VERSION "HNPBNNNYNNNNNNNNNNNNNNNNNNNNNNNNYNYYYYYYYY>4>%%%/4>'%**4YYY///"

NS_ :

BS_:

BU_: ExternalUnit ARS_ISF ARS_ISF1 ARS_ISF2 ARS_ISF3 ARS_ISF4 ARS_ISF5 ARS_ISF6 ARS_ISF7

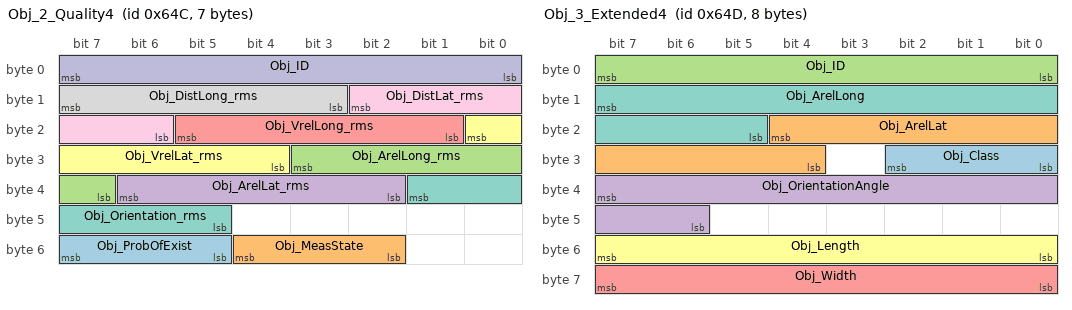
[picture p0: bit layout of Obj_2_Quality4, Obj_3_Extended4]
BO_ 1612 Obj_2_Quality4: 7 ARS_ISF4
 SG_ Obj_ProbOfExist : 55|3@0+ (1,0) [0|7] ""  ExternalUnit
 SG_ Obj_MeasState : 52|3@0+ (1,0) [0|7] ""  ExternalUnit
 SG_ Obj_ArelLong_rms : 27|5@0+ (1,0) [0|31] ""  ExternalUnit
 SG_ Obj_ArelLat_rms : 38|5@0+ (1,0) [0|31] ""  ExternalUnit
 SG_ Obj_VrelLong_rms : 21|5@0+ (1,0) [0|31] ""  ExternalUnit
 SG_ Obj_VrelLat_rms : 16|5@0+ (1,0) [0|31] ""  ExternalUnit
 SG_ Obj_Orientation_rms : 33|5@0+ (1,0) [0|31] ""  ExternalUnit
 SG_ Obj_DistLong_rms : 15|5@0+ (1,0) [0|31] ""  ExternalUnit
 SG_ Obj_DistLat_rms : 10|5@0+ (1,0) [0|31] ""  ExternalUnit
 SG_ Obj_ID : 7|8@0+ (1,0) [0|255] ""  ExternalUnit

BO_ 1613 Obj_3_Extended4: 8 ARS_ISF4
 SG_ Obj_Class : 26|3@0+ (1,0) [0|7] ""  ExternalUnit
 SG_ Obj_ArelLat : 20|9@0+ (0.01,-2.5) [-2.5|2.61] "m/s²"  ExternalUnit
 SG_ Obj_ID : 7|8@0+ (1,0) [0|255] ""  ExternalUnit
 SG_ Obj_OrientationAngle : 39|10@0+ (0.4,-180) [-180|229.2] "deg"  ExternalUnit
 SG_ Obj_Width : 63|8@0+ (0.2,0) [0|51] "m"  ExternalUnit
 SG_ Obj_Length : 55|8@0+ (0.2,0) [0|51] "m"  ExternalUnit
 SG_ Obj_ArelLong : 15|11@0+ (0.01,-10) [-10|10.47] "m/s²"  ExternalUnit

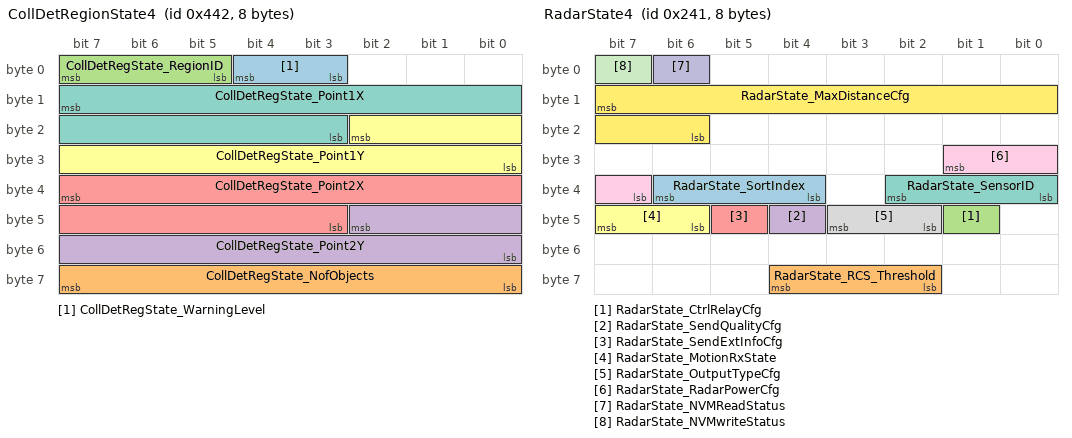
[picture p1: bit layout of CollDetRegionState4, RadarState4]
BO_ 1090 CollDetRegionState4: 8 ARS_ISF4
 SG_ CollDetRegState_WarningLevel : 4|2@0+ (1,0) [0|3] ""  ExternalUnit
 SG_ CollDetRegState_NofObjects : 63|8@0+ (1,0) [0|255] ""  ExternalUnit
 SG_ CollDetRegState_RegionID : 7|3@0+ (1,0) [0|7] ""  ExternalUnit
 SG_ CollDetRegState_Point2Y : 42|11@0+ (0.2,-204.6) [-204.6|204.8] "m"  ExternalUnit
 SG_ CollDetRegState_Point2X : 39|13@0+ (0.2,-500) [-500|1138.2] "m"  ExternalUnit
 SG_ CollDetRegState_Point1Y : 18|11@0+ (0.2,-204.6) [-204.6|204.8] "m"  ExternalUnit
 SG_ CollDetRegState_Point1X : 15|13@0+ (0.2,-500) [-500|1138.2] "m"  ExternalUnit

BO_ 1614 Obj_4_Warning4: 4 ARS_ISF4
 SG_ Obj_CollDetRegionBitfield : 15|8@0+ (1,0) [0|255] ""  ExternalUnit
 SG_ Obj_ID : 7|8@0+ (1,0) [0|255] ""  ExternalUnit

BO_ 580 FilterState_Cfg4: 5 ARS_ISF4
 SG_ FilterState_Max_Class m15 : 39|8@0+ (1,0) [0|255] ""  ExternalUnit
 SG_ FilterState_Min_Class m15 : 23|8@0+ (1,0) [0|255] ""  ExternalUnit
 SG_ FilterState_Min_Y m9 : 11|12@0+ (0.2,-409.5) [-409.5|409.5] "m"  ExternalUnit
 SG_ FilterState_Min_X m10 : 12|13@0+ (0.2,-500) [-500|1138.2] "m"  ExternalUnit
 SG_ FilterState_Min_VYRightLeft m13 : 11|12@0+ (0.0315,0) [0|128.9925] "m/s"  ExternalUnit
 SG_ FilterState_Min_VYLeftRight m11 : 11|12@0+ (0.0315,0) [0|128.9925] "m/s"  ExternalUnit
 SG_ FilterState_Min_VXOncome m12 : 11|12@0+ (0.0315,0) [0|128.9925] "m/s"  ExternalUnit
 SG_ FilterState_Min_VXDepart m14 : 11|12@0+ (0.0315,0) [0|128.9925] "m/s"  ExternalUnit
 SG_ FilterState_Max_Y m9 : 27|12@0+ (0.2,-409.5) [-409.5|409.5] "m"  ExternalUnit
 SG_ FilterState_Max_X m10 : 28|13@0+ (0.2,-500) [-500|1138.2] "m"  ExternalUnit
 SG_ FilterState_Max_VYRightLeft m13 : 27|12@0+ (0.0315,0) [0|128.9925] "m/s"  ExternalUnit
 SG_ FilterState_Max_VYLeftRight m11 : 27|12@0+ (0.0315,0) [0|128.9925] "m/s"  ExternalUnit
 SG_ FilterState_Max_VXOncome m12 : 27|12@0+ (0.0315,0) [0|128.9925] "m/s"  ExternalUnit
 SG_ FilterState_Max_VXDepart m14 : 27|12@0+ (0.0315,0) [0|128.9925] "m/s"  ExternalUnit
 SG_ FilterState_Type : 7|1@0+ (1,0) [0|1] ""  ExternalUnit
 SG_ FilterState_Min_VrelOncome m3 : 11|12@0+ (0.0315,0) [0|128.9925] "m/s"  ExternalUnit
 SG_ FilterState_Min_VrelDepart m4 : 11|12@0+ (0.0315,0) [0|128.9925] "m/s"  ExternalUnit
 SG_ FilterState_Min_Size m7 : 11|12@0+ (0.025,0) [0|102.375] "m2"  ExternalUnit
 SG_ FilterState_Min_RCS m5 : 11|12@0+ (0.025,-50) [-50|52.375] "dB"  ExternalUnit
 SG_ FilterState_Min_ProbExists m8 : 11|12@0+ (1,0) [0|7] ""  ExternalUnit
 SG_ FilterState_Min_NofObj m0 : 11|12@0+ (1,0) [0|4095] ""  ExternalUnit
 SG_ FilterState_Min_Lifetime m6 : 11|12@0+ (0.1,0) [0|409.5] "s"  ExternalUnit
 SG_ FilterState_Min_Distance m1 : 11|12@0+ (0.1,0) [0|409.5] "m"  ExternalUnit
 SG_ FilterState_Min_Azimuth m2 : 11|12@0+ (0.025,-50) [-50|52.375] "deg"  ExternalUnit
 SG_ FilterState_Max_VrelOncome m3 : 27|12@0+ (0.0315,0) [0|128.9925] "m/s"  ExternalUnit
 SG_ FilterState_Max_VrelDepart m4 : 27|12@0+ (0.0315,0) [0|128.9925] "m/s"  ExternalUnit
 SG_ FilterState_Max_Size m7 : 27|12@0+ (0.025,0) [0|102.375] "m2"  ExternalUnit
 SG_ FilterState_Max_RCS m5 : 27|12@0+ (0.025,-50) [-50|52.375] "dB"  ExternalUnit
 SG_ FilterState_Max_ProbExists m8 : 27|12@0+ (1,0) [0|4095] ""  ExternalUnit
 SG_ FilterState_Max_NofObj m0 : 27|12@0+ (1,0) [0|4095] ""  ExternalUnit
 SG_ FilterState_Max_Lifetime m6 : 27|12@0+ (0.1,0) [0|409.5] "s"  ExternalUnit
 SG_ FilterState_Max_Distance m1 : 27|12@0+ (0.1,0) [0|409.5] "m"  ExternalUnit
 SG_ FilterState_Max_Azimuth m2 : 27|12@0+ (0.025,-50) [-50|52.375] "deg"  ExternalUnit
 SG_ FilterState_Index M : 6|4@0+ (1,0) [0|15] ""  ExternalUnit
 SG_ FilterState_Active : 2|1@0+ (1,0) [0|1] ""  ExternalUnit

BO_ 579 FilterState_Header4: 2 ARS_ISF4
 SG_ FilterState_NofObjectFilterCfg : 15|5@0+ (1,0) [0|31] ""  ExternalUnit
 SG_ FilterState_NofClusterFilterCfg : 7|5@0+ (1,0) [0|31] ""  ExternalUnit

BO_ 578 FilterCfg4: 5 ExternalUnit
 SG_ FilterCfg_Min_Class m15 : 23|8@0+ (1,0) [0|255] ""  ARS_ISF4
 SG_ FilterCfg_Max_Class m15 : 39|8@0+ (1,0) [0|255] ""  ARS_ISF4
 SG_ FilterCfg_Min_Y m9 : 11|12@0+ (0.2,-409.5) [-409.5|409.5] "m"  ARS_ISF4
 SG_ FilterCfg_Min_X m10 : 12|13@0+ (0.2,-500) [-500|1138.2] "m"  ARS_ISF4
 SG_ FilterCfg_Min_VYRightLeft m13 : 11|12@0+ (0.0315,0) [0|128.9925] "m/s"  ARS_ISF4
 SG_ FilterCfg_Min_VYLeftRight m11 : 11|12@0+ (0.0315,0) [0|128.9925] "m/s"  ARS_ISF4
 SG_ FilterCfg_Min_VXOncome m12 : 11|12@0+ (0.0315,0) [0|128.9925] "m/s"  ARS_ISF4
 SG_ FilterCfg_Min_VXDepart m14 : 11|12@0+ (0.0315,0) [0|128.9925] "m/s"  ARS_ISF4
 SG_ FilterCfg_Max_Y m9 : 27|12@0+ (0.2,-409.5) [-409.5|409.5] "m"  ARS_ISF4
 SG_ FilterCfg_Max_X m10 : 28|13@0+ (0.2,-500) [-500|1138.2] "m"  ARS_ISF4
 SG_ FilterCfg_Max_VYRightLeft m13 : 27|12@0+ (0.0315,0) [0|128.9925] "m/s"  ARS_ISF4
 SG_ FilterCfg_Max_VXOncome m12 : 27|12@0+ (0.0315,0) [0|128.9925] "m/s"  ARS_ISF4
 SG_ FilterCfg_Max_VYLeftRight m11 : 27|12@0+ (0.0315,0) [0|128.9925] "m/s"  ARS_ISF4
 SG_ FilterCfg_Max_VXDepart m14 : 27|12@0+ (0.0315,0) [0|128.9925] "m/s"  ARS_ISF4
 SG_ FilterCfg_Valid : 1|1@0+ (1,0) [0|1] ""  ARS_ISF4
 SG_ FilterCfg_Active : 2|1@0+ (1,0) [0|1] ""  ARS_ISF4
 SG_ FilterCfg_Max_VrelOncome m3 : 27|12@0+ (0.0315,0) [0|128.9925] "m/s"  ARS_ISF4
 SG_ FilterCfg_Max_VrelDepart m4 : 27|12@0+ (0.0315,0) [0|128.9925] "m/s"  ARS_ISF4
 SG_ FilterCfg_Max_Size m7 : 27|12@0+ (0.025,0) [0|102.375] "m2"  ARS_ISF4
 SG_ FilterCfg_Max_RCS m5 : 27|12@0+ (0.025,-50) [-50|52.375] "dB"  ARS_ISF4
 SG_ FilterCfg_Max_ProbExists m8 : 27|12@0+ (1,0) [0|7] ""  ARS_ISF4
 SG_ FilterCfg_Max_NofObj m0 : 27|12@0+ (1,0) [0|4095] ""  ARS_ISF4
 SG_ FilterCfg_Max_Lifetime m6 : 27|12@0+ (0.1,0) [0|409.5] "s"  ARS_ISF4
 SG_ FilterCfg_Max_Distance m1 : 27|12@0+ (0.1,0) [0|409.5] "m"  ARS_ISF4
 SG_ FilterCfg_Max_Azimuth m2 : 27|12@0+ (0.025,-50) [-50|52.375] "deg"  ARS_ISF4
 SG_ FilterCfg_Min_VrelOncome m3 : 11|12@0+ (0.0315,0) [0|128.9925] "m/s"  ARS_ISF4
 SG_ FilterCfg_Min_VrelDepart m4 : 11|12@0+ (0.0315,0) [0|128.9925] "m/s"  ARS_ISF4
 SG_ FilterCfg_Min_Size m7 : 11|12@0+ (0.025,0) [0|102.375] "m2"  ARS_ISF4
 SG_ FilterCfg_Min_RCS m5 : 11|12@0+ (0.025,-50) [-50|52.375] "dB"  ARS_ISF4
 SG_ FilterCfg_Min_ProbExists m8 : 11|12@0+ (1,0) [0|4095] ""  ARS_ISF4
 SG_ FilterCfg_Min_Lifetime m6 : 11|12@0+ (0.1,0) [0|409.5] "s"  ARS_ISF4
 SG_ FilterCfg_Min_Azimuth m2 : 11|12@0+ (0.025,-50) [-50|52.375] "deg"  ARS_ISF4
 SG_ FilterCfg_Min_NofObj m0 : 11|12@0+ (1,0) [0|4095] ""  ARS_ISF4
 SG_ FilterCfg_Min_Distance m1 : 11|12@0+ (0.1,0) [0|409.5] "m"  ARS_ISF4
 SG_ FilterCfg_Index M : 6|4@0+ (1,0) [0|15] ""  ARS_ISF4
 SG_ FilterCfg_Type : 7|1@0+ (1,0) [0|1] ""  ARS_ISF4

BO_ 576 RadarConfiguration4: 8 ExternalUnit
 SG_ RadarCfg_RCS_Threshold_Valid : 48|1@0+ (1,0) [0|1] "" Vector__XXX
 SG_ RadarCfg_RCS_Threshold : 51|3@0+ (1,0) [0|7] "" Vector__XXX
 SG_ RadarCfg_StoreInNVM_valid : 7|1@0+ (1,0) [0|1] "" Vector__XXX
 SG_ RadarCfg_SortIndex_valid : 6|1@0+ (1,0) [0|1] "" Vector__XXX
 SG_ RadarCfg_SortIndex : 46|3@0+ (1,0) [0|7] "" Vector__XXX
 SG_ RadarCfg_StoreInNVM : 47|1@0+ (1,0) [0|1] ""  ARS_ISF4
 SG_ RadarCfg_SendExtInfo_valid : 5|1@0+ (1,0) [0|1] ""  ARS_ISF4
 SG_ RadarCfg_SendExtInfo : 43|1@0+ (1,0) [0|1] ""  ARS_ISF4
 SG_ RadarCfg_CtrlRelay_valid : 40|1@0+ (1,0) [0|1] ""  ARS_ISF4
 SG_ RadarCfg_CtrlRelay : 41|1@0+ (1,0) [0|1] ""  ARS_ISF4
 SG_ RadarCfg_SendQuality_valid : 4|1@0+ (1,0) [0|1] ""  ARS_ISF4
 SG_ RadarCfg_SendQuality : 42|1@0+ (1,0) [0|1] ""  ARS_ISF4
 SG_ RadarCfg_MaxDistance_valid : 0|1@0+ (1,0) [0|1] ""  ARS_ISF4
 SG_ RadarCfg_RadarPower_valid : 2|1@0+ (1,0) [0|1] ""  ARS_ISF4
 SG_ RadarCfg_OutputType_valid : 3|1@0+ (1,0) [0|1] ""  ARS_ISF4
 SG_ RadarCfg_SensorID_valid : 1|1@0+ (1,0) [0|1] ""  ARS_ISF4
 SG_ RadarCfg_MaxDistance : 15|10@0+ (2,0) [0|2046] "m"  ARS_ISF4
 SG_ RadarCfg_RadarPower : 39|3@0+ (1,0) [0|7] ""  ARS_ISF4
 SG_ RadarCfg_OutputType : 36|2@0+ (1,0) [0|2] ""  ARS_ISF4
 SG_ RadarCfg_SensorID : 34|3@0+ (1,0) [0|7] ""  ARS_ISF4

BO_ 577 RadarState4: 8 ARS_ISF4
 SG_ RadarState_SortIndex : 38|3@0+ (1,0) [0|0] "" Vector__XXX
 SG_ RadarState_RCS_Threshold : 60|3@0+ (1,0) [0|7] "" Vector__XXX
 SG_ RadarState_CtrlRelayCfg : 41|1@0+ (1,0) [0|1] ""  ExternalUnit
 SG_ RadarState_SendQualityCfg : 44|1@0+ (1,0) [0|1] ""  ExternalUnit
 SG_ RadarState_SendExtInfoCfg : 45|1@0+ (1,0) [0|1] ""  ExternalUnit
 SG_ RadarState_MotionRxState : 47|2@0+ (1,0) [0|3] ""  ExternalUnit
 SG_ RadarState_SensorID : 34|3@0+ (1,0) [0|7] ""  ExternalUnit
 SG_ RadarState_OutputTypeCfg : 43|2@0+ (1,0) [0|3] ""  ExternalUnit
 SG_ RadarState_RadarPowerCfg : 25|3@0+ (1,0) [0|7] ""  ExternalUnit
 SG_ RadarState_NVMReadStatus : 6|1@0+ (1,0) [0|1] ""  ExternalUnit
 SG_ RadarState_NVMwriteStatus : 7|1@0+ (1,0) [0|1] ""  ExternalUnit
 SG_ RadarState_MaxDistanceCfg : 15|10@0+ (2,0) [0|2046] ""  ExternalUnit

BO_ 832 SpeedInformation4: 2 ExternalUnit
 SG_ RadarDevice_Speed : 4|13@0+ (0.02,0) [0|163.8] "m/s"  ARS_ISF4
 SG_ RadarDevice_SpeedDirection : 7|2@0+ (1,0) [0|2] ""  ARS_ISF4

BO_ 833 YawRateInformation4: 2 ExternalUnit
 SG_ RadarDevice_YawRate : 7|16@0+ (0.01,-327.68) [-327.68|327.66] "°/s"  ARS_ISF4

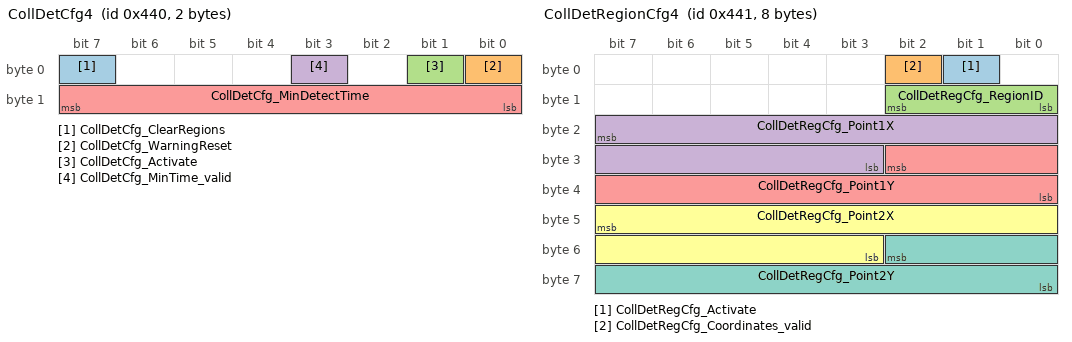
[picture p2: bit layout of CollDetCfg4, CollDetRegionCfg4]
BO_ 1088 CollDetCfg4: 2 ExternalUnit
 SG_ CollDetCfg_ClearRegions : 7|1@0+ (1,0) [0|1] ""  ARS_ISF4
 SG_ CollDetCfg_WarningReset : 0|1@0+ (1,0) [0|1] ""  ARS_ISF4
 SG_ CollDetCfg_Activate : 1|1@0+ (1,0) [0|1] ""  ARS_ISF4
 SG_ CollDetCfg_MinTime_valid : 3|1@0+ (1,0) [0|1] ""  ARS_ISF4
 SG_ CollDetCfg_MinDetectTime : 15|8@0+ (0.1,0) [0|25.5] "s"  ARS_ISF4

BO_ 1089 CollDetRegionCfg4: 8 ExternalUnit
 SG_ CollDetRegCfg_Activate : 1|1@0+ (1,0) [0|1] ""  ARS_ISF4
 SG_ CollDetRegCfg_Coordinates_valid : 2|1@0+ (1,0) [0|1] ""  ARS_ISF4
 SG_ CollDetRegCfg_RegionID : 10|3@0+ (1,0) [0|7] ""  ARS_ISF4
 SG_ CollDetRegCfg_Point1X : 23|13@0+ (0.2,-500) [-500|1138.2] "m"  ARS_ISF4
 SG_ CollDetRegCfg_Point1Y : 26|11@0+ (0.2,-204.6) [-204.6|204.8] "m"  ARS_ISF4
 SG_ CollDetRegCfg_Point2X : 47|13@0+ (0.2,-500) [-500|1138.2] "m"  ARS_ISF4
 SG_ CollDetRegCfg_Point2Y : 50|11@0+ (0.2,-204.6) [-204.6|204.8] "m"  ARS_ISF4

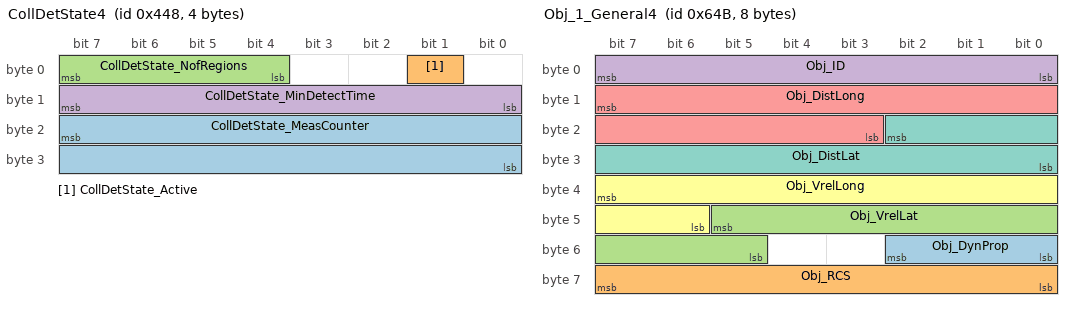
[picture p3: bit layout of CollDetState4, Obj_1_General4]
BO_ 1096 CollDetState4: 4 ARS_ISF4
 SG_ CollDetState_MeasCounter : 23|16@0+ (1,0) [0|65535] "" Vector__XXX
 SG_ CollDetState_Active : 1|1@0+ (1,0) [0|1] "" Vector__XXX
 SG_ CollDetState_NofRegions : 7|4@0+ (1,0) [0|15] ""  ExternalUnit
 SG_ CollDetState_MinDetectTime : 15|8@0+ (0.1,0) [0|25.5] "s"  ExternalUnit

BO_ 1600 Cluster_0_Status4: 5 ARS_ISF4
 SG_ Cluster_MeasCounter : 23|16@0+ (1,0) [0|65535] ""  ExternalUnit
 SG_ Cluster_NofClustersNear : 7|8@0+ (1,0) [0|255] ""  ExternalUnit
 SG_ Cluster_NofClustersFar : 15|8@0+ (1,0) [0|255] ""  ExternalUnit
 SG_ Cluster_InterfaceVersion : 39|4@0+ (1,0) [0|15] ""  ExternalUnit

BO_ 1610 Obj_0_Status4: 4 ARS_ISF4
 SG_ Obj_NofObjects : 7|8@0+ (1,0) [0|255] "1"  ExternalUnit
 SG_ Obj_MeasCounter : 15|16@0+ (1,0) [0|65535] ""  ExternalUnit
 SG_ Obj_InterfaceVersion : 31|4@0+ (1,0) [0|16] ""  ExternalUnit

BO_ 1611 Obj_1_General4: 8 ARS_ISF4
 SG_ Obj_DynProp : 50|3@0+ (1,0) [0|7] ""  ExternalUnit
 SG_ Obj_RCS : 63|8@0+ (0.5,-64) [-64|63.5] "dBm²"  ExternalUnit
 SG_ Obj_VrelLat : 45|9@0+ (0.25,-64) [-64|63.75] "m/s"  ExternalUnit
 SG_ Obj_ID : 7|8@0+ (1,0) [0|255] ""  ExternalUnit
 SG_ Obj_DistLong : 15|13@0+ (0.2,-500) [-500|1138.2] "m"  ExternalUnit
 SG_ Obj_VrelLong : 39|10@0+ (0.25,-128) [-128|127.75] "m/s"  ExternalUnit
 SG_ Obj_DistLat : 18|11@0+ (0.2,-204.6) [-204.6|204.8] "m"  ExternalUnit

BO_ 1856 VersionID4: 3 ARS_ISF4
 SG_ Version_MajorRelease : 7|8@0+ (1,0) [0|256] ""  ExternalUnit
 SG_ Version_MinorRelease : 15|8@0+ (1,0) [0|256] ""  ExternalUnit
 SG_ Version_PatchLevel : 23|8@0+ (1,0) [0|256] ""  ExternalUnit

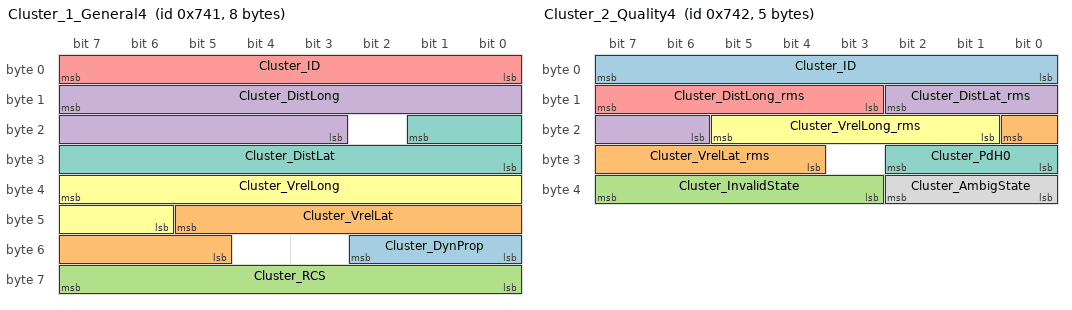
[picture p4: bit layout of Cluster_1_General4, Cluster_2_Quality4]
BO_ 1857 Cluster_1_General4: 8 ARS_ISF4
 SG_ Cluster_DynProp : 50|3@0+ (1,0) [0|7] "1"  ExternalUnit
 SG_ Cluster_VrelLat : 45|9@0+ (0.25,-64) [-64|63.75] "m/s"  ExternalUnit
 SG_ Cluster_RCS : 63|8@0+ (0.5,-64) [-64|63.5] "dBm²"  ExternalUnit
 SG_ Cluster_DistLong : 15|13@0+ (0.2,-500) [-500|1138.2] "m"  ExternalUnit
 SG_ Cluster_ID : 7|8@0+ (1,0) [0|255] "1"  ExternalUnit
 SG_ Cluster_VrelLong : 39|10@0+ (0.25,-128) [-128|127.75] "m/s"  ExternalUnit
 SG_ Cluster_DistLat : 17|10@0+ (0.2,-102.3) [-102.3|102.3] "m"  ExternalUnit

BO_ 1858 Cluster_2_Quality4: 5 ARS_ISF4
 SG_ Cluster_ID : 7|8@0+ (1,0) [0|255] "1"  ExternalUnit
 SG_ Cluster_VrelLat_rms : 16|5@0+ (1,0) [0|31] "m/s"  ExternalUnit
 SG_ Cluster_InvalidState : 39|5@0+ (1,0) [0|31] ""  ExternalUnit
 SG_ Cluster_DistLat_rms : 10|5@0+ (1,0) [0|31] "m"  ExternalUnit
 SG_ Cluster_DistLong_rms : 15|5@0+ (1,0) [0|31] "m"  ExternalUnit
 SG_ Cluster_VrelLong_rms : 21|5@0+ (1,0) [0|31] "m/s"  ExternalUnit
 SG_ Cluster_PdH0 : 26|3@0+ (1,0) [0|7] ""  ExternalUnit
 SG_ Cluster_AmbigState : 34|3@0+ (1,0) [0|7] "1"  ExternalUnit

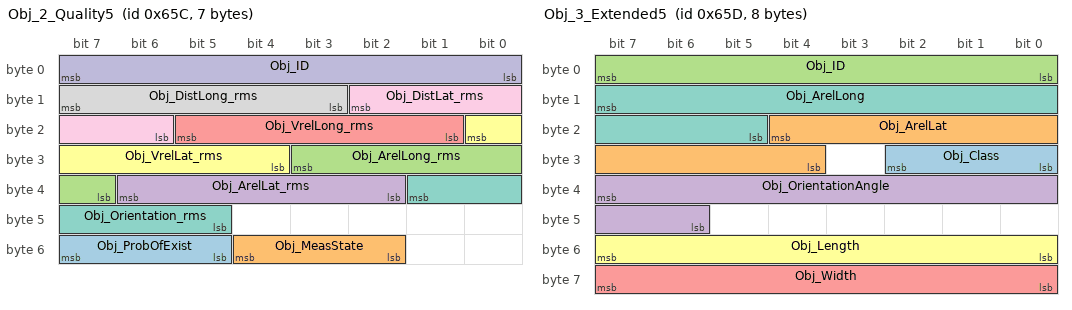
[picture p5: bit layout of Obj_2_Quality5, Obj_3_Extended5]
BO_ 1628 Obj_2_Quality5: 7 ARS_ISF5
 SG_ Obj_ProbOfExist : 55|3@0+ (1,0) [0|7] ""  ExternalUnit
 SG_ Obj_MeasState : 52|3@0+ (1,0) [0|7] ""  ExternalUnit
 SG_ Obj_ArelLong_rms : 27|5@0+ (1,0) [0|31] ""  ExternalUnit
 SG_ Obj_ArelLat_rms : 38|5@0+ (1,0) [0|31] ""  ExternalUnit
 SG_ Obj_VrelLong_rms : 21|5@0+ (1,0) [0|31] ""  ExternalUnit
 SG_ Obj_VrelLat_rms : 16|5@0+ (1,0) [0|31] ""  ExternalUnit
 SG_ Obj_Orientation_rms : 33|5@0+ (1,0) [0|31] ""  ExternalUnit
 SG_ Obj_DistLong_rms : 15|5@0+ (1,0) [0|31] ""  ExternalUnit
 SG_ Obj_DistLat_rms : 10|5@0+ (1,0) [0|31] ""  ExternalUnit
 SG_ Obj_ID : 7|8@0+ (1,0) [0|255] ""  ExternalUnit

BO_ 1629 Obj_3_Extended5: 8 ARS_ISF5
 SG_ Obj_Class : 26|3@0+ (1,0) [0|7] ""  ExternalUnit
 SG_ Obj_ArelLat : 20|9@0+ (0.01,-2.5) [-2.5|2.61] "m/s²"  ExternalUnit
 SG_ Obj_ID : 7|8@0+ (1,0) [0|255] ""  ExternalUnit
 SG_ Obj_OrientationAngle : 39|10@0+ (0.4,-180) [-180|229.2] "deg"  ExternalUnit
 SG_ Obj_Width : 63|8@0+ (0.2,0) [0|51] "m"  ExternalUnit
 SG_ Obj_Length : 55|8@0+ (0.2,0) [0|51] "m"  ExternalUnit
 SG_ Obj_ArelLong : 15|11@0+ (0.01,-10) [-10|10.47] "m/s²"  ExternalUnit

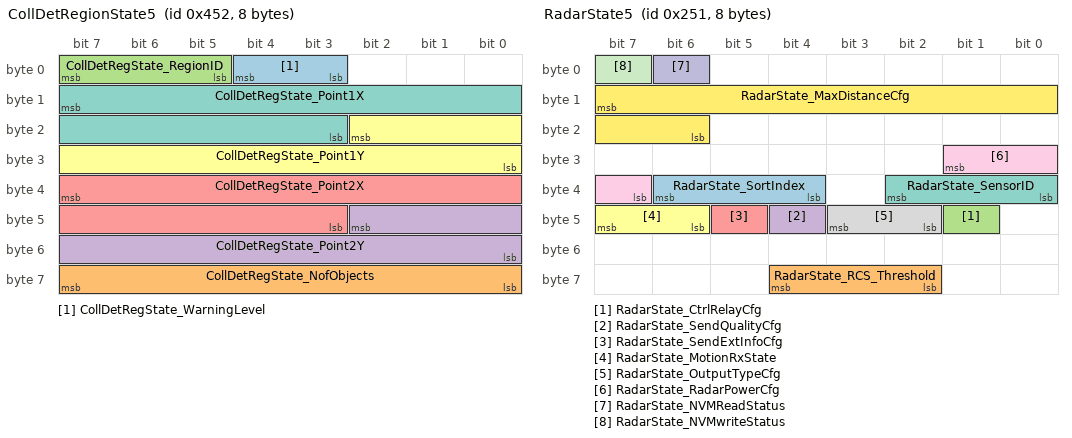
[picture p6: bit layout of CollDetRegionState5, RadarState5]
BO_ 1106 CollDetRegionState5: 8 ARS_ISF5
 SG_ CollDetRegState_WarningLevel : 4|2@0+ (1,0) [0|3] ""  ExternalUnit
 SG_ CollDetRegState_NofObjects : 63|8@0+ (1,0) [0|255] ""  ExternalUnit
 SG_ CollDetRegState_RegionID : 7|3@0+ (1,0) [0|7] ""  ExternalUnit
 SG_ CollDetRegState_Point2Y : 42|11@0+ (0.2,-204.6) [-204.6|204.8] "m"  ExternalUnit
 SG_ CollDetRegState_Point2X : 39|13@0+ (0.2,-500) [-500|1138.2] "m"  ExternalUnit
 SG_ CollDetRegState_Point1Y : 18|11@0+ (0.2,-204.6) [-204.6|204.8] "m"  ExternalUnit
 SG_ CollDetRegState_Point1X : 15|13@0+ (0.2,-500) [-500|1138.2] "m"  ExternalUnit

BO_ 1630 Obj_4_Warning5: 4 ARS_ISF5
 SG_ Obj_CollDetRegionBitfield : 15|8@0+ (1,0) [0|255] ""  ExternalUnit
 SG_ Obj_ID : 7|8@0+ (1,0) [0|255] ""  ExternalUnit

BO_ 596 FilterState_Cfg5: 5 ARS_ISF5
 SG_ FilterState_Max_Class m15 : 39|8@0+ (1,0) [0|255] ""  ExternalUnit
 SG_ FilterState_Min_Class m15 : 23|8@0+ (1,0) [0|255] ""  ExternalUnit
 SG_ FilterState_Min_Y m9 : 11|12@0+ (0.2,-409.5) [-409.5|409.5] "m"  ExternalUnit
 SG_ FilterState_Min_X m10 : 12|13@0+ (0.2,-500) [-500|1138.2] "m"  ExternalUnit
 SG_ FilterState_Min_VYRightLeft m13 : 11|12@0+ (0.0315,0) [0|128.9925] "m/s"  ExternalUnit
 SG_ FilterState_Min_VYLeftRight m11 : 11|12@0+ (0.0315,0) [0|128.9925] "m/s"  ExternalUnit
 SG_ FilterState_Min_VXOncome m12 : 11|12@0+ (0.0315,0) [0|128.9925] "m/s"  ExternalUnit
 SG_ FilterState_Min_VXDepart m14 : 11|12@0+ (0.0315,0) [0|128.9925] "m/s"  ExternalUnit
 SG_ FilterState_Max_Y m9 : 27|12@0+ (0.2,-409.5) [-409.5|409.5] "m"  ExternalUnit
 SG_ FilterState_Max_X m10 : 28|13@0+ (0.2,-500) [-500|1138.2] "m"  ExternalUnit
 SG_ FilterState_Max_VYRightLeft m13 : 27|12@0+ (0.0315,0) [0|128.9925] "m/s"  ExternalUnit
 SG_ FilterState_Max_VYLeftRight m11 : 27|12@0+ (0.0315,0) [0|128.9925] "m/s"  ExternalUnit
 SG_ FilterState_Max_VXOncome m12 : 27|12@0+ (0.0315,0) [0|128.9925] "m/s"  ExternalUnit
 SG_ FilterState_Max_VXDepart m14 : 27|12@0+ (0.0315,0) [0|128.9925] "m/s"  ExternalUnit
 SG_ FilterState_Type : 7|1@0+ (1,0) [0|1] ""  ExternalUnit
 SG_ FilterState_Min_VrelOncome m3 : 11|12@0+ (0.0315,0) [0|128.9925] "m/s"  ExternalUnit
 SG_ FilterState_Min_VrelDepart m4 : 11|12@0+ (0.0315,0) [0|128.9925] "m/s"  ExternalUnit
 SG_ FilterState_Min_Size m7 : 11|12@0+ (0.025,0) [0|102.375] "m2"  ExternalUnit
 SG_ FilterState_Min_RCS m5 : 11|12@0+ (0.025,-50) [-50|52.375] "dB"  ExternalUnit
 SG_ FilterState_Min_ProbExists m8 : 11|12@0+ (1,0) [0|7] ""  ExternalUnit
 SG_ FilterState_Min_NofObj m0 : 11|12@0+ (1,0) [0|4095] ""  ExternalUnit
 SG_ FilterState_Min_Lifetime m6 : 11|12@0+ (0.1,0) [0|409.5] "s"  ExternalUnit
 SG_ FilterState_Min_Distance m1 : 11|12@0+ (0.1,0) [0|409.5] "m"  ExternalUnit
 SG_ FilterState_Min_Azimuth m2 : 11|12@0+ (0.025,-50) [-50|52.375] "deg"  ExternalUnit
 SG_ FilterState_Max_VrelOncome m3 : 27|12@0+ (0.0315,0) [0|128.9925] "m/s"  ExternalUnit
 SG_ FilterState_Max_VrelDepart m4 : 27|12@0+ (0.0315,0) [0|128.9925] "m/s"  ExternalUnit
 SG_ FilterState_Max_Size m7 : 27|12@0+ (0.025,0) [0|102.375] "m2"  ExternalUnit
 SG_ FilterState_Max_RCS m5 : 27|12@0+ (0.025,-50) [-50|52.375] "dB"  ExternalUnit
 SG_ FilterState_Max_ProbExists m8 : 27|12@0+ (1,0) [0|4095] ""  ExternalUnit
 SG_ FilterState_Max_NofObj m0 : 27|12@0+ (1,0) [0|4095] ""  ExternalUnit
 SG_ FilterState_Max_Lifetime m6 : 27|12@0+ (0.1,0) [0|409.5] "s"  ExternalUnit
 SG_ FilterState_Max_Distance m1 : 27|12@0+ (0.1,0) [0|409.5] "m"  ExternalUnit
 SG_ FilterState_Max_Azimuth m2 : 27|12@0+ (0.025,-50) [-50|52.375] "deg"  ExternalUnit
 SG_ FilterState_Index M : 6|4@0+ (1,0) [0|15] ""  ExternalUnit
 SG_ FilterState_Active : 2|1@0+ (1,0) [0|1] ""  ExternalUnit

BO_ 595 FilterState_Header5: 2 ARS_ISF5
 SG_ FilterState_NofObjectFilterCfg : 15|5@0+ (1,0) [0|31] ""  ExternalUnit
 SG_ FilterState_NofClusterFilterCfg : 7|5@0+ (1,0) [0|31] ""  ExternalUnit

BO_ 594 FilterCfg5: 5 ExternalUnit
 SG_ FilterCfg_Min_Class m15 : 23|8@0+ (1,0) [0|255] ""  ARS_ISF5
 SG_ FilterCfg_Max_Class m15 : 39|8@0+ (1,0) [0|255] ""  ARS_ISF5
 SG_ FilterCfg_Min_Y m9 : 11|12@0+ (0.2,-409.5) [-409.5|409.5] "m"  ARS_ISF5
 SG_ FilterCfg_Min_X m10 : 12|13@0+ (0.2,-500) [-500|1138.2] "m"  ARS_ISF5
 SG_ FilterCfg_Min_VYRightLeft m13 : 11|12@0+ (0.0315,0) [0|128.9925] "m/s"  ARS_ISF5
 SG_ FilterCfg_Min_VYLeftRight m11 : 11|12@0+ (0.0315,0) [0|128.9925] "m/s"  ARS_ISF5
 SG_ FilterCfg_Min_VXOncome m12 : 11|12@0+ (0.0315,0) [0|128.9925] "m/s"  ARS_ISF5
 SG_ FilterCfg_Min_VXDepart m14 : 11|12@0+ (0.0315,0) [0|128.9925] "m/s"  ARS_ISF5
 SG_ FilterCfg_Max_Y m9 : 27|12@0+ (0.2,-409.5) [-409.5|409.5] "m"  ARS_ISF5
 SG_ FilterCfg_Max_X m10 : 28|13@0+ (0.2,-500) [-500|1138.2] "m"  ARS_ISF5
 SG_ FilterCfg_Max_VYRightLeft m13 : 27|12@0+ (0.0315,0) [0|128.9925] "m/s"  ARS_ISF5
 SG_ FilterCfg_Max_VXOncome m12 : 27|12@0+ (0.0315,0) [0|128.9925] "m/s"  ARS_ISF5
 SG_ FilterCfg_Max_VYLeftRight m11 : 27|12@0+ (0.0315,0) [0|128.9925] "m/s"  ARS_ISF5
 SG_ FilterCfg_Max_VXDepart m14 : 27|12@0+ (0.0315,0) [0|128.9925] "m/s"  ARS_ISF5
 SG_ FilterCfg_Valid : 1|1@0+ (1,0) [0|1] ""  ARS_ISF5
 SG_ FilterCfg_Active : 2|1@0+ (1,0) [0|1] ""  ARS_ISF5
 SG_ FilterCfg_Max_VrelOncome m3 : 27|12@0+ (0.0315,0) [0|128.9925] "m/s"  ARS_ISF5
 SG_ FilterCfg_Max_VrelDepart m4 : 27|12@0+ (0.0315,0) [0|128.9925] "m/s"  ARS_ISF5
 SG_ FilterCfg_Max_Size m7 : 27|12@0+ (0.025,0) [0|102.375] "m2"  ARS_ISF5
 SG_ FilterCfg_Max_RCS m5 : 27|12@0+ (0.025,-50) [-50|52.375] "dB"  ARS_ISF5
 SG_ FilterCfg_Max_ProbExists m8 : 27|12@0+ (1,0) [0|7] ""  ARS_ISF5
 SG_ FilterCfg_Max_NofObj m0 : 27|12@0+ (1,0) [0|4095] ""  ARS_ISF5
 SG_ FilterCfg_Max_Lifetime m6 : 27|12@0+ (0.1,0) [0|409.5] "s"  ARS_ISF5
 SG_ FilterCfg_Max_Distance m1 : 27|12@0+ (0.1,0) [0|409.5] "m"  ARS_ISF5
 SG_ FilterCfg_Max_Azimuth m2 : 27|12@0+ (0.025,-50) [-50|52.375] "deg"  ARS_ISF5
 SG_ FilterCfg_Min_VrelOncome m3 : 11|12@0+ (0.0315,0) [0|128.9925] "m/s"  ARS_ISF5
 SG_ FilterCfg_Min_VrelDepart m4 : 11|12@0+ (0.0315,0) [0|128.9925] "m/s"  ARS_ISF5
 SG_ FilterCfg_Min_Size m7 : 11|12@0+ (0.025,0) [0|102.375] "m2"  ARS_ISF5
 SG_ FilterCfg_Min_RCS m5 : 11|12@0+ (0.025,-50) [-50|52.375] "dB"  ARS_ISF5
 SG_ FilterCfg_Min_ProbExists m8 : 11|12@0+ (1,0) [0|4095] ""  ARS_ISF5
 SG_ FilterCfg_Min_Lifetime m6 : 11|12@0+ (0.1,0) [0|409.5] "s"  ARS_ISF5
 SG_ FilterCfg_Min_Azimuth m2 : 11|12@0+ (0.025,-50) [-50|52.375] "deg"  ARS_ISF5
 SG_ FilterCfg_Min_NofObj m0 : 11|12@0+ (1,0) [0|4095] ""  ARS_ISF5
 SG_ FilterCfg_Min_Distance m1 : 11|12@0+ (0.1,0) [0|409.5] "m"  ARS_ISF5
 SG_ FilterCfg_Index M : 6|4@0+ (1,0) [0|15] ""  ARS_ISF5
 SG_ FilterCfg_Type : 7|1@0+ (1,0) [0|1] ""  ARS_ISF5

BO_ 592 RadarConfiguration5: 8 ExternalUnit
 SG_ RadarCfg_RCS_Threshold_Valid : 48|1@0+ (1,0) [0|1] "" Vector__XXX
 SG_ RadarCfg_RCS_Threshold : 51|3@0+ (1,0) [0|7] "" Vector__XXX
 SG_ RadarCfg_StoreInNVM_valid : 7|1@0+ (1,0) [0|1] "" Vector__XXX
 SG_ RadarCfg_SortIndex_valid : 6|1@0+ (1,0) [0|1] "" Vector__XXX
 SG_ RadarCfg_SortIndex : 46|3@0+ (1,0) [0|7] "" Vector__XXX
 SG_ RadarCfg_StoreInNVM : 47|1@0+ (1,0) [0|1] ""  ARS_ISF5
 SG_ RadarCfg_SendExtInfo_valid : 5|1@0+ (1,0) [0|1] ""  ARS_ISF5
 SG_ RadarCfg_SendExtInfo : 43|1@0+ (1,0) [0|1] ""  ARS_ISF5
 SG_ RadarCfg_CtrlRelay_valid : 40|1@0+ (1,0) [0|1] ""  ARS_ISF5
 SG_ RadarCfg_CtrlRelay : 41|1@0+ (1,0) [0|1] ""  ARS_ISF5
 SG_ RadarCfg_SendQuality_valid : 4|1@0+ (1,0) [0|1] ""  ARS_ISF5
 SG_ RadarCfg_SendQuality : 42|1@0+ (1,0) [0|1] ""  ARS_ISF5
 SG_ RadarCfg_MaxDistance_valid : 0|1@0+ (1,0) [0|1] ""  ARS_ISF5
 SG_ RadarCfg_RadarPower_valid : 2|1@0+ (1,0) [0|1] ""  ARS_ISF5
 SG_ RadarCfg_OutputType_valid : 3|1@0+ (1,0) [0|1] ""  ARS_ISF5
 SG_ RadarCfg_SensorID_valid : 1|1@0+ (1,0) [0|1] ""  ARS_ISF5
 SG_ RadarCfg_MaxDistance : 15|10@0+ (2,0) [0|2046] "m"  ARS_ISF5
 SG_ RadarCfg_RadarPower : 39|3@0+ (1,0) [0|7] ""  ARS_ISF5
 SG_ RadarCfg_OutputType : 36|2@0+ (1,0) [0|2] ""  ARS_ISF5
 SG_ RadarCfg_SensorID : 34|3@0+ (1,0) [0|7] ""  ARS_ISF5

BO_ 593 RadarState5: 8 ARS_ISF5
 SG_ RadarState_SortIndex : 38|3@0+ (1,0) [0|0] "" Vector__XXX
 SG_ RadarState_RCS_Threshold : 60|3@0+ (1,0) [0|7] "" Vector__XXX
 SG_ RadarState_CtrlRelayCfg : 41|1@0+ (1,0) [0|1] ""  ExternalUnit
 SG_ RadarState_SendQualityCfg : 44|1@0+ (1,0) [0|1] ""  ExternalUnit
 SG_ RadarState_SendExtInfoCfg : 45|1@0+ (1,0) [0|1] ""  ExternalUnit
 SG_ RadarState_MotionRxState : 47|2@0+ (1,0) [0|3] ""  ExternalUnit
 SG_ RadarState_SensorID : 34|3@0+ (1,0) [0|7] ""  ExternalUnit
 SG_ RadarState_OutputTypeCfg : 43|2@0+ (1,0) [0|3] ""  ExternalUnit
 SG_ RadarState_RadarPowerCfg : 25|3@0+ (1,0) [0|7] ""  ExternalUnit
 SG_ RadarState_NVMReadStatus : 6|1@0+ (1,0) [0|1] ""  ExternalUnit
 SG_ RadarState_NVMwriteStatus : 7|1@0+ (1,0) [0|1] ""  ExternalUnit
 SG_ RadarState_MaxDistanceCfg : 15|10@0+ (2,0) [0|2046] ""  ExternalUnit

BO_ 848 SpeedInformation5: 2 ExternalUnit
 SG_ RadarDevice_Speed : 4|13@0+ (0.02,0) [0|163.8] "m/s"  ARS_ISF5
 SG_ RadarDevice_SpeedDirection : 7|2@0+ (1,0) [0|2] ""  ARS_ISF5

BO_ 849 YawRateInformation5: 2 ExternalUnit
 SG_ RadarDevice_YawRate : 7|16@0+ (0.01,-327.68) [-327.68|327.66] "°/s"  ARS_ISF5

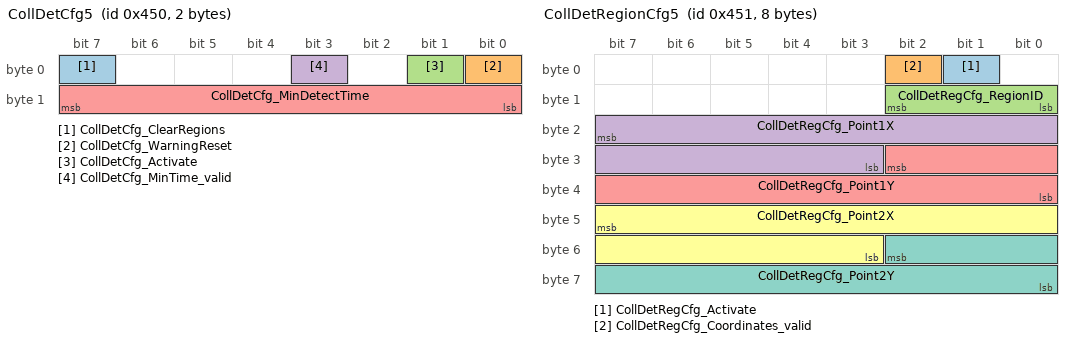
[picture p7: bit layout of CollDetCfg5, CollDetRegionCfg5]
BO_ 1104 CollDetCfg5: 2 ExternalUnit
 SG_ CollDetCfg_ClearRegions : 7|1@0+ (1,0) [0|1] ""  ARS_ISF5
 SG_ CollDetCfg_WarningReset : 0|1@0+ (1,0) [0|1] ""  ARS_ISF5
 SG_ CollDetCfg_Activate : 1|1@0+ (1,0) [0|1] ""  ARS_ISF5
 SG_ CollDetCfg_MinTime_valid : 3|1@0+ (1,0) [0|1] ""  ARS_ISF5
 SG_ CollDetCfg_MinDetectTime : 15|8@0+ (0.1,0) [0|25.5] "s"  ARS_ISF5

BO_ 1105 CollDetRegionCfg5: 8 ExternalUnit
 SG_ CollDetRegCfg_Activate : 1|1@0+ (1,0) [0|1] ""  ARS_ISF5
 SG_ CollDetRegCfg_Coordinates_valid : 2|1@0+ (1,0) [0|1] ""  ARS_ISF5
 SG_ CollDetRegCfg_RegionID : 10|3@0+ (1,0) [0|7] ""  ARS_ISF5
 SG_ CollDetRegCfg_Point1X : 23|13@0+ (0.2,-500) [-500|1138.2] "m"  ARS_ISF5
 SG_ CollDetRegCfg_Point1Y : 26|11@0+ (0.2,-204.6) [-204.6|204.8] "m"  ARS_ISF5
 SG_ CollDetRegCfg_Point2X : 47|13@0+ (0.2,-500) [-500|1138.2] "m"  ARS_ISF5
 SG_ CollDetRegCfg_Point2Y : 50|11@0+ (0.2,-204.6) [-204.6|204.8] "m"  ARS_ISF5

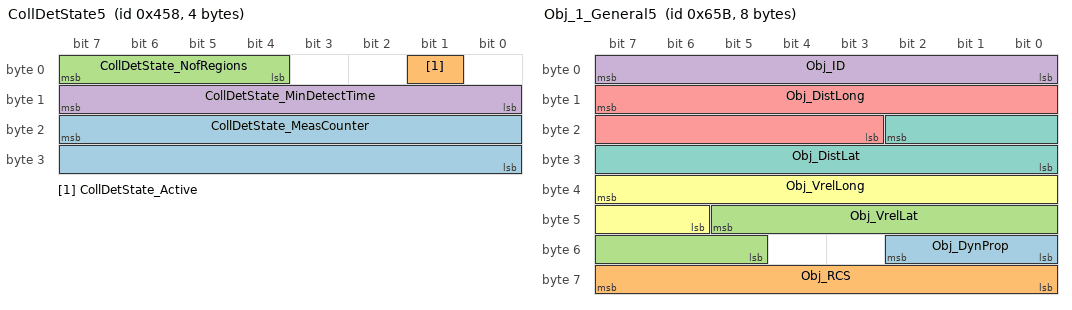
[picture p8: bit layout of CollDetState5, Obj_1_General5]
BO_ 1112 CollDetState5: 4 ARS_ISF5
 SG_ CollDetState_MeasCounter : 23|16@0+ (1,0) [0|65535] "" Vector__XXX
 SG_ CollDetState_Active : 1|1@0+ (1,0) [0|1] "" Vector__XXX
 SG_ CollDetState_NofRegions : 7|4@0+ (1,0) [0|15] ""  ExternalUnit
 SG_ CollDetState_MinDetectTime : 15|8@0+ (0.1,0) [0|25.5] "s"  ExternalUnit

BO_ 1616 Cluster_0_Status5: 5 ARS_ISF5
 SG_ Cluster_MeasCounter : 23|16@0+ (1,0) [0|65535] ""  ExternalUnit
 SG_ Cluster_NofClustersNear : 7|8@0+ (1,0) [0|255] ""  ExternalUnit
 SG_ Cluster_NofClustersFar : 15|8@0+ (1,0) [0|255] ""  ExternalUnit
 SG_ Cluster_InterfaceVersion : 39|4@0+ (1,0) [0|15] ""  ExternalUnit

BO_ 1626 Obj_0_Status5: 4 ARS_ISF5
 SG_ Obj_NofObjects : 7|8@0+ (1,0) [0|255] "1"  ExternalUnit
 SG_ Obj_MeasCounter : 15|16@0+ (1,0) [0|65535] ""  ExternalUnit
 SG_ Obj_InterfaceVersion : 31|4@0+ (1,0) [0|16] ""  ExternalUnit

BO_ 1627 Obj_1_General5: 8 ARS_ISF5
 SG_ Obj_DynProp : 50|3@0+ (1,0) [0|7] ""  ExternalUnit
 SG_ Obj_RCS : 63|8@0+ (0.5,-64) [-64|63.5] "dBm²"  ExternalUnit
 SG_ Obj_VrelLat : 45|9@0+ (0.25,-64) [-64|63.75] "m/s"  ExternalUnit
 SG_ Obj_ID : 7|8@0+ (1,0) [0|255] ""  ExternalUnit
 SG_ Obj_DistLong : 15|13@0+ (0.2,-500) [-500|1138.2] "m"  ExternalUnit
 SG_ Obj_VrelLong : 39|10@0+ (0.25,-128) [-128|127.75] "m/s"  ExternalUnit
 SG_ Obj_DistLat : 18|11@0+ (0.2,-204.6) [-204.6|204.8] "m"  ExternalUnit

BO_ 1872 VersionID5: 3 ARS_ISF5
 SG_ Version_MajorRelease : 7|8@0+ (1,0) [0|256] ""  ExternalUnit
 SG_ Version_MinorRelease : 15|8@0+ (1,0) [0|256] ""  ExternalUnit
 SG_ Version_PatchLevel : 23|8@0+ (1,0) [0|256] ""  ExternalUnit

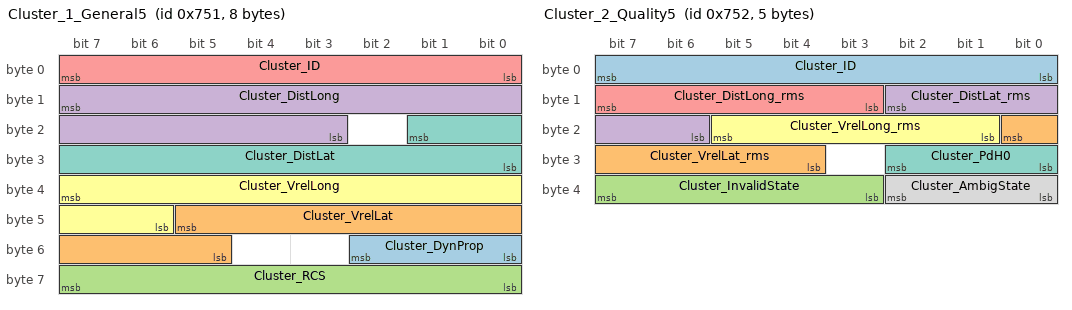
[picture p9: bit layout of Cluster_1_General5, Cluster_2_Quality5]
BO_ 1873 Cluster_1_General5: 8 ARS_ISF5
 SG_ Cluster_DynProp : 50|3@0+ (1,0) [0|7] "1"  ExternalUnit
 SG_ Cluster_VrelLat : 45|9@0+ (0.25,-64) [-64|63.75] "m/s"  ExternalUnit
 SG_ Cluster_RCS : 63|8@0+ (0.5,-64) [-64|63.5] "dBm²"  ExternalUnit
 SG_ Cluster_DistLong : 15|13@0+ (0.2,-500) [-500|1138.2] "m"  ExternalUnit
 SG_ Cluster_ID : 7|8@0+ (1,0) [0|255] "1"  ExternalUnit
 SG_ Cluster_VrelLong : 39|10@0+ (0.25,-128) [-128|127.75] "m/s"  ExternalUnit
 SG_ Cluster_DistLat : 17|10@0+ (0.2,-102.3) [-102.3|102.3] "m"  ExternalUnit

BO_ 1874 Cluster_2_Quality5: 5 ARS_ISF5
 SG_ Cluster_ID : 7|8@0+ (1,0) [0|255] "1"  ExternalUnit
 SG_ Cluster_VrelLat_rms : 16|5@0+ (1,0) [0|31] "m/s"  ExternalUnit
 SG_ Cluster_InvalidState : 39|5@0+ (1,0) [0|31] ""  ExternalUnit
 SG_ Cluster_DistLat_rms : 10|5@0+ (1,0) [0|31] "m"  ExternalUnit
 SG_ Cluster_DistLong_rms : 15|5@0+ (1,0) [0|31] "m"  ExternalUnit
 SG_ Cluster_VrelLong_rms : 21|5@0+ (1,0) [0|31] "m/s"  ExternalUnit
 SG_ Cluster_PdH0 : 26|3@0+ (1,0) [0|7] ""  ExternalUnit
 SG_ Cluster_AmbigState : 34|3@0+ (1,0) [0|7] "1"  ExternalUnit

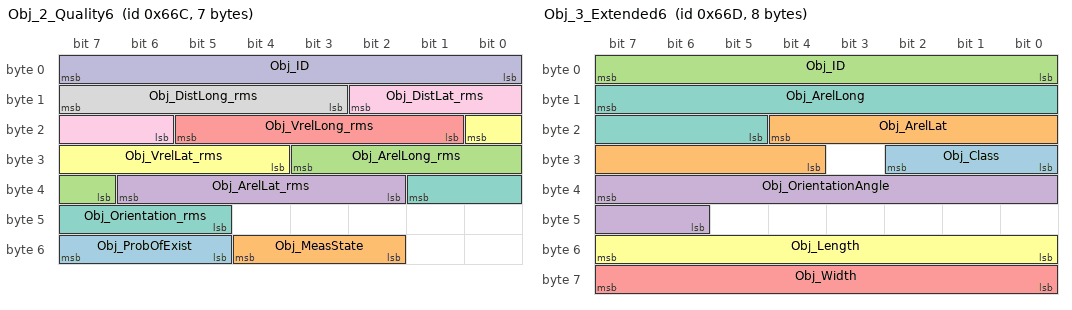
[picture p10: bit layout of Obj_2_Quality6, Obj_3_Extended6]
BO_ 1644 Obj_2_Quality6: 7 ARS_ISF6
 SG_ Obj_ProbOfExist : 55|3@0+ (1,0) [0|7] ""  ExternalUnit
 SG_ Obj_MeasState : 52|3@0+ (1,0) [0|7] ""  ExternalUnit
 SG_ Obj_ArelLong_rms : 27|5@0+ (1,0) [0|31] ""  ExternalUnit
 SG_ Obj_ArelLat_rms : 38|5@0+ (1,0) [0|31] ""  ExternalUnit
 SG_ Obj_VrelLong_rms : 21|5@0+ (1,0) [0|31] ""  ExternalUnit
 SG_ Obj_VrelLat_rms : 16|5@0+ (1,0) [0|31] ""  ExternalUnit
 SG_ Obj_Orientation_rms : 33|5@0+ (1,0) [0|31] ""  ExternalUnit
 SG_ Obj_DistLong_rms : 15|5@0+ (1,0) [0|31] ""  ExternalUnit
 SG_ Obj_DistLat_rms : 10|5@0+ (1,0) [0|31] ""  ExternalUnit
 SG_ Obj_ID : 7|8@0+ (1,0) [0|255] ""  ExternalUnit

BO_ 1645 Obj_3_Extended6: 8 ARS_ISF6
 SG_ Obj_Class : 26|3@0+ (1,0) [0|7] ""  ExternalUnit
 SG_ Obj_ArelLat : 20|9@0+ (0.01,-2.5) [-2.5|2.61] "m/s²"  ExternalUnit
 SG_ Obj_ID : 7|8@0+ (1,0) [0|255] ""  ExternalUnit
 SG_ Obj_OrientationAngle : 39|10@0+ (0.4,-180) [-180|229.2] "deg"  ExternalUnit
 SG_ Obj_Width : 63|8@0+ (0.2,0) [0|51] "m"  ExternalUnit
 SG_ Obj_Length : 55|8@0+ (0.2,0) [0|51] "m"  ExternalUnit
 SG_ Obj_ArelLong : 15|11@0+ (0.01,-10) [-10|10.47] "m/s²"  ExternalUnit

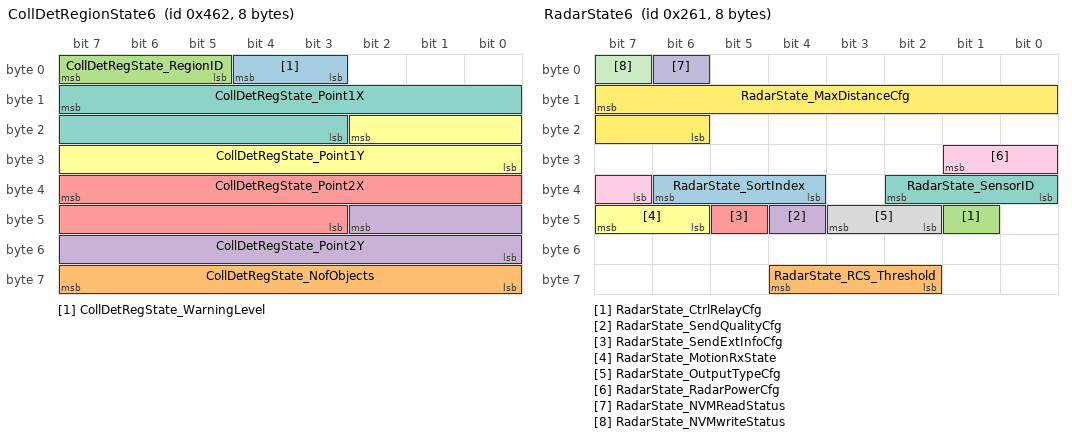
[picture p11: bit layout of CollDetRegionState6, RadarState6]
BO_ 1122 CollDetRegionState6: 8 ARS_ISF6
 SG_ CollDetRegState_WarningLevel : 4|2@0+ (1,0) [0|3] ""  ExternalUnit
 SG_ CollDetRegState_NofObjects : 63|8@0+ (1,0) [0|255] ""  ExternalUnit
 SG_ CollDetRegState_RegionID : 7|3@0+ (1,0) [0|7] ""  ExternalUnit
 SG_ CollDetRegState_Point2Y : 42|11@0+ (0.2,-204.6) [-204.6|204.8] "m"  ExternalUnit
 SG_ CollDetRegState_Point2X : 39|13@0+ (0.2,-500) [-500|1138.2] "m"  ExternalUnit
 SG_ CollDetRegState_Point1Y : 18|11@0+ (0.2,-204.6) [-204.6|204.8] "m"  ExternalUnit
 SG_ CollDetRegState_Point1X : 15|13@0+ (0.2,-500) [-500|1138.2] "m"  ExternalUnit

BO_ 1646 Obj_4_Warning6: 4 ARS_ISF6
 SG_ Obj_CollDetRegionBitfield : 15|8@0+ (1,0) [0|255] ""  ExternalUnit
 SG_ Obj_ID : 7|8@0+ (1,0) [0|255] ""  ExternalUnit

BO_ 612 FilterState_Cfg6: 5 ARS_ISF6
 SG_ FilterState_Max_Class m15 : 39|8@0+ (1,0) [0|255] ""  ExternalUnit
 SG_ FilterState_Min_Class m15 : 23|8@0+ (1,0) [0|255] ""  ExternalUnit
 SG_ FilterState_Min_Y m9 : 11|12@0+ (0.2,-409.5) [-409.5|409.5] "m"  ExternalUnit
 SG_ FilterState_Min_X m10 : 12|13@0+ (0.2,-500) [-500|1138.2] "m"  ExternalUnit
 SG_ FilterState_Min_VYRightLeft m13 : 11|12@0+ (0.0315,0) [0|128.9925] "m/s"  ExternalUnit
 SG_ FilterState_Min_VYLeftRight m11 : 11|12@0+ (0.0315,0) [0|128.9925] "m/s"  ExternalUnit
 SG_ FilterState_Min_VXOncome m12 : 11|12@0+ (0.0315,0) [0|128.9925] "m/s"  ExternalUnit
 SG_ FilterState_Min_VXDepart m14 : 11|12@0+ (0.0315,0) [0|128.9925] "m/s"  ExternalUnit
 SG_ FilterState_Max_Y m9 : 27|12@0+ (0.2,-409.5) [-409.5|409.5] "m"  ExternalUnit
 SG_ FilterState_Max_X m10 : 28|13@0+ (0.2,-500) [-500|1138.2] "m"  ExternalUnit
 SG_ FilterState_Max_VYRightLeft m13 : 27|12@0+ (0.0315,0) [0|128.9925] "m/s"  ExternalUnit
 SG_ FilterState_Max_VYLeftRight m11 : 27|12@0+ (0.0315,0) [0|128.9925] "m/s"  ExternalUnit
 SG_ FilterState_Max_VXOncome m12 : 27|12@0+ (0.0315,0) [0|128.9925] "m/s"  ExternalUnit
 SG_ FilterState_Max_VXDepart m14 : 27|12@0+ (0.0315,0) [0|128.9925] "m/s"  ExternalUnit
 SG_ FilterState_Type : 7|1@0+ (1,0) [0|1] ""  ExternalUnit
 SG_ FilterState_Min_VrelOncome m3 : 11|12@0+ (0.0315,0) [0|128.9925] "m/s"  ExternalUnit
 SG_ FilterState_Min_VrelDepart m4 : 11|12@0+ (0.0315,0) [0|128.9925] "m/s"  ExternalUnit
 SG_ FilterState_Min_Size m7 : 11|12@0+ (0.025,0) [0|102.375] "m2"  ExternalUnit
 SG_ FilterState_Min_RCS m5 : 11|12@0+ (0.025,-50) [-50|52.375] "dB"  ExternalUnit
 SG_ FilterState_Min_ProbExists m8 : 11|12@0+ (1,0) [0|7] ""  ExternalUnit
 SG_ FilterState_Min_NofObj m0 : 11|12@0+ (1,0) [0|4095] ""  ExternalUnit
 SG_ FilterState_Min_Lifetime m6 : 11|12@0+ (0.1,0) [0|409.5] "s"  ExternalUnit
 SG_ FilterState_Min_Distance m1 : 11|12@0+ (0.1,0) [0|409.5] "m"  ExternalUnit
 SG_ FilterState_Min_Azimuth m2 : 11|12@0+ (0.025,-50) [-50|52.375] "deg"  ExternalUnit
 SG_ FilterState_Max_VrelOncome m3 : 27|12@0+ (0.0315,0) [0|128.9925] "m/s"  ExternalUnit
 SG_ FilterState_Max_VrelDepart m4 : 27|12@0+ (0.0315,0) [0|128.9925] "m/s"  ExternalUnit
 SG_ FilterState_Max_Size m7 : 27|12@0+ (0.025,0) [0|102.375] "m2"  ExternalUnit
 SG_ FilterState_Max_RCS m5 : 27|12@0+ (0.025,-50) [-50|52.375] "dB"  ExternalUnit
 SG_ FilterState_Max_ProbExists m8 : 27|12@0+ (1,0) [0|4095] ""  ExternalUnit
 SG_ FilterState_Max_NofObj m0 : 27|12@0+ (1,0) [0|4095] ""  ExternalUnit
 SG_ FilterState_Max_Lifetime m6 : 27|12@0+ (0.1,0) [0|409.5] "s"  ExternalUnit
 SG_ FilterState_Max_Distance m1 : 27|12@0+ (0.1,0) [0|409.5] "m"  ExternalUnit
 SG_ FilterState_Max_Azimuth m2 : 27|12@0+ (0.025,-50) [-50|52.375] "deg"  ExternalUnit
 SG_ FilterState_Index M : 6|4@0+ (1,0) [0|15] ""  ExternalUnit
 SG_ FilterState_Active : 2|1@0+ (1,0) [0|1] ""  ExternalUnit

BO_ 611 FilterState_Header6: 2 ARS_ISF6
 SG_ FilterState_NofObjectFilterCfg : 15|5@0+ (1,0) [0|31] ""  ExternalUnit
 SG_ FilterState_NofClusterFilterCfg : 7|5@0+ (1,0) [0|31] ""  ExternalUnit

BO_ 610 FilterCfg6: 5 ExternalUnit
 SG_ FilterCfg_Min_Class m15 : 23|8@0+ (1,0) [0|255] ""  ARS_ISF6
 SG_ FilterCfg_Max_Class m15 : 39|8@0+ (1,0) [0|255] ""  ARS_ISF6
 SG_ FilterCfg_Min_Y m9 : 11|12@0+ (0.2,-409.5) [-409.5|409.5] "m"  ARS_ISF6
 SG_ FilterCfg_Min_X m10 : 12|13@0+ (0.2,-500) [-500|1138.2] "m"  ARS_ISF6
 SG_ FilterCfg_Min_VYRightLeft m13 : 11|12@0+ (0.0315,0) [0|128.9925] "m/s"  ARS_ISF6
 SG_ FilterCfg_Min_VYLeftRight m11 : 11|12@0+ (0.0315,0) [0|128.9925] "m/s"  ARS_ISF6
 SG_ FilterCfg_Min_VXOncome m12 : 11|12@0+ (0.0315,0) [0|128.9925] "m/s"  ARS_ISF6
 SG_ FilterCfg_Min_VXDepart m14 : 11|12@0+ (0.0315,0) [0|128.9925] "m/s"  ARS_ISF6
 SG_ FilterCfg_Max_Y m9 : 27|12@0+ (0.2,-409.5) [-409.5|409.5] "m"  ARS_ISF6
 SG_ FilterCfg_Max_X m10 : 28|13@0+ (0.2,-500) [-500|1138.2] "m"  ARS_ISF6
 SG_ FilterCfg_Max_VYRightLeft m13 : 27|12@0+ (0.0315,0) [0|128.9925] "m/s"  ARS_ISF6
 SG_ FilterCfg_Max_VXOncome m12 : 27|12@0+ (0.0315,0) [0|128.9925] "m/s"  ARS_ISF6
 SG_ FilterCfg_Max_VYLeftRight m11 : 27|12@0+ (0.0315,0) [0|128.9925] "m/s"  ARS_ISF6
 SG_ FilterCfg_Max_VXDepart m14 : 27|12@0+ (0.0315,0) [0|128.9925] "m/s"  ARS_ISF6
 SG_ FilterCfg_Valid : 1|1@0+ (1,0) [0|1] ""  ARS_ISF6
 SG_ FilterCfg_Active : 2|1@0+ (1,0) [0|1] ""  ARS_ISF6
 SG_ FilterCfg_Max_VrelOncome m3 : 27|12@0+ (0.0315,0) [0|128.9925] "m/s"  ARS_ISF6
 SG_ FilterCfg_Max_VrelDepart m4 : 27|12@0+ (0.0315,0) [0|128.9925] "m/s"  ARS_ISF6
 SG_ FilterCfg_Max_Size m7 : 27|12@0+ (0.025,0) [0|102.375] "m2"  ARS_ISF6
 SG_ FilterCfg_Max_RCS m5 : 27|12@0+ (0.025,-50) [-50|52.375] "dB"  ARS_ISF6
 SG_ FilterCfg_Max_ProbExists m8 : 27|12@0+ (1,0) [0|7] ""  ARS_ISF6
 SG_ FilterCfg_Max_NofObj m0 : 27|12@0+ (1,0) [0|4095] ""  ARS_ISF6
 SG_ FilterCfg_Max_Lifetime m6 : 27|12@0+ (0.1,0) [0|409.5] "s"  ARS_ISF6
 SG_ FilterCfg_Max_Distance m1 : 27|12@0+ (0.1,0) [0|409.5] "m"  ARS_ISF6
 SG_ FilterCfg_Max_Azimuth m2 : 27|12@0+ (0.025,-50) [-50|52.375] "deg"  ARS_ISF6
 SG_ FilterCfg_Min_VrelOncome m3 : 11|12@0+ (0.0315,0) [0|128.9925] "m/s"  ARS_ISF6
 SG_ FilterCfg_Min_VrelDepart m4 : 11|12@0+ (0.0315,0) [0|128.9925] "m/s"  ARS_ISF6
 SG_ FilterCfg_Min_Size m7 : 11|12@0+ (0.025,0) [0|102.375] "m2"  ARS_ISF6
 SG_ FilterCfg_Min_RCS m5 : 11|12@0+ (0.025,-50) [-50|52.375] "dB"  ARS_ISF6
 SG_ FilterCfg_Min_ProbExists m8 : 11|12@0+ (1,0) [0|4095] ""  ARS_ISF6
 SG_ FilterCfg_Min_Lifetime m6 : 11|12@0+ (0.1,0) [0|409.5] "s"  ARS_ISF6
 SG_ FilterCfg_Min_Azimuth m2 : 11|12@0+ (0.025,-50) [-50|52.375] "deg"  ARS_ISF6
 SG_ FilterCfg_Min_NofObj m0 : 11|12@0+ (1,0) [0|4095] ""  ARS_ISF6
 SG_ FilterCfg_Min_Distance m1 : 11|12@0+ (0.1,0) [0|409.5] "m"  ARS_ISF6
 SG_ FilterCfg_Index M : 6|4@0+ (1,0) [0|15] ""  ARS_ISF6
 SG_ FilterCfg_Type : 7|1@0+ (1,0) [0|1] ""  ARS_ISF6

BO_ 608 RadarConfiguration6: 8 ExternalUnit
 SG_ RadarCfg_RCS_Threshold_Valid : 48|1@0+ (1,0) [0|1] "" Vector__XXX
 SG_ RadarCfg_RCS_Threshold : 51|3@0+ (1,0) [0|7] "" Vector__XXX
 SG_ RadarCfg_StoreInNVM_valid : 7|1@0+ (1,0) [0|1] "" Vector__XXX
 SG_ RadarCfg_SortIndex_valid : 6|1@0+ (1,0) [0|1] "" Vector__XXX
 SG_ RadarCfg_SortIndex : 46|3@0+ (1,0) [0|7] "" Vector__XXX
 SG_ RadarCfg_StoreInNVM : 47|1@0+ (1,0) [0|1] ""  ARS_ISF6
 SG_ RadarCfg_SendExtInfo_valid : 5|1@0+ (1,0) [0|1] ""  ARS_ISF6
 SG_ RadarCfg_SendExtInfo : 43|1@0+ (1,0) [0|1] ""  ARS_ISF6
 SG_ RadarCfg_CtrlRelay_valid : 40|1@0+ (1,0) [0|1] ""  ARS_ISF6
 SG_ RadarCfg_CtrlRelay : 41|1@0+ (1,0) [0|1] ""  ARS_ISF6
 SG_ RadarCfg_SendQuality_valid : 4|1@0+ (1,0) [0|1] ""  ARS_ISF6
 SG_ RadarCfg_SendQuality : 42|1@0+ (1,0) [0|1] ""  ARS_ISF6
 SG_ RadarCfg_MaxDistance_valid : 0|1@0+ (1,0) [0|1] ""  ARS_ISF6
 SG_ RadarCfg_RadarPower_valid : 2|1@0+ (1,0) [0|1] ""  ARS_ISF6
 SG_ RadarCfg_OutputType_valid : 3|1@0+ (1,0) [0|1] ""  ARS_ISF6
 SG_ RadarCfg_SensorID_valid : 1|1@0+ (1,0) [0|1] ""  ARS_ISF6
 SG_ RadarCfg_MaxDistance : 15|10@0+ (2,0) [0|2046] "m"  ARS_ISF6
 SG_ RadarCfg_RadarPower : 39|3@0+ (1,0) [0|7] ""  ARS_ISF6
 SG_ RadarCfg_OutputType : 36|2@0+ (1,0) [0|2] ""  ARS_ISF6
 SG_ RadarCfg_SensorID : 34|3@0+ (1,0) [0|7] ""  ARS_ISF6

BO_ 609 RadarState6: 8 ARS_ISF6
 SG_ RadarState_SortIndex : 38|3@0+ (1,0) [0|0] "" Vector__XXX
 SG_ RadarState_RCS_Threshold : 60|3@0+ (1,0) [0|7] "" Vector__XXX
 SG_ RadarState_CtrlRelayCfg : 41|1@0+ (1,0) [0|1] ""  ExternalUnit
 SG_ RadarState_SendQualityCfg : 44|1@0+ (1,0) [0|1] ""  ExternalUnit
 SG_ RadarState_SendExtInfoCfg : 45|1@0+ (1,0) [0|1] ""  ExternalUnit
 SG_ RadarState_MotionRxState : 47|2@0+ (1,0) [0|3] ""  ExternalUnit
 SG_ RadarState_SensorID : 34|3@0+ (1,0) [0|7] ""  ExternalUnit
 SG_ RadarState_OutputTypeCfg : 43|2@0+ (1,0) [0|3] ""  ExternalUnit
 SG_ RadarState_RadarPowerCfg : 25|3@0+ (1,0) [0|7] ""  ExternalUnit
 SG_ RadarState_NVMReadStatus : 6|1@0+ (1,0) [0|1] ""  ExternalUnit
 SG_ RadarState_NVMwriteStatus : 7|1@0+ (1,0) [0|1] ""  ExternalUnit
 SG_ RadarState_MaxDistanceCfg : 15|10@0+ (2,0) [0|2046] ""  ExternalUnit

BO_ 864 SpeedInformation6: 2 ExternalUnit
 SG_ RadarDevice_Speed : 4|13@0+ (0.02,0) [0|163.8] "m/s"  ARS_ISF6
 SG_ RadarDevice_SpeedDirection : 7|2@0+ (1,0) [0|2] ""  ARS_ISF6

BO_ 865 YawRateInformation6: 2 ExternalUnit
 SG_ RadarDevice_YawRate : 7|16@0+ (0.01,-327.68) [-327.68|327.66] "°/s"  ARS_ISF6

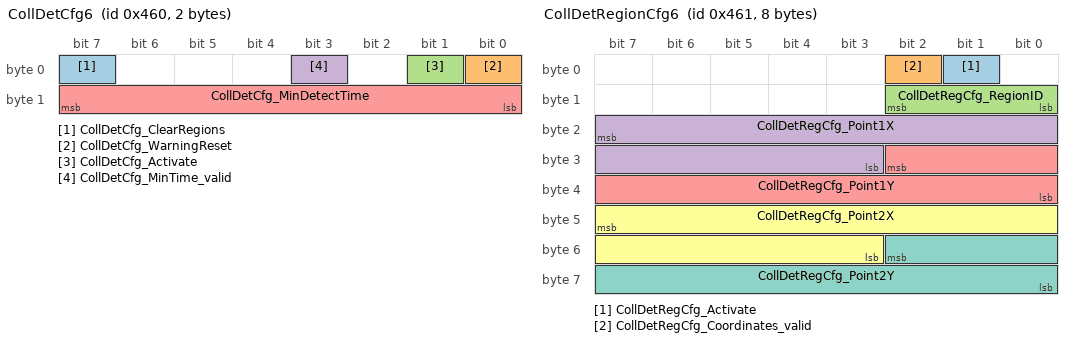
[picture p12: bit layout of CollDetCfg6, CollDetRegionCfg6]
BO_ 1120 CollDetCfg6: 2 ExternalUnit
 SG_ CollDetCfg_ClearRegions : 7|1@0+ (1,0) [0|1] ""  ARS_ISF6
 SG_ CollDetCfg_WarningReset : 0|1@0+ (1,0) [0|1] ""  ARS_ISF6
 SG_ CollDetCfg_Activate : 1|1@0+ (1,0) [0|1] ""  ARS_ISF6
 SG_ CollDetCfg_MinTime_valid : 3|1@0+ (1,0) [0|1] ""  ARS_ISF6
 SG_ CollDetCfg_MinDetectTime : 15|8@0+ (0.1,0) [0|25.5] "s"  ARS_ISF6

BO_ 1121 CollDetRegionCfg6: 8 ExternalUnit
 SG_ CollDetRegCfg_Activate : 1|1@0+ (1,0) [0|1] ""  ARS_ISF6
 SG_ CollDetRegCfg_Coordinates_valid : 2|1@0+ (1,0) [0|1] ""  ARS_ISF6
 SG_ CollDetRegCfg_RegionID : 10|3@0+ (1,0) [0|7] ""  ARS_ISF6
 SG_ CollDetRegCfg_Point1X : 23|13@0+ (0.2,-500) [-500|1138.2] "m"  ARS_ISF6
 SG_ CollDetRegCfg_Point1Y : 26|11@0+ (0.2,-204.6) [-204.6|204.8] "m"  ARS_ISF6
 SG_ CollDetRegCfg_Point2X : 47|13@0+ (0.2,-500) [-500|1138.2] "m"  ARS_ISF6
 SG_ CollDetRegCfg_Point2Y : 50|11@0+ (0.2,-204.6) [-204.6|204.8] "m"  ARS_ISF6

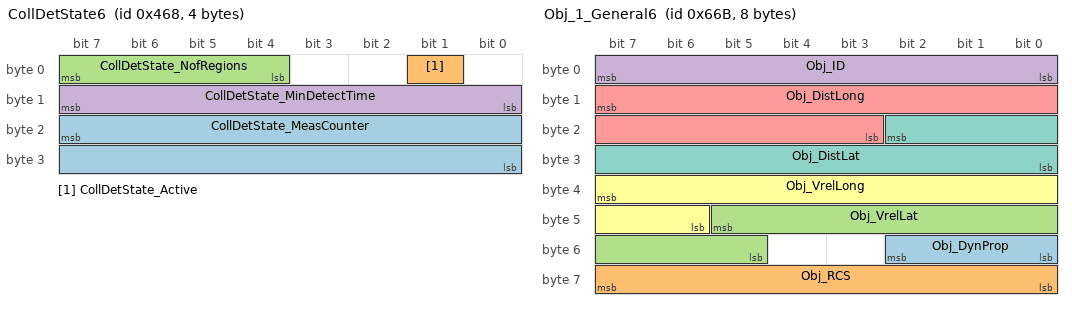
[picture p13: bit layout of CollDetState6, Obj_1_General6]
BO_ 1128 CollDetState6: 4 ARS_ISF6
 SG_ CollDetState_MeasCounter : 23|16@0+ (1,0) [0|65535] "" Vector__XXX
 SG_ CollDetState_Active : 1|1@0+ (1,0) [0|1] "" Vector__XXX
 SG_ CollDetState_NofRegions : 7|4@0+ (1,0) [0|15] ""  ExternalUnit
 SG_ CollDetState_MinDetectTime : 15|8@0+ (0.1,0) [0|25.5] "s"  ExternalUnit

BO_ 1632 Cluster_0_Status6: 5 ARS_ISF6
 SG_ Cluster_MeasCounter : 23|16@0+ (1,0) [0|65535] ""  ExternalUnit
 SG_ Cluster_NofClustersNear : 7|8@0+ (1,0) [0|255] ""  ExternalUnit
 SG_ Cluster_NofClustersFar : 15|8@0+ (1,0) [0|255] ""  ExternalUnit
 SG_ Cluster_InterfaceVersion : 39|4@0+ (1,0) [0|15] ""  ExternalUnit

BO_ 1642 Obj_0_Status6: 4 ARS_ISF6
 SG_ Obj_NofObjects : 7|8@0+ (1,0) [0|255] "1"  ExternalUnit
 SG_ Obj_MeasCounter : 15|16@0+ (1,0) [0|65535] ""  ExternalUnit
 SG_ Obj_InterfaceVersion : 31|4@0+ (1,0) [0|16] ""  ExternalUnit

BO_ 1643 Obj_1_General6: 8 ARS_ISF6
 SG_ Obj_DynProp : 50|3@0+ (1,0) [0|7] ""  ExternalUnit
 SG_ Obj_RCS : 63|8@0+ (0.5,-64) [-64|63.5] "dBm²"  ExternalUnit
 SG_ Obj_VrelLat : 45|9@0+ (0.25,-64) [-64|63.75] "m/s"  ExternalUnit
 SG_ Obj_ID : 7|8@0+ (1,0) [0|255] ""  ExternalUnit
 SG_ Obj_DistLong : 15|13@0+ (0.2,-500) [-500|1138.2] "m"  ExternalUnit
 SG_ Obj_VrelLong : 39|10@0+ (0.25,-128) [-128|127.75] "m/s"  ExternalUnit
 SG_ Obj_DistLat : 18|11@0+ (0.2,-204.6) [-204.6|204.8] "m"  ExternalUnit

BO_ 1888 VersionID6: 3 ARS_ISF6
 SG_ Version_MajorRelease : 7|8@0+ (1,0) [0|256] ""  ExternalUnit
 SG_ Version_MinorRelease : 15|8@0+ (1,0) [0|256] ""  ExternalUnit
 SG_ Version_PatchLevel : 23|8@0+ (1,0) [0|256] ""  ExternalUnit

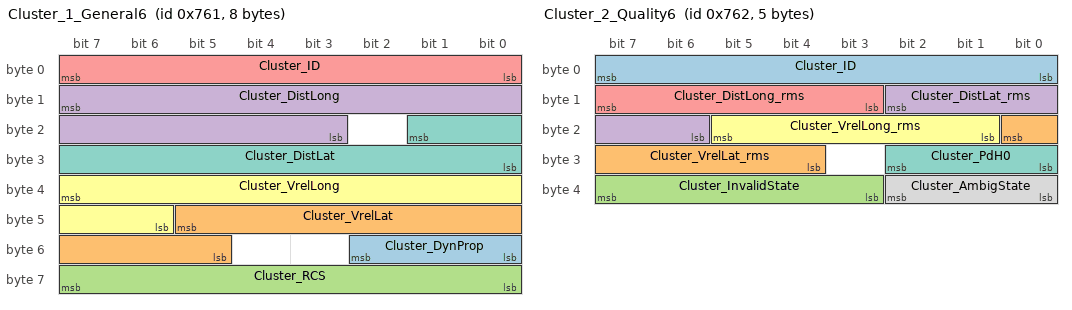
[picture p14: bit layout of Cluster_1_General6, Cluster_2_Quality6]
BO_ 1889 Cluster_1_General6: 8 ARS_ISF6
 SG_ Cluster_DynProp : 50|3@0+ (1,0) [0|7] "1"  ExternalUnit
 SG_ Cluster_VrelLat : 45|9@0+ (0.25,-64) [-64|63.75] "m/s"  ExternalUnit
 SG_ Cluster_RCS : 63|8@0+ (0.5,-64) [-64|63.5] "dBm²"  ExternalUnit
 SG_ Cluster_DistLong : 15|13@0+ (0.2,-500) [-500|1138.2] "m"  ExternalUnit
 SG_ Cluster_ID : 7|8@0+ (1,0) [0|255] "1"  ExternalUnit
 SG_ Cluster_VrelLong : 39|10@0+ (0.25,-128) [-128|127.75] "m/s"  ExternalUnit
 SG_ Cluster_DistLat : 17|10@0+ (0.2,-102.3) [-102.3|102.3] "m"  ExternalUnit

BO_ 1890 Cluster_2_Quality6: 5 ARS_ISF6
 SG_ Cluster_ID : 7|8@0+ (1,0) [0|255] "1"  ExternalUnit
 SG_ Cluster_VrelLat_rms : 16|5@0+ (1,0) [0|31] "m/s"  ExternalUnit
 SG_ Cluster_InvalidState : 39|5@0+ (1,0) [0|31] ""  ExternalUnit
 SG_ Cluster_DistLat_rms : 10|5@0+ (1,0) [0|31] "m"  ExternalUnit
 SG_ Cluster_DistLong_rms : 15|5@0+ (1,0) [0|31] "m"  ExternalUnit
 SG_ Cluster_VrelLong_rms : 21|5@0+ (1,0) [0|31] "m/s"  ExternalUnit
 SG_ Cluster_PdH0 : 26|3@0+ (1,0) [0|7] ""  ExternalUnit
 SG_ Cluster_AmbigState : 34|3@0+ (1,0) [0|7] "1"  ExternalUnit

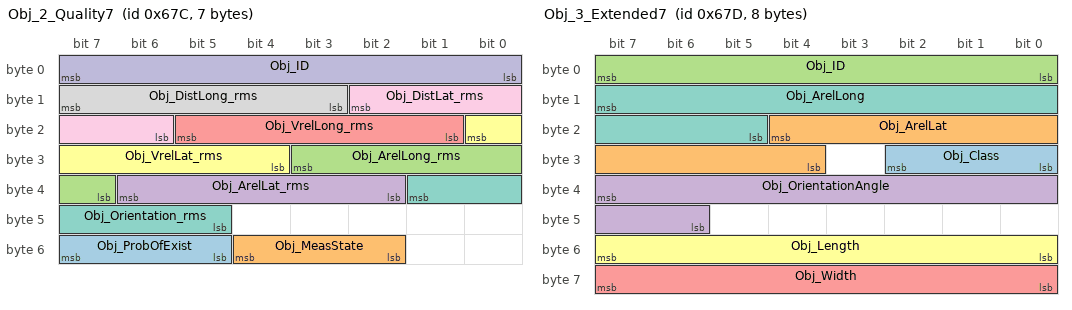
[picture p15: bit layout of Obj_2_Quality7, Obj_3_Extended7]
BO_ 1660 Obj_2_Quality7: 7 ARS_ISF7
 SG_ Obj_ProbOfExist : 55|3@0+ (1,0) [0|7] ""  ExternalUnit
 SG_ Obj_MeasState : 52|3@0+ (1,0) [0|7] ""  ExternalUnit
 SG_ Obj_ArelLong_rms : 27|5@0+ (1,0) [0|31] ""  ExternalUnit
 SG_ Obj_ArelLat_rms : 38|5@0+ (1,0) [0|31] ""  ExternalUnit
 SG_ Obj_VrelLong_rms : 21|5@0+ (1,0) [0|31] ""  ExternalUnit
 SG_ Obj_VrelLat_rms : 16|5@0+ (1,0) [0|31] ""  ExternalUnit
 SG_ Obj_Orientation_rms : 33|5@0+ (1,0) [0|31] ""  ExternalUnit
 SG_ Obj_DistLong_rms : 15|5@0+ (1,0) [0|31] ""  ExternalUnit
 SG_ Obj_DistLat_rms : 10|5@0+ (1,0) [0|31] ""  ExternalUnit
 SG_ Obj_ID : 7|8@0+ (1,0) [0|255] ""  ExternalUnit

BO_ 1661 Obj_3_Extended7: 8 ARS_ISF7
 SG_ Obj_Class : 26|3@0+ (1,0) [0|7] ""  ExternalUnit
 SG_ Obj_ArelLat : 20|9@0+ (0.01,-2.5) [-2.5|2.61] "m/s²"  ExternalUnit
 SG_ Obj_ID : 7|8@0+ (1,0) [0|255] ""  ExternalUnit
 SG_ Obj_OrientationAngle : 39|10@0+ (0.4,-180) [-180|229.2] "deg"  ExternalUnit
 SG_ Obj_Width : 63|8@0+ (0.2,0) [0|51] "m"  ExternalUnit
 SG_ Obj_Length : 55|8@0+ (0.2,0) [0|51] "m"  ExternalUnit
 SG_ Obj_ArelLong : 15|11@0+ (0.01,-10) [-10|10.47] "m/s²"  ExternalUnit

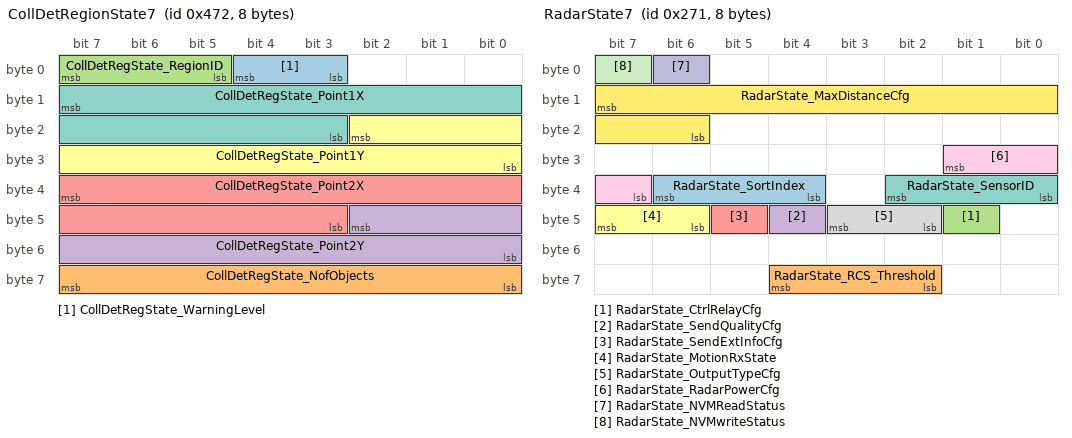
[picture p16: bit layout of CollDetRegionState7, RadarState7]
BO_ 1138 CollDetRegionState7: 8 ARS_ISF7
 SG_ CollDetRegState_WarningLevel : 4|2@0+ (1,0) [0|3] ""  ExternalUnit
 SG_ CollDetRegState_NofObjects : 63|8@0+ (1,0) [0|255] ""  ExternalUnit
 SG_ CollDetRegState_RegionID : 7|3@0+ (1,0) [0|7] ""  ExternalUnit
 SG_ CollDetRegState_Point2Y : 42|11@0+ (0.2,-204.6) [-204.6|204.8] "m"  ExternalUnit
 SG_ CollDetRegState_Point2X : 39|13@0+ (0.2,-500) [-500|1138.2] "m"  ExternalUnit
 SG_ CollDetRegState_Point1Y : 18|11@0+ (0.2,-204.6) [-204.6|204.8] "m"  ExternalUnit
 SG_ CollDetRegState_Point1X : 15|13@0+ (0.2,-500) [-500|1138.2] "m"  ExternalUnit

BO_ 1662 Obj_4_Warning7: 4 ARS_ISF7
 SG_ Obj_CollDetRegionBitfield : 15|8@0+ (1,0) [0|255] ""  ExternalUnit
 SG_ Obj_ID : 7|8@0+ (1,0) [0|255] ""  ExternalUnit

BO_ 8 CollDetRelayCtrl: 1 ARS_ISF7
 SG_ CollDetRelayCtrl_Param : 7|8@0+ (1,0) [0|255] ""  ExternalUnit

BO_ 628 FilterState_Cfg7: 5 ARS_ISF7
 SG_ FilterState_Max_Class m15 : 39|8@0+ (1,0) [0|255] ""  ExternalUnit
 SG_ FilterState_Min_Class m15 : 23|8@0+ (1,0) [0|255] ""  ExternalUnit
 SG_ FilterState_Min_Y m9 : 11|12@0+ (0.2,-409.5) [-409.5|409.5] "m"  ExternalUnit
 SG_ FilterState_Min_X m10 : 12|13@0+ (0.2,-500) [-500|1138.2] "m"  ExternalUnit
 SG_ FilterState_Min_VYRightLeft m13 : 11|12@0+ (0.0315,0) [0|128.9925] "m/s"  ExternalUnit
 SG_ FilterState_Min_VYLeftRight m11 : 11|12@0+ (0.0315,0) [0|128.9925] "m/s"  ExternalUnit
 SG_ FilterState_Min_VXOncome m12 : 11|12@0+ (0.0315,0) [0|128.9925] "m/s"  ExternalUnit
 SG_ FilterState_Min_VXDepart m14 : 11|12@0+ (0.0315,0) [0|128.9925] "m/s"  ExternalUnit
 SG_ FilterState_Max_Y m9 : 27|12@0+ (0.2,-409.5) [-409.5|409.5] "m"  ExternalUnit
 SG_ FilterState_Max_X m10 : 28|13@0+ (0.2,-500) [-500|1138.2] "m"  ExternalUnit
 SG_ FilterState_Max_VYRightLeft m13 : 27|12@0+ (0.0315,0) [0|128.9925] "m/s"  ExternalUnit
 SG_ FilterState_Max_VYLeftRight m11 : 27|12@0+ (0.0315,0) [0|128.9925] "m/s"  ExternalUnit
 SG_ FilterState_Max_VXOncome m12 : 27|12@0+ (0.0315,0) [0|128.9925] "m/s"  ExternalUnit
 SG_ FilterState_Max_VXDepart m14 : 27|12@0+ (0.0315,0) [0|128.9925] "m/s"  ExternalUnit
 SG_ FilterState_Type : 7|1@0+ (1,0) [0|1] ""  ExternalUnit
 SG_ FilterState_Min_VrelOncome m3 : 11|12@0+ (0.0315,0) [0|128.9925] "m/s"  ExternalUnit
 SG_ FilterState_Min_VrelDepart m4 : 11|12@0+ (0.0315,0) [0|128.9925] "m/s"  ExternalUnit
 SG_ FilterState_Min_Size m7 : 11|12@0+ (0.025,0) [0|102.375] "m2"  ExternalUnit
 SG_ FilterState_Min_RCS m5 : 11|12@0+ (0.025,-50) [-50|52.375] "dB"  ExternalUnit
 SG_ FilterState_Min_ProbExists m8 : 11|12@0+ (1,0) [0|7] ""  ExternalUnit
 SG_ FilterState_Min_NofObj m0 : 11|12@0+ (1,0) [0|4095] ""  ExternalUnit
 SG_ FilterState_Min_Lifetime m6 : 11|12@0+ (0.1,0) [0|409.5] "s"  ExternalUnit
 SG_ FilterState_Min_Distance m1 : 11|12@0+ (0.1,0) [0|409.5] "m"  ExternalUnit
 SG_ FilterState_Min_Azimuth m2 : 11|12@0+ (0.025,-50) [-50|52.375] "deg"  ExternalUnit
 SG_ FilterState_Max_VrelOncome m3 : 27|12@0+ (0.0315,0) [0|128.9925] "m/s"  ExternalUnit
 SG_ FilterState_Max_VrelDepart m4 : 27|12@0+ (0.0315,0) [0|128.9925] "m/s"  ExternalUnit
 SG_ FilterState_Max_Size m7 : 27|12@0+ (0.025,0) [0|102.375] "m2"  ExternalUnit
 SG_ FilterState_Max_RCS m5 : 27|12@0+ (0.025,-50) [-50|52.375] "dB"  ExternalUnit
 SG_ FilterState_Max_ProbExists m8 : 27|12@0+ (1,0) [0|4095] ""  ExternalUnit
 SG_ FilterState_Max_NofObj m0 : 27|12@0+ (1,0) [0|4095] ""  ExternalUnit
 SG_ FilterState_Max_Lifetime m6 : 27|12@0+ (0.1,0) [0|409.5] "s"  ExternalUnit
 SG_ FilterState_Max_Distance m1 : 27|12@0+ (0.1,0) [0|409.5] "m"  ExternalUnit
 SG_ FilterState_Max_Azimuth m2 : 27|12@0+ (0.025,-50) [-50|52.375] "deg"  ExternalUnit
 SG_ FilterState_Index M : 6|4@0+ (1,0) [0|15] ""  ExternalUnit
 SG_ FilterState_Active : 2|1@0+ (1,0) [0|1] ""  ExternalUnit

BO_ 627 FilterState_Header7: 2 ARS_ISF7
 SG_ FilterState_NofObjectFilterCfg : 15|5@0+ (1,0) [0|31] ""  ExternalUnit
 SG_ FilterState_NofClusterFilterCfg : 7|5@0+ (1,0) [0|31] ""  ExternalUnit

BO_ 626 FilterCfg7: 5 ExternalUnit
 SG_ FilterCfg_Min_Class m15 : 23|8@0+ (1,0) [0|255] ""  ARS_ISF7
 SG_ FilterCfg_Max_Class m15 : 39|8@0+ (1,0) [0|255] ""  ARS_ISF7
 SG_ FilterCfg_Min_Y m9 : 11|12@0+ (0.2,-409.5) [-409.5|409.5] "m"  ARS_ISF7
 SG_ FilterCfg_Min_X m10 : 12|13@0+ (0.2,-500) [-500|1138.2] "m"  ARS_ISF7
 SG_ FilterCfg_Min_VYRightLeft m13 : 11|12@0+ (0.0315,0) [0|128.9925] "m/s"  ARS_ISF7
 SG_ FilterCfg_Min_VYLeftRight m11 : 11|12@0+ (0.0315,0) [0|128.9925] "m/s"  ARS_ISF7
 SG_ FilterCfg_Min_VXOncome m12 : 11|12@0+ (0.0315,0) [0|128.9925] "m/s"  ARS_ISF7
 SG_ FilterCfg_Min_VXDepart m14 : 11|12@0+ (0.0315,0) [0|128.9925] "m/s"  ARS_ISF7
 SG_ FilterCfg_Max_Y m9 : 27|12@0+ (0.2,-409.5) [-409.5|409.5] "m"  ARS_ISF7
 SG_ FilterCfg_Max_X m10 : 28|13@0+ (0.2,-500) [-500|1138.2] "m"  ARS_ISF7
 SG_ FilterCfg_Max_VYRightLeft m13 : 27|12@0+ (0.0315,0) [0|128.9925] "m/s"  ARS_ISF7
 SG_ FilterCfg_Max_VXOncome m12 : 27|12@0+ (0.0315,0) [0|128.9925] "m/s"  ARS_ISF7
 SG_ FilterCfg_Max_VYLeftRight m11 : 27|12@0+ (0.0315,0) [0|128.9925] "m/s"  ARS_ISF7
 SG_ FilterCfg_Max_VXDepart m14 : 27|12@0+ (0.0315,0) [0|128.9925] "m/s"  ARS_ISF7
 SG_ FilterCfg_Valid : 1|1@0+ (1,0) [0|1] ""  ARS_ISF7
 SG_ FilterCfg_Active : 2|1@0+ (1,0) [0|1] ""  ARS_ISF7
 SG_ FilterCfg_Max_VrelOncome m3 : 27|12@0+ (0.0315,0) [0|128.9925] "m/s"  ARS_ISF7
 SG_ FilterCfg_Max_VrelDepart m4 : 27|12@0+ (0.0315,0) [0|128.9925] "m/s"  ARS_ISF7
 SG_ FilterCfg_Max_Size m7 : 27|12@0+ (0.025,0) [0|102.375] "m2"  ARS_ISF7
 SG_ FilterCfg_Max_RCS m5 : 27|12@0+ (0.025,-50) [-50|52.375] "dB"  ARS_ISF7
 SG_ FilterCfg_Max_ProbExists m8 : 27|12@0+ (1,0) [0|7] ""  ARS_ISF7
 SG_ FilterCfg_Max_NofObj m0 : 27|12@0+ (1,0) [0|4095] ""  ARS_ISF7
 SG_ FilterCfg_Max_Lifetime m6 : 27|12@0+ (0.1,0) [0|409.5] "s"  ARS_ISF7
 SG_ FilterCfg_Max_Distance m1 : 27|12@0+ (0.1,0) [0|409.5] "m"  ARS_ISF7
 SG_ FilterCfg_Max_Azimuth m2 : 27|12@0+ (0.025,-50) [-50|52.375] "deg"  ARS_ISF7
 SG_ FilterCfg_Min_VrelOncome m3 : 11|12@0+ (0.0315,0) [0|128.9925] "m/s"  ARS_ISF7
 SG_ FilterCfg_Min_VrelDepart m4 : 11|12@0+ (0.0315,0) [0|128.9925] "m/s"  ARS_ISF7
 SG_ FilterCfg_Min_Size m7 : 11|12@0+ (0.025,0) [0|102.375] "m2"  ARS_ISF7
 SG_ FilterCfg_Min_RCS m5 : 11|12@0+ (0.025,-50) [-50|52.375] "dB"  ARS_ISF7
 SG_ FilterCfg_Min_ProbExists m8 : 11|12@0+ (1,0) [0|4095] ""  ARS_ISF7
 SG_ FilterCfg_Min_Lifetime m6 : 11|12@0+ (0.1,0) [0|409.5] "s"  ARS_ISF7
 SG_ FilterCfg_Min_Azimuth m2 : 11|12@0+ (0.025,-50) [-50|52.375] "deg"  ARS_ISF7
 SG_ FilterCfg_Min_NofObj m0 : 11|12@0+ (1,0) [0|4095] ""  ARS_ISF7
 SG_ FilterCfg_Min_Distance m1 : 11|12@0+ (0.1,0) [0|409.5] "m"  ARS_ISF7
 SG_ FilterCfg_Index M : 6|4@0+ (1,0) [0|15] ""  ARS_ISF7
 SG_ FilterCfg_Type : 7|1@0+ (1,0) [0|1] ""  ARS_ISF7

BO_ 624 RadarConfiguration7: 8 ExternalUnit
 SG_ RadarCfg_RCS_Threshold_Valid : 48|1@0+ (1,0) [0|1] "" Vector__XXX
 SG_ RadarCfg_RCS_Threshold : 51|3@0+ (1,0) [0|7] "" Vector__XXX
 SG_ RadarCfg_StoreInNVM_valid : 7|1@0+ (1,0) [0|1] "" Vector__XXX
 SG_ RadarCfg_SortIndex_valid : 6|1@0+ (1,0) [0|1] "" Vector__XXX
 SG_ RadarCfg_SortIndex : 46|3@0+ (1,0) [0|7] "" Vector__XXX
 SG_ RadarCfg_StoreInNVM : 47|1@0+ (1,0) [0|1] ""  ARS_ISF7
 SG_ RadarCfg_SendExtInfo_valid : 5|1@0+ (1,0) [0|1] ""  ARS_ISF7
 SG_ RadarCfg_SendExtInfo : 43|1@0+ (1,0) [0|1] ""  ARS_ISF7
 SG_ RadarCfg_CtrlRelay_valid : 40|1@0+ (1,0) [0|1] ""  ARS_ISF7
 SG_ RadarCfg_CtrlRelay : 41|1@0+ (1,0) [0|1] ""  ARS_ISF7
 SG_ RadarCfg_SendQuality_valid : 4|1@0+ (1,0) [0|1] ""  ARS_ISF7
 SG_ RadarCfg_SendQuality : 42|1@0+ (1,0) [0|1] ""  ARS_ISF7
 SG_ RadarCfg_MaxDistance_valid : 0|1@0+ (1,0) [0|1] ""  ARS_ISF7
 SG_ RadarCfg_RadarPower_valid : 2|1@0+ (1,0) [0|1] ""  ARS_ISF7
 SG_ RadarCfg_OutputType_valid : 3|1@0+ (1,0) [0|1] ""  ARS_ISF7
 SG_ RadarCfg_SensorID_valid : 1|1@0+ (1,0) [0|1] ""  ARS_ISF7
 SG_ RadarCfg_MaxDistance : 15|10@0+ (2,0) [0|2046] "m"  ARS_ISF7
 SG_ RadarCfg_RadarPower : 39|3@0+ (1,0) [0|7] ""  ARS_ISF7
 SG_ RadarCfg_OutputType : 36|2@0+ (1,0) [0|2] ""  ARS_ISF7
 SG_ RadarCfg_SensorID : 34|3@0+ (1,0) [0|7] ""  ARS_ISF7

BO_ 625 RadarState7: 8 ARS_ISF7
 SG_ RadarState_SortIndex : 38|3@0+ (1,0) [0|0] "" Vector__XXX
 SG_ RadarState_RCS_Threshold : 60|3@0+ (1,0) [0|7] "" Vector__XXX
 SG_ RadarState_CtrlRelayCfg : 41|1@0+ (1,0) [0|1] ""  ExternalUnit
 SG_ RadarState_SendQualityCfg : 44|1@0+ (1,0) [0|1] ""  ExternalUnit
 SG_ RadarState_SendExtInfoCfg : 45|1@0+ (1,0) [0|1] ""  ExternalUnit
 SG_ RadarState_MotionRxState : 47|2@0+ (1,0) [0|3] ""  ExternalUnit
 SG_ RadarState_SensorID : 34|3@0+ (1,0) [0|7] ""  ExternalUnit
 SG_ RadarState_OutputTypeCfg : 43|2@0+ (1,0) [0|3] ""  ExternalUnit
 SG_ RadarState_RadarPowerCfg : 25|3@0+ (1,0) [0|7] ""  ExternalUnit
 SG_ RadarState_NVMReadStatus : 6|1@0+ (1,0) [0|1] ""  ExternalUnit
 SG_ RadarState_NVMwriteStatus : 7|1@0+ (1,0) [0|1] ""  ExternalUnit
 SG_ RadarState_MaxDistanceCfg : 15|10@0+ (2,0) [0|2046] ""  ExternalUnit

BO_ 880 SpeedInformation7: 2 ExternalUnit
 SG_ RadarDevice_Speed : 4|13@0+ (0.02,0) [0|163.8] "m/s"  ARS_ISF7
 SG_ RadarDevice_SpeedDirection : 7|2@0+ (1,0) [0|2] ""  ARS_ISF7

BO_ 881 YawRateInformation7: 2 ExternalUnit
 SG_ RadarDevice_YawRate : 7|16@0+ (0.01,-327.68) [-327.68|327.66] "°/s"  ARS_ISF7

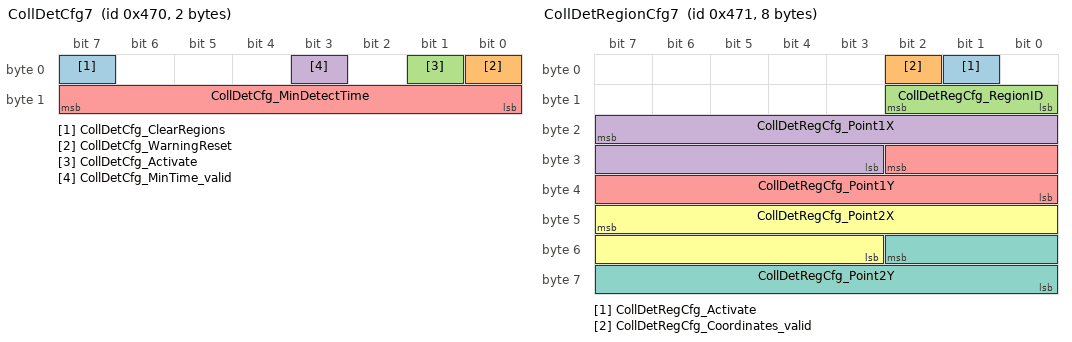
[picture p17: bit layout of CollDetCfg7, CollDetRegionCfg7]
BO_ 1136 CollDetCfg7: 2 ExternalUnit
 SG_ CollDetCfg_ClearRegions : 7|1@0+ (1,0) [0|1] ""  ARS_ISF7
 SG_ CollDetCfg_WarningReset : 0|1@0+ (1,0) [0|1] ""  ARS_ISF7
 SG_ CollDetCfg_Activate : 1|1@0+ (1,0) [0|1] ""  ARS_ISF7
 SG_ CollDetCfg_MinTime_valid : 3|1@0+ (1,0) [0|1] ""  ARS_ISF7
 SG_ CollDetCfg_MinDetectTime : 15|8@0+ (0.1,0) [0|25.5] "s"  ARS_ISF7

BO_ 1137 CollDetRegionCfg7: 8 ExternalUnit
 SG_ CollDetRegCfg_Activate : 1|1@0+ (1,0) [0|1] ""  ARS_ISF7
 SG_ CollDetRegCfg_Coordinates_valid : 2|1@0+ (1,0) [0|1] ""  ARS_ISF7
 SG_ CollDetRegCfg_RegionID : 10|3@0+ (1,0) [0|7] ""  ARS_ISF7
 SG_ CollDetRegCfg_Point1X : 23|13@0+ (0.2,-500) [-500|1138.2] "m"  ARS_ISF7
 SG_ CollDetRegCfg_Point1Y : 26|11@0+ (0.2,-204.6) [-204.6|204.8] "m"  ARS_ISF7
 SG_ CollDetRegCfg_Point2X : 47|13@0+ (0.2,-500) [-500|1138.2] "m"  ARS_ISF7
 SG_ CollDetRegCfg_Point2Y : 50|11@0+ (0.2,-204.6) [-204.6|204.8] "m"  ARS_ISF7

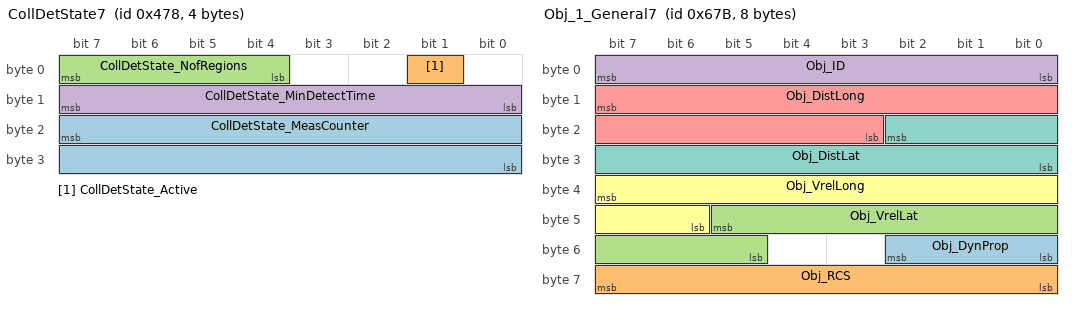
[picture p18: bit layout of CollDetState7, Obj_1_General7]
BO_ 1144 CollDetState7: 4 ARS_ISF7
 SG_ CollDetState_MeasCounter : 23|16@0+ (1,0) [0|65535] "" Vector__XXX
 SG_ CollDetState_Active : 1|1@0+ (1,0) [0|1] "" Vector__XXX
 SG_ CollDetState_NofRegions : 7|4@0+ (1,0) [0|15] ""  ExternalUnit
 SG_ CollDetState_MinDetectTime : 15|8@0+ (0.1,0) [0|25.5] "s"  ExternalUnit

BO_ 1648 Cluster_0_Status7: 5 ARS_ISF7
 SG_ Cluster_MeasCounter : 23|16@0+ (1,0) [0|65535] ""  ExternalUnit
 SG_ Cluster_NofClustersNear : 7|8@0+ (1,0) [0|255] ""  ExternalUnit
 SG_ Cluster_NofClustersFar : 15|8@0+ (1,0) [0|255] ""  ExternalUnit
 SG_ Cluster_InterfaceVersion : 39|4@0+ (1,0) [0|15] ""  ExternalUnit

BO_ 1658 Obj_0_Status7: 4 ARS_ISF7
 SG_ Obj_NofObjects : 7|8@0+ (1,0) [0|255] "1"  ExternalUnit
 SG_ Obj_MeasCounter : 15|16@0+ (1,0) [0|65535] ""  ExternalUnit
 SG_ Obj_InterfaceVersion : 31|4@0+ (1,0) [0|16] ""  ExternalUnit

BO_ 1659 Obj_1_General7: 8 ARS_ISF7
 SG_ Obj_DynProp : 50|3@0+ (1,0) [0|7] ""  ExternalUnit
 SG_ Obj_RCS : 63|8@0+ (0.5,-64) [-64|63.5] "dBm²"  ExternalUnit
 SG_ Obj_VrelLat : 45|9@0+ (0.25,-64) [-64|63.75] "m/s"  ExternalUnit
 SG_ Obj_ID : 7|8@0+ (1,0) [0|255] ""  ExternalUnit
 SG_ Obj_DistLong : 15|13@0+ (0.2,-500) [-500|1138.2] "m"  ExternalUnit
 SG_ Obj_VrelLong : 39|10@0+ (0.25,-128) [-128|127.75] "m/s"  ExternalUnit
 SG_ Obj_DistLat : 18|11@0+ (0.2,-204.6) [-204.6|204.8] "m"  ExternalUnit

BO_ 1904 VersionID7: 3 ARS_ISF7
 SG_ Version_MajorRelease : 7|8@0+ (1,0) [0|256] ""  ExternalUnit
 SG_ Version_MinorRelease : 15|8@0+ (1,0) [0|256] ""  ExternalUnit
 SG_ Version_PatchLevel : 23|8@0+ (1,0) [0|256] ""  ExternalUnit

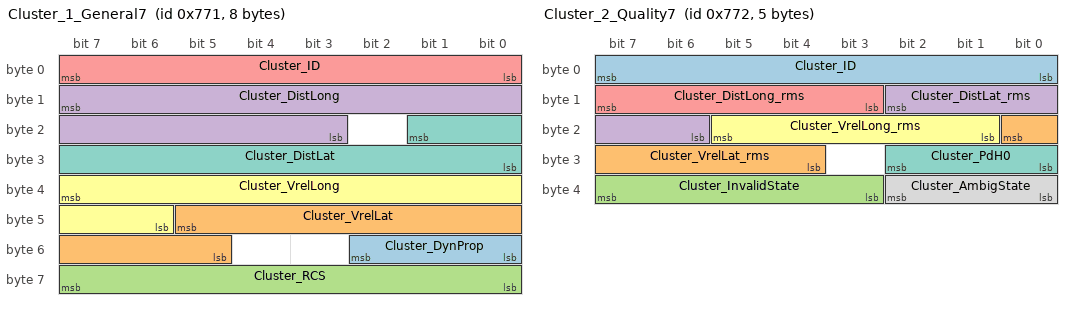
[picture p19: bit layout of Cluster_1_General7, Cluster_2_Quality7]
BO_ 1905 Cluster_1_General7: 8 ARS_ISF7
 SG_ Cluster_DynProp : 50|3@0+ (1,0) [0|7] "1"  ExternalUnit
 SG_ Cluster_VrelLat : 45|9@0+ (0.25,-64) [-64|63.75] "m/s"  ExternalUnit
 SG_ Cluster_RCS : 63|8@0+ (0.5,-64) [-64|63.5] "dBm²"  ExternalUnit
 SG_ Cluster_DistLong : 15|13@0+ (0.2,-500) [-500|1138.2] "m"  ExternalUnit
 SG_ Cluster_ID : 7|8@0+ (1,0) [0|255] "1"  ExternalUnit
 SG_ Cluster_VrelLong : 39|10@0+ (0.25,-128) [-128|127.75] "m/s"  ExternalUnit
 SG_ Cluster_DistLat : 17|10@0+ (0.2,-102.3) [-102.3|102.3] "m"  ExternalUnit

BO_ 1906 Cluster_2_Quality7: 5 ARS_ISF7
 SG_ Cluster_ID : 7|8@0+ (1,0) [0|255] "1"  ExternalUnit
 SG_ Cluster_VrelLat_rms : 16|5@0+ (1,0) [0|31] "m/s"  ExternalUnit
 SG_ Cluster_InvalidState : 39|5@0+ (1,0) [0|31] ""  ExternalUnit
 SG_ Cluster_DistLat_rms : 10|5@0+ (1,0) [0|31] "m"  ExternalUnit
 SG_ Cluster_DistLong_rms : 15|5@0+ (1,0) [0|31] "m"  ExternalUnit
 SG_ Cluster_VrelLong_rms : 21|5@0+ (1,0) [0|31] "m/s"  ExternalUnit
 SG_ Cluster_PdH0 : 26|3@0+ (1,0) [0|7] ""  ExternalUnit
 SG_ Cluster_AmbigState : 34|3@0+ (1,0) [0|7] "1"  ExternalUnit

CM_ BO_ 1612 "Quality object information";
CM_ SG_ 1612 Obj_ProbOfExist "Object probability of existence";
CM_ SG_ 1612 Obj_MeasState "Object measurement status";
CM_ SG_ 1612 Obj_ArelLong_rms "Object relative longitudinal acceleration standard deviation";
CM_ SG_ 1612 Obj_ArelLat_rms "Object relative lateral acceleration standard deviation";
CM_ SG_ 1612 Obj_VrelLong_rms "Object relative longitudinal velocity standard deviation";
CM_ SG_ 1612 Obj_VrelLat_rms "Object relative lateral velocity standard deviation";
CM_ SG_ 1612 Obj_Orientation_rms "Object orientation angle";
CM_ SG_ 1612 Obj_DistLong_rms "Object longitudinal distance standard deviation";
CM_ SG_ 1612 Obj_DistLat_rms "Object lateral distance standard deviation";
CM_ SG_ 1612 Obj_ID "Object ID";
CM_ BO_ 1613 "Extended object information";
CM_ SG_ 1613 Obj_Class "Object classification";
CM_ SG_ 1613 Obj_ArelLat "Object relative lateral acceleration";
CM_ SG_ 1613 Obj_ID "Object ID";
CM_ SG_ 1613 Obj_OrientationAngle "Object orientation angle";
CM_ SG_ 1613 Obj_Width "Object width";
CM_ SG_ 1613 Obj_Length "Object length";
CM_ SG_ 1613 Obj_ArelLong "Object relative longitudinal acceleration";
CM_ BO_ 1090 "Collision detection region configuration and warning status";
CM_ BO_ 1614 "Collision detection warning object information";
CM_ SG_ 1614 Obj_CollDetRegionBitfield "Region bit field with collision detection";
CM_ SG_ 1614 Obj_ID "Object ID";
CM_ BO_ 580 "Filter configuration status";
CM_ BO_ 579 "Header of filter configuration state";
CM_ BO_ 578 "Filter configuration";
CM_ BO_ 576 "Radar configuration";
CM_ SG_ 576 RadarCfg_RCS_Threshold_Valid "Allows changing the RCS_Threshold parameter";
CM_ SG_ 576 RadarCfg_RCS_Threshold "Standard or high sensitivity for cluster list output";
CM_ SG_ 576 RadarCfg_StoreInNVM_valid "Allows changing the StoreInNvm parameter";
CM_ SG_ 576 RadarCfg_SortIndex_valid "Allows changing the SortIndex parameter";
CM_ SG_ 576 RadarCfg_SortIndex "Object sort index";
CM_ SG_ 576 RadarCfg_StoreInNVM "Store configuration in Nvm";
CM_ SG_ 576 RadarCfg_SendExtInfo_valid "Allows changing the SendExtInfo parameter";
CM_ SG_ 576 RadarCfg_SendExtInfo "Enables output of extended message";
CM_ SG_ 576 RadarCfg_CtrlRelay_valid "Allows changing the CtrlRelay parameter";
CM_ SG_ 576 RadarCfg_CtrlRelay "Enables output of CtrlRelay message if CollDet is active";
CM_ SG_ 576 RadarCfg_SendQuality_valid "Allows changing the SendQuality parameter";
CM_ SG_ 576 RadarCfg_SendQuality "Enables output of quality message";
CM_ SG_ 576 RadarCfg_MaxDistance_valid "Allows changing the MaxDistance parameter";
CM_ SG_ 576 RadarCfg_RadarPower_valid "Allows changing the RadarPower parameter";
CM_ SG_ 576 RadarCfg_OutputType_valid "Allows changing the OutputType parameter";
CM_ SG_ 576 RadarCfg_SensorID_valid "Allows changing the SensorId parameter";
CM_ SG_ 576 RadarCfg_MaxDistance "Maximum distance of far scan";
CM_ SG_ 576 RadarCfg_RadarPower "Radar Tx output power reduction (Tx attenuation)";
CM_ SG_ 576 RadarCfg_OutputType "Data output type";
CM_ SG_ 576 RadarCfg_SensorID "Sensor ID (0 to 7)";
CM_ BO_ 577 "Radar configuration status";
CM_ SG_ 577 RadarState_SortIndex "Current sorting of object list";
CM_ SG_ 577 RadarState_RCS_Threshold "Current sensitivity mode";
CM_ SG_ 577 RadarState_CtrlRelayCfg "Status of control relay message output";
CM_ SG_ 577 RadarState_SendQualityCfg "Status of quality information output";
CM_ SG_ 577 RadarState_SendExtInfoCfg "Status of extended information output";
CM_ SG_ 577 RadarState_MotionRxState "Status of motion input signals";
CM_ SG_ 577 RadarState_SensorID "Sensor ID (0 to 7)";
CM_ SG_ 577 RadarState_OutputTypeCfg "Current output list type";
CM_ SG_ 577 RadarState_RadarPowerCfg "Radar Tx output level (Tx attenuation)";
CM_ SG_ 577 RadarState_NVMReadStatus "Gives the status of reading the radar configuration from EEPROM";
CM_ SG_ 577 RadarState_NVMwriteStatus "Gives the status of writing the radar configuration from EEPROM
";
CM_ SG_ 577 RadarState_MaxDistanceCfg "Currently configured maximum distance of far scan";
CM_ BO_ 832 "Device movement speed";
CM_ SG_ 832 RadarDevice_Speed "Speed of the radar unit";
CM_ SG_ 832 RadarDevice_SpeedDirection "Speed direction of the radar unit";
CM_ BO_ 833 "Device movement yaw rate";
CM_ SG_ 833 RadarDevice_YawRate "Yaw rate of the radar unit";
CM_ BO_ 1088 "Collision detection configuration";
CM_ BO_ 1089 "Collision detection region configuration";
CM_ BO_ 1096 "Collision detection configuration status";
CM_ BO_ 1600 "Status information about Clusters";
CM_ SG_ 1600 Cluster_MeasCounter "Measurement counter";
CM_ SG_ 1600 Cluster_NofClustersNear "Number of valid Clusters in near range scan";
CM_ SG_ 1600 Cluster_NofClustersFar "Number of valid Clusters in far range scan";
CM_ SG_ 1600 Cluster_InterfaceVersion "Cluster CAN Interface Version Number";
CM_ BO_ 1610 "Status information about object";
CM_ SG_ 1610 Obj_NofObjects "Number of Objects sent";
CM_ SG_ 1610 Obj_MeasCounter "Measurement Counter";
CM_ SG_ 1610 Obj_InterfaceVersion "Object CAN Interface Version Number";
CM_ BO_ 1611 "General object information";
CM_ SG_ 1611 Obj_DynProp "Object dynamic property";
CM_ SG_ 1611 Obj_RCS "Object RCS value (radar cross section)";
CM_ SG_ 1611 Obj_VrelLat "Object relative lateral velocity";
CM_ SG_ 1611 Obj_ID "Object ID";
CM_ SG_ 1611 Obj_DistLong "Object longitudinal displacement";
CM_ SG_ 1611 Obj_VrelLong "Object relative longitudinal velocity";
CM_ SG_ 1611 Obj_DistLat "Object lateral displacement";
CM_ BO_ 1856 "Firmware version";
CM_ SG_ 1856 Version_MajorRelease "Major Release Number";
CM_ SG_ 1856 Version_MinorRelease "Minor Release Number";
CM_ SG_ 1856 Version_PatchLevel "Patch Level";
CM_ BO_ 1857 "General Cluster information";
CM_ SG_ 1857 Cluster_DynProp "Cluster dynamic property";
CM_ SG_ 1857 Cluster_VrelLat "Cluster relative lateral velocity";
CM_ SG_ 1857 Cluster_RCS "Cluster RCS value (Radar cross section)";
CM_ SG_ 1857 Cluster_DistLong "Cluster longitudinal distance";
CM_ SG_ 1857 Cluster_ID "Cluster number";
CM_ SG_ 1857 Cluster_VrelLong "Cluster relative longitudinal velocity";
CM_ SG_ 1857 Cluster_DistLat "Cluster lateral distance";
CM_ BO_ 1858 "Quality Cluster information";
CM_ SG_ 1858 Cluster_ID "Cluster number";
CM_ SG_ 1858 Cluster_VrelLat_rms "Cluster relative lateral velocity standard deviation";
CM_ SG_ 1858 Cluster_InvalidState "Cluster invalid state";
CM_ SG_ 1858 Cluster_DistLat_rms "Cluster lateral distance standard deviation";
CM_ SG_ 1858 Cluster_DistLong_rms "Cluster longitudinal distance standard deviation";
CM_ SG_ 1858 Cluster_VrelLong_rms "Cluster relative longitudinal velocity standard deviation";
CM_ SG_ 1858 Cluster_PdH0 "Cluster false alarm probability";
CM_ SG_ 1858 Cluster_AmbigState "Cluster Doppler ambiguity status";
CM_ BO_ 1628 "Quality object information";
CM_ SG_ 1628 Obj_ProbOfExist "Object probability of existence";
CM_ SG_ 1628 Obj_MeasState "Object measurement status";
CM_ SG_ 1628 Obj_ArelLong_rms "Object relative longitudinal acceleration standard deviation";
CM_ SG_ 1628 Obj_ArelLat_rms "Object relative lateral acceleration standard deviation";
CM_ SG_ 1628 Obj_VrelLong_rms "Object relative longitudinal velocity standard deviation";
CM_ SG_ 1628 Obj_VrelLat_rms "Object relative lateral velocity standard deviation";
CM_ SG_ 1628 Obj_Orientation_rms "Object orientation angle";
CM_ SG_ 1628 Obj_DistLong_rms "Object longitudinal distance standard deviation";
CM_ SG_ 1628 Obj_DistLat_rms "Object lateral distance standard deviation";
CM_ SG_ 1628 Obj_ID "Object ID";
CM_ BO_ 1629 "Extended object information";
CM_ SG_ 1629 Obj_Class "Object classification";
CM_ SG_ 1629 Obj_ArelLat "Object relative lateral acceleration";
CM_ SG_ 1629 Obj_ID "Object ID";
CM_ SG_ 1629 Obj_OrientationAngle "Object orientation angle";
CM_ SG_ 1629 Obj_Width "Object width";
CM_ SG_ 1629 Obj_Length "Object length";
CM_ SG_ 1629 Obj_ArelLong "Object relative longitudinal acceleration";
CM_ BO_ 1106 "Collision detection region configuration and warning status";
CM_ BO_ 1630 "Collision detection warning object information";
CM_ SG_ 1630 Obj_CollDetRegionBitfield "Region bit field with collision detection";
CM_ SG_ 1630 Obj_ID "Object ID";
CM_ BO_ 596 "Filter configuration status";
CM_ BO_ 595 "Header of filter configuration state";
CM_ BO_ 594 "Filter configuration";
CM_ BO_ 592 "Radar configuration";
CM_ SG_ 592 RadarCfg_RCS_Threshold_Valid "Allows changing the RCS_Threshold parameter";
CM_ SG_ 592 RadarCfg_RCS_Threshold "Standard or high sensitivity for cluster list output";
CM_ SG_ 592 RadarCfg_StoreInNVM_valid "Allows changing the StoreInNvm parameter";
CM_ SG_ 592 RadarCfg_SortIndex_valid "Allows changing the SortIndex parameter";
CM_ SG_ 592 RadarCfg_SortIndex "Object sort index";
CM_ SG_ 592 RadarCfg_StoreInNVM "Store configuration in Nvm";
CM_ SG_ 592 RadarCfg_SendExtInfo_valid "Allows changing the SendExtInfo parameter";
CM_ SG_ 592 RadarCfg_SendExtInfo "Enables output of extended message";
CM_ SG_ 592 RadarCfg_CtrlRelay_valid "Allows changing the CtrlRelay parameter";
CM_ SG_ 592 RadarCfg_CtrlRelay "Enables output of CtrlRelay message if CollDet is active";
CM_ SG_ 592 RadarCfg_SendQuality_valid "Allows changing the SendQuality parameter";
CM_ SG_ 592 RadarCfg_SendQuality "Enables output of quality message";
CM_ SG_ 592 RadarCfg_MaxDistance_valid "Allows changing the MaxDistance parameter";
CM_ SG_ 592 RadarCfg_RadarPower_valid "Allows changing the RadarPower parameter";
CM_ SG_ 592 RadarCfg_OutputType_valid "Allows changing the OutputType parameter";
CM_ SG_ 592 RadarCfg_SensorID_valid "Allows changing the SensorId parameter";
CM_ SG_ 592 RadarCfg_MaxDistance "Maximum distance of far scan";
CM_ SG_ 592 RadarCfg_RadarPower "Radar Tx output power reduction (Tx attenuation)";
CM_ SG_ 592 RadarCfg_OutputType "Data output type";
CM_ SG_ 592 RadarCfg_SensorID "Sensor ID (0 to 7)";
CM_ BO_ 593 "Radar configuration status";
CM_ SG_ 593 RadarState_SortIndex "Current sorting of object list";
CM_ SG_ 593 RadarState_RCS_Threshold "Current sensitivity mode";
CM_ SG_ 593 RadarState_CtrlRelayCfg "Status of control relay message output";
CM_ SG_ 593 RadarState_SendQualityCfg "Status of quality information output";
CM_ SG_ 593 RadarState_SendExtInfoCfg "Status of extended information output";
CM_ SG_ 593 RadarState_MotionRxState "Status of motion input signals";
CM_ SG_ 593 RadarState_SensorID "Sensor ID (0 to 7)";
CM_ SG_ 593 RadarState_OutputTypeCfg "Current output list type";
CM_ SG_ 593 RadarState_RadarPowerCfg "Radar Tx output level (Tx attenuation)";
CM_ SG_ 593 RadarState_NVMReadStatus "Gives the status of reading the radar configuration from EEPROM";
CM_ SG_ 593 RadarState_NVMwriteStatus "Gives the status of writing the radar configuration from EEPROM
";
CM_ SG_ 593 RadarState_MaxDistanceCfg "Currently configured maximum distance of far scan";
CM_ BO_ 848 "Device movement speed";
CM_ SG_ 848 RadarDevice_Speed "Speed of the radar unit";
CM_ SG_ 848 RadarDevice_SpeedDirection "Speed direction of the radar unit";
CM_ BO_ 849 "Device movement yaw rate";
CM_ SG_ 849 RadarDevice_YawRate "Yaw rate of the radar unit";
CM_ BO_ 1104 "Collision detection configuration";
CM_ BO_ 1105 "Collision detection region configuration";
CM_ BO_ 1112 "Collision detection configuration status";
CM_ BO_ 1616 "Status information about Clusters";
CM_ SG_ 1616 Cluster_MeasCounter "Measurement counter";
CM_ SG_ 1616 Cluster_NofClustersNear "Number of valid Clusters in near range scan";
CM_ SG_ 1616 Cluster_NofClustersFar "Number of valid Clusters in far range scan";
CM_ SG_ 1616 Cluster_InterfaceVersion "Cluster CAN Interface Version Number";
CM_ BO_ 1626 "Status information about object";
CM_ SG_ 1626 Obj_NofObjects "Number of Objects sent";
CM_ SG_ 1626 Obj_MeasCounter "Measurement Counter";
CM_ SG_ 1626 Obj_InterfaceVersion "Object CAN Interface Version Number";
CM_ BO_ 1627 "General object information";
CM_ SG_ 1627 Obj_DynProp "Object dynamic property";
CM_ SG_ 1627 Obj_RCS "Object RCS value (radar cross section)";
CM_ SG_ 1627 Obj_VrelLat "Object relative lateral velocity";
CM_ SG_ 1627 Obj_ID "Object ID";
CM_ SG_ 1627 Obj_DistLong "Object longitudinal displacement";
CM_ SG_ 1627 Obj_VrelLong "Object relative longitudinal velocity";
CM_ SG_ 1627 Obj_DistLat "Object lateral displacement";
CM_ BO_ 1872 "Firmware version";
CM_ SG_ 1872 Version_MajorRelease "Major Release Number";
CM_ SG_ 1872 Version_MinorRelease "Minor Release Number";
CM_ SG_ 1872 Version_PatchLevel "Patch Level";
CM_ BO_ 1873 "General Cluster information";
CM_ SG_ 1873 Cluster_DynProp "Cluster dynamic property";
CM_ SG_ 1873 Cluster_VrelLat "Cluster relative lateral velocity";
CM_ SG_ 1873 Cluster_RCS "Cluster RCS value (Radar cross section)";
CM_ SG_ 1873 Cluster_DistLong "Cluster longitudinal distance";
CM_ SG_ 1873 Cluster_ID "Cluster number";
CM_ SG_ 1873 Cluster_VrelLong "Cluster relative longitudinal velocity";
CM_ SG_ 1873 Cluster_DistLat "Cluster lateral distance";
CM_ BO_ 1874 "Quality Cluster information";
CM_ SG_ 1874 Cluster_ID "Cluster number";
CM_ SG_ 1874 Cluster_VrelLat_rms "Cluster relative lateral velocity standard deviation";
CM_ SG_ 1874 Cluster_InvalidState "Cluster invalid state";
CM_ SG_ 1874 Cluster_DistLat_rms "Cluster lateral distance standard deviation";
CM_ SG_ 1874 Cluster_DistLong_rms "Cluster longitudinal distance standard deviation";
CM_ SG_ 1874 Cluster_VrelLong_rms "Cluster relative longitudinal velocity standard deviation";
CM_ SG_ 1874 Cluster_PdH0 "Cluster false alarm probability";
CM_ SG_ 1874 Cluster_AmbigState "Cluster Doppler ambiguity status";
CM_ BO_ 1644 "Quality object information";
CM_ SG_ 1644 Obj_ProbOfExist "Object probability of existence";
CM_ SG_ 1644 Obj_MeasState "Object measurement status";
CM_ SG_ 1644 Obj_ArelLong_rms "Object relative longitudinal acceleration standard deviation";
CM_ SG_ 1644 Obj_ArelLat_rms "Object relative lateral acceleration standard deviation";
CM_ SG_ 1644 Obj_VrelLong_rms "Object relative longitudinal velocity standard deviation";
CM_ SG_ 1644 Obj_VrelLat_rms "Object relative lateral velocity standard deviation";
CM_ SG_ 1644 Obj_Orientation_rms "Object orientation angle";
CM_ SG_ 1644 Obj_DistLong_rms "Object longitudinal distance standard deviation";
CM_ SG_ 1644 Obj_DistLat_rms "Object lateral distance standard deviation";
CM_ SG_ 1644 Obj_ID "Object ID";
CM_ BO_ 1645 "Extended object information";
CM_ SG_ 1645 Obj_Class "Object classification";
CM_ SG_ 1645 Obj_ArelLat "Object relative lateral acceleration";
CM_ SG_ 1645 Obj_ID "Object ID";
CM_ SG_ 1645 Obj_OrientationAngle "Object orientation angle";
CM_ SG_ 1645 Obj_Width "Object width";
CM_ SG_ 1645 Obj_Length "Object length";
CM_ SG_ 1645 Obj_ArelLong "Object relative longitudinal acceleration";
CM_ BO_ 1122 "Collision detection region configuration and warning status";
CM_ BO_ 1646 "Collision detection warning object information";
CM_ SG_ 1646 Obj_CollDetRegionBitfield "Region bit field with collision detection";
CM_ SG_ 1646 Obj_ID "Object ID";
CM_ BO_ 612 "Filter configuration status";
CM_ BO_ 611 "Header of filter configuration state";
CM_ BO_ 610 "Filter configuration";
CM_ BO_ 608 "Radar configuration";
CM_ SG_ 608 RadarCfg_RCS_Threshold_Valid "Allows changing the RCS_Threshold parameter";
CM_ SG_ 608 RadarCfg_RCS_Threshold "Standard or high sensitivity for cluster list output";
CM_ SG_ 608 RadarCfg_StoreInNVM_valid "Allows changing the StoreInNvm parameter";
CM_ SG_ 608 RadarCfg_SortIndex_valid "Allows changing the SortIndex parameter";
CM_ SG_ 608 RadarCfg_SortIndex "Object sort index";
CM_ SG_ 608 RadarCfg_StoreInNVM "Store configuration in Nvm";
CM_ SG_ 608 RadarCfg_SendExtInfo_valid "Allows changing the SendExtInfo parameter";
CM_ SG_ 608 RadarCfg_SendExtInfo "Enables output of extended message";
CM_ SG_ 608 RadarCfg_CtrlRelay_valid "Allows changing the CtrlRelay parameter";
CM_ SG_ 608 RadarCfg_CtrlRelay "Enables output of CtrlRelay message if CollDet is active";
CM_ SG_ 608 RadarCfg_SendQuality_valid "Allows changing the SendQuality parameter";
CM_ SG_ 608 RadarCfg_SendQuality "Enables output of quality message";
CM_ SG_ 608 RadarCfg_MaxDistance_valid "Allows changing the MaxDistance parameter";
CM_ SG_ 608 RadarCfg_RadarPower_valid "Allows changing the RadarPower parameter";
CM_ SG_ 608 RadarCfg_OutputType_valid "Allows changing the OutputType parameter";
CM_ SG_ 608 RadarCfg_SensorID_valid "Allows changing the SensorId parameter";
CM_ SG_ 608 RadarCfg_MaxDistance "Maximum distance of far scan";
CM_ SG_ 608 RadarCfg_RadarPower "Radar Tx output power reduction (Tx attenuation)";
CM_ SG_ 608 RadarCfg_OutputType "Data output type";
CM_ SG_ 608 RadarCfg_SensorID "Sensor ID (0 to 7)";
CM_ BO_ 609 "Radar configuration status";
CM_ SG_ 609 RadarState_SortIndex "Current sorting of object list";
CM_ SG_ 609 RadarState_RCS_Threshold "Current sensitivity mode";
CM_ SG_ 609 RadarState_CtrlRelayCfg "Status of control relay message output";
CM_ SG_ 609 RadarState_SendQualityCfg "Status of quality information output";
CM_ SG_ 609 RadarState_SendExtInfoCfg "Status of extended information output";
CM_ SG_ 609 RadarState_MotionRxState "Status of motion input signals";
CM_ SG_ 609 RadarState_SensorID "Sensor ID (0 to 7)";
CM_ SG_ 609 RadarState_OutputTypeCfg "Current output list type";
CM_ SG_ 609 RadarState_RadarPowerCfg "Radar Tx output level (Tx attenuation)";
CM_ SG_ 609 RadarState_NVMReadStatus "Gives the status of reading the radar configuration from EEPROM";
CM_ SG_ 609 RadarState_NVMwriteStatus "Gives the status of writing the radar configuration from EEPROM
";
CM_ SG_ 609 RadarState_MaxDistanceCfg "Currently configured maximum distance of far scan";
CM_ BO_ 864 "Device movement speed";
CM_ SG_ 864 RadarDevice_Speed "Speed of the radar unit";
CM_ SG_ 864 RadarDevice_SpeedDirection "Speed direction of the radar unit";
CM_ BO_ 865 "Device movement yaw rate";
CM_ SG_ 865 RadarDevice_YawRate "Yaw rate of the radar unit";
CM_ BO_ 1120 "Collision detection configuration";
CM_ BO_ 1121 "Collision detection region configuration";
CM_ BO_ 1128 "Collision detection configuration status";
CM_ BO_ 1632 "Status information about Clusters";
CM_ SG_ 1632 Cluster_MeasCounter "Measurement counter";
CM_ SG_ 1632 Cluster_NofClustersNear "Number of valid Clusters in near range scan";
CM_ SG_ 1632 Cluster_NofClustersFar "Number of valid Clusters in far range scan";
CM_ SG_ 1632 Cluster_InterfaceVersion "Cluster CAN Interface Version Number";
CM_ BO_ 1642 "Status information about object";
CM_ SG_ 1642 Obj_NofObjects "Number of Objects sent";
CM_ SG_ 1642 Obj_MeasCounter "Measurement Counter";
CM_ SG_ 1642 Obj_InterfaceVersion "Object CAN Interface Version Number";
CM_ BO_ 1643 "General object information";
CM_ SG_ 1643 Obj_DynProp "Object dynamic property";
CM_ SG_ 1643 Obj_RCS "Object RCS value (radar cross section)";
CM_ SG_ 1643 Obj_VrelLat "Object relative lateral velocity";
CM_ SG_ 1643 Obj_ID "Object ID";
CM_ SG_ 1643 Obj_DistLong "Object longitudinal displacement";
CM_ SG_ 1643 Obj_VrelLong "Object relative longitudinal velocity";
CM_ SG_ 1643 Obj_DistLat "Object lateral displacement";
CM_ BO_ 1888 "Firmware version";
CM_ SG_ 1888 Version_MajorRelease "Major Release Number";
CM_ SG_ 1888 Version_MinorRelease "Minor Release Number";
CM_ SG_ 1888 Version_PatchLevel "Patch Level";
CM_ BO_ 1889 "General Cluster information";
CM_ SG_ 1889 Cluster_DynProp "Cluster dynamic property";
CM_ SG_ 1889 Cluster_VrelLat "Cluster relative lateral velocity";
CM_ SG_ 1889 Cluster_RCS "Cluster RCS value (Radar cross section)";
CM_ SG_ 1889 Cluster_DistLong "Cluster longitudinal distance";
CM_ SG_ 1889 Cluster_ID "Cluster number";
CM_ SG_ 1889 Cluster_VrelLong "Cluster relative longitudinal velocity";
CM_ SG_ 1889 Cluster_DistLat "Cluster lateral distance";
CM_ BO_ 1890 "Quality Cluster information";
CM_ SG_ 1890 Cluster_ID "Cluster number";
CM_ SG_ 1890 Cluster_VrelLat_rms "Cluster relative lateral velocity standard deviation";
CM_ SG_ 1890 Cluster_InvalidState "Cluster invalid state";
CM_ SG_ 1890 Cluster_DistLat_rms "Cluster lateral distance standard deviation";
CM_ SG_ 1890 Cluster_DistLong_rms "Cluster longitudinal distance standard deviation";
CM_ SG_ 1890 Cluster_VrelLong_rms "Cluster relative longitudinal velocity standard deviation";
CM_ SG_ 1890 Cluster_PdH0 "Cluster false alarm probability";
CM_ SG_ 1890 Cluster_AmbigState "Cluster Doppler ambiguity status";
CM_ BO_ 1660 "Quality object information";
CM_ SG_ 1660 Obj_ProbOfExist "Object probability of existence";
CM_ SG_ 1660 Obj_MeasState "Object measurement status";
CM_ SG_ 1660 Obj_ArelLong_rms "Object relative longitudinal acceleration standard deviation";
CM_ SG_ 1660 Obj_ArelLat_rms "Object relative lateral acceleration standard deviation";
CM_ SG_ 1660 Obj_VrelLong_rms "Object relative longitudinal velocity standard deviation";
CM_ SG_ 1660 Obj_VrelLat_rms "Object relative lateral velocity standard deviation";
CM_ SG_ 1660 Obj_Orientation_rms "Object orientation angle";
CM_ SG_ 1660 Obj_DistLong_rms "Object longitudinal distance standard deviation";
CM_ SG_ 1660 Obj_DistLat_rms "Object lateral distance standard deviation";
CM_ SG_ 1660 Obj_ID "Object ID";
CM_ BO_ 1661 "Extended object information";
CM_ SG_ 1661 Obj_Class "Object classification";
CM_ SG_ 1661 Obj_ArelLat "Object relative lateral acceleration";
CM_ SG_ 1661 Obj_ID "Object ID";
CM_ SG_ 1661 Obj_OrientationAngle "Object orientation angle";
CM_ SG_ 1661 Obj_Width "Object width";
CM_ SG_ 1661 Obj_Length "Object length";
CM_ SG_ 1661 Obj_ArelLong "Object relative longitudinal acceleration";
CM_ BO_ 1138 "Collision detection region configuration and warning status";
CM_ BO_ 1662 "Collision detection warning object information";
CM_ SG_ 1662 Obj_CollDetRegionBitfield "Region bit field with collision detection";
CM_ SG_ 1662 Obj_ID "Object ID";
CM_ BO_ 628 "Filter configuration status";
CM_ BO_ 627 "Header of filter configuration state";
CM_ BO_ 626 "Filter configuration";
CM_ BO_ 624 "Radar configuration";
CM_ SG_ 624 RadarCfg_RCS_Threshold_Valid "Allows changing the RCS_Threshold parameter";
CM_ SG_ 624 RadarCfg_RCS_Threshold "Standard or high sensitivity for cluster list output";
CM_ SG_ 624 RadarCfg_StoreInNVM_valid "Allows changing the StoreInNvm parameter";
CM_ SG_ 624 RadarCfg_SortIndex_valid "Allows changing the SortIndex parameter";
CM_ SG_ 624 RadarCfg_SortIndex "Object sort index";
CM_ SG_ 624 RadarCfg_StoreInNVM "Store configuration in Nvm";
CM_ SG_ 624 RadarCfg_SendExtInfo_valid "Allows changing the SendExtInfo parameter";
CM_ SG_ 624 RadarCfg_SendExtInfo "Enables output of extended message";
CM_ SG_ 624 RadarCfg_CtrlRelay_valid "Allows changing the CtrlRelay parameter";
CM_ SG_ 624 RadarCfg_CtrlRelay "Enables output of CtrlRelay message if CollDet is active";
CM_ SG_ 624 RadarCfg_SendQuality_valid "Allows changing the SendQuality parameter";
CM_ SG_ 624 RadarCfg_SendQuality "Enables output of quality message";
CM_ SG_ 624 RadarCfg_MaxDistance_valid "Allows changing the MaxDistance parameter";
CM_ SG_ 624 RadarCfg_RadarPower_valid "Allows changing the RadarPower parameter";
CM_ SG_ 624 RadarCfg_OutputType_valid "Allows changing the OutputType parameter";
CM_ SG_ 624 RadarCfg_SensorID_valid "Allows changing the SensorId parameter";
CM_ SG_ 624 RadarCfg_MaxDistance "Maximum distance of far scan";
CM_ SG_ 624 RadarCfg_RadarPower "Radar Tx output power reduction (Tx attenuation)";
CM_ SG_ 624 RadarCfg_OutputType "Data output type";
CM_ SG_ 624 RadarCfg_SensorID "Sensor ID (0 to 7)";
CM_ BO_ 625 "Radar configuration status";
CM_ SG_ 625 RadarState_SortIndex "Current sorting of object list";
CM_ SG_ 625 RadarState_RCS_Threshold "Current sensitivity mode";
CM_ SG_ 625 RadarState_CtrlRelayCfg "Status of control relay message output";
CM_ SG_ 625 RadarState_SendQualityCfg "Status of quality information output";
CM_ SG_ 625 RadarState_SendExtInfoCfg "Status of extended information output";
CM_ SG_ 625 RadarState_MotionRxState "Status of motion input signals";
CM_ SG_ 625 RadarState_SensorID "Sensor ID (0 to 7)";
CM_ SG_ 625 RadarState_OutputTypeCfg "Current output list type";
CM_ SG_ 625 RadarState_RadarPowerCfg "Radar Tx output level (Tx attenuation)";
CM_ SG_ 625 RadarState_NVMReadStatus "Gives the status of reading the radar configuration from EEPROM";
CM_ SG_ 625 RadarState_NVMwriteStatus "Gives the status of writing the radar configuration from EEPROM
";
CM_ SG_ 625 RadarState_MaxDistanceCfg "Currently configured maximum distance of far scan";
CM_ BO_ 880 "Device movement speed";
CM_ SG_ 880 RadarDevice_Speed "Speed of the radar unit";
CM_ SG_ 880 RadarDevice_SpeedDirection "Speed direction of the radar unit";
CM_ BO_ 881 "Device movement yaw rate";
CM_ SG_ 881 RadarDevice_YawRate "Yaw rate of the radar unit";
CM_ BO_ 1136 "Collision detection configuration";
CM_ BO_ 1137 "Collision detection region configuration";
CM_ BO_ 1144 "Collision detection configuration status";
CM_ BO_ 1648 "Status information about Clusters";
CM_ SG_ 1648 Cluster_MeasCounter "Measurement counter";
CM_ SG_ 1648 Cluster_NofClustersNear "Number of valid Clusters in near range scan";
CM_ SG_ 1648 Cluster_NofClustersFar "Number of valid Clusters in far range scan";
CM_ SG_ 1648 Cluster_InterfaceVersion "Cluster CAN Interface Version Number";
CM_ BO_ 1658 "Status information about object";
CM_ SG_ 1658 Obj_NofObjects "Number of Objects sent";
CM_ SG_ 1658 Obj_MeasCounter "Measurement Counter";
CM_ SG_ 1658 Obj_InterfaceVersion "Object CAN Interface Version Number";
CM_ BO_ 1659 "General object information";
CM_ SG_ 1659 Obj_DynProp "Object dynamic property";
CM_ SG_ 1659 Obj_RCS "Object RCS value (radar cross section)";
CM_ SG_ 1659 Obj_VrelLat "Object relative lateral velocity";
CM_ SG_ 1659 Obj_ID "Object ID";
CM_ SG_ 1659 Obj_DistLong "Object longitudinal displacement";
CM_ SG_ 1659 Obj_VrelLong "Object relative longitudinal velocity";
CM_ SG_ 1659 Obj_DistLat "Object lateral displacement";
CM_ BO_ 1904 "Firmware version";
CM_ SG_ 1904 Version_MajorRelease "Major Release Number";
CM_ SG_ 1904 Version_MinorRelease "Minor Release Number";
CM_ SG_ 1904 Version_PatchLevel "Patch Level";
CM_ BO_ 1905 "General Cluster information";
CM_ SG_ 1905 Cluster_DynProp "Cluster dynamic property";
CM_ SG_ 1905 Cluster_VrelLat "Cluster relative lateral velocity";
CM_ SG_ 1905 Cluster_RCS "Cluster RCS value (Radar cross section)";
CM_ SG_ 1905 Cluster_DistLong "Cluster longitudinal distance";
CM_ SG_ 1905 Cluster_ID "Cluster number";
CM_ SG_ 1905 Cluster_VrelLong "Cluster relative longitudinal velocity";
CM_ SG_ 1905 Cluster_DistLat "Cluster lateral distance";
CM_ BO_ 1906 "Quality Cluster information";
CM_ SG_ 1906 Cluster_ID "Cluster number";
CM_ SG_ 1906 Cluster_VrelLat_rms "Cluster relative lateral velocity standard deviation";
CM_ SG_ 1906 Cluster_InvalidState "Cluster invalid state";
CM_ SG_ 1906 Cluster_DistLat_rms "Cluster lateral distance standard deviation";
CM_ SG_ 1906 Cluster_DistLong_rms "Cluster longitudinal distance standard deviation";
CM_ SG_ 1906 Cluster_VrelLong_rms "Cluster relative longitudinal velocity standard deviation";
CM_ SG_ 1906 Cluster_PdH0 "Cluster false alarm probability";
CM_ SG_ 1906 Cluster_AmbigState "Cluster Doppler ambiguity status";
BA_DEF_ SG_  "GenSigStartValue" HEX 0 4294967295;
BA_DEF_ SG_  "GenSigCycleTime" INT 0 65535;
BA_DEF_ SG_  "GenSigSendType" ENUM  "cyclicX","spontanX","cyclicIfActiveX","spontanWithDelay","cyclicAndSpontanX","cyclicAndSpontanWithDelay","spontanWithRepitition","cyclicIfActiveAndSpontanWD","cyclicIfActiveFast","cyclicWithRepeatOnDemand","none";
BA_DEF_ BO_  "GenMsgNrOfRepetitions" INT 0 65535;
BA_DEF_ BO_  "GenMsgDelayTime" INT 0 65535;
BA_DEF_ BO_  "GenMsgCycleTime" INT 0 65535;
BA_DEF_ BO_  "GenMsgSendType" ENUM  "cyclicX","spontanX","cyclicIfActiveX","spontanWithDelay","cyclicAndSpontanX","cyclicAndSpontanWithDelay","spontanWithRepitition","cyclicIfActiveAndSpontanWD","cyclicIfActiveFast","cyclicWithRepeatOnDemand","none";
BA_DEF_ BO_  "DiagResponse" ENUM  "nein","ja";
BA_DEF_ BO_  "DiagRequest" ENUM  "nein","ja";
BA_DEF_ BO_  "DiagState" ENUM  "nein","ja";
BA_DEF_ BO_  "App-Botschaft" ENUM  "nein","ja";
BA_DEF_ BO_  "NWM-Botschaft" ENUM  "nein","ja";
BA_DEF_DEF_  "GenSigStartValue" 0;
BA_DEF_DEF_  "GenSigCycleTime" 0;
BA_DEF_DEF_  "GenSigSendType" "";
BA_DEF_DEF_  "GenMsgNrOfRepetitions" 0;
BA_DEF_DEF_  "GenMsgDelayTime" 0;
BA_DEF_DEF_  "GenMsgCycleTime" 0;
BA_DEF_DEF_  "GenMsgSendType" "";
BA_DEF_DEF_  "DiagResponse" "";
BA_DEF_DEF_  "DiagRequest" "";
BA_DEF_DEF_  "DiagState" "";
BA_DEF_DEF_  "App-Botschaft" "";
BA_DEF_DEF_  "NWM-Botschaft" "";
BA_ "GenSigStartValue" SG_ 1613 Obj_ArelLat 250;
BA_ "GenSigStartValue" SG_ 1613 Obj_OrientationAngle 450;
BA_ "GenSigStartValue" SG_ 1613 Obj_ArelLong 1000;
BA_ "GenSigStartValue" SG_ 1090 CollDetRegState_Point2Y 1023;
BA_ "GenSigStartValue" SG_ 1090 CollDetRegState_Point2X 2500;
BA_ "GenSigStartValue" SG_ 1090 CollDetRegState_Point1Y 1023;
BA_ "GenSigStartValue" SG_ 1090 CollDetRegState_Point1X 2500;
BA_ "GenSigStartValue" SG_ 580 FilterState_Min_Y 2047.5;
BA_ "GenSigStartValue" SG_ 580 FilterState_Min_X 2047.5;
BA_ "GenSigStartValue" SG_ 580 FilterState_Max_Y 2047.5;
BA_ "GenSigStartValue" SG_ 580 FilterState_Max_X 2047.5;
BA_ "GenSigStartValue" SG_ 580 FilterState_Min_RCS 2000;
BA_ "GenSigStartValue" SG_ 580 FilterState_Min_Azimuth 2000;
BA_ "GenSigStartValue" SG_ 580 FilterState_Max_RCS 2000;
BA_ "GenSigStartValue" SG_ 580 FilterState_Max_Azimuth 2000;
BA_ "GenSigStartValue" SG_ 578 FilterCfg_Min_Y 2047.5;
BA_ "GenSigStartValue" SG_ 578 FilterCfg_Min_X 2500;
BA_ "GenSigStartValue" SG_ 578 FilterCfg_Max_Y 2047.5;
BA_ "GenSigStartValue" SG_ 578 FilterCfg_Max_X 2500;
BA_ "GenSigStartValue" SG_ 578 FilterCfg_Max_RCS 2000;
BA_ "GenSigStartValue" SG_ 578 FilterCfg_Max_Azimuth 2000;
BA_ "GenSigStartValue" SG_ 578 FilterCfg_Min_RCS 2000;
BA_ "GenSigStartValue" SG_ 578 FilterCfg_Min_Azimuth 2000;
BA_ "GenSigCycleTime" SG_ 577 RadarState_MotionRxState 50;
BA_ "GenSigSendType" SG_ 577 RadarState_MotionRxState 0;
BA_ "GenSigStartValue" SG_ 1089 CollDetRegCfg_Point1X 2500;
BA_ "GenSigStartValue" SG_ 1089 CollDetRegCfg_Point1Y 1023;
BA_ "GenSigStartValue" SG_ 1089 CollDetRegCfg_Point2X 2500;
BA_ "GenSigStartValue" SG_ 1089 CollDetRegCfg_Point2Y 1023;
BA_ "GenSigStartValue" SG_ 1611 Obj_VrelLat 256;
BA_ "GenSigStartValue" SG_ 1611 Obj_DistLong 2500;
BA_ "GenSigStartValue" SG_ 1611 Obj_VrelLong 512;
BA_ "GenSigStartValue" SG_ 1611 Obj_DistLat 1023;
BA_ "GenSigStartValue" SG_ 1857 Cluster_VrelLat 256;
BA_ "GenSigStartValue" SG_ 1857 Cluster_DistLong 2500;
BA_ "GenSigStartValue" SG_ 1857 Cluster_VrelLong 512;
BA_ "GenSigStartValue" SG_ 1857 Cluster_DistLat 511.5;
BA_ "GenSigStartValue" SG_ 1629 Obj_ArelLat 250;
BA_ "GenSigStartValue" SG_ 1629 Obj_OrientationAngle 450;
BA_ "GenSigStartValue" SG_ 1629 Obj_ArelLong 1000;
BA_ "GenSigStartValue" SG_ 1106 CollDetRegState_Point2Y 1023;
BA_ "GenSigStartValue" SG_ 1106 CollDetRegState_Point2X 2500;
BA_ "GenSigStartValue" SG_ 1106 CollDetRegState_Point1Y 1023;
BA_ "GenSigStartValue" SG_ 1106 CollDetRegState_Point1X 2500;
BA_ "GenSigStartValue" SG_ 596 FilterState_Min_Y 2047.5;
BA_ "GenSigStartValue" SG_ 596 FilterState_Min_X 2047.5;
BA_ "GenSigStartValue" SG_ 596 FilterState_Max_Y 2047.5;
BA_ "GenSigStartValue" SG_ 596 FilterState_Max_X 2047.5;
BA_ "GenSigStartValue" SG_ 596 FilterState_Min_RCS 2000;
BA_ "GenSigStartValue" SG_ 596 FilterState_Min_Azimuth 2000;
BA_ "GenSigStartValue" SG_ 596 FilterState_Max_RCS 2000;
BA_ "GenSigStartValue" SG_ 596 FilterState_Max_Azimuth 2000;
BA_ "GenSigStartValue" SG_ 594 FilterCfg_Min_Y 2047.5;
BA_ "GenSigStartValue" SG_ 594 FilterCfg_Min_X 2500;
BA_ "GenSigStartValue" SG_ 594 FilterCfg_Max_Y 2047.5;
BA_ "GenSigStartValue" SG_ 594 FilterCfg_Max_X 2500;
BA_ "GenSigStartValue" SG_ 594 FilterCfg_Max_RCS 2000;
BA_ "GenSigStartValue" SG_ 594 FilterCfg_Max_Azimuth 2000;
BA_ "GenSigStartValue" SG_ 594 FilterCfg_Min_RCS 2000;
BA_ "GenSigStartValue" SG_ 594 FilterCfg_Min_Azimuth 2000;
BA_ "GenSigCycleTime" SG_ 593 RadarState_MotionRxState 50;
BA_ "GenSigSendType" SG_ 593 RadarState_MotionRxState 0;
BA_ "GenSigStartValue" SG_ 1105 CollDetRegCfg_Point1X 2500;
BA_ "GenSigStartValue" SG_ 1105 CollDetRegCfg_Point1Y 1023;
BA_ "GenSigStartValue" SG_ 1105 CollDetRegCfg_Point2X 2500;
BA_ "GenSigStartValue" SG_ 1105 CollDetRegCfg_Point2Y 1023;
BA_ "GenSigStartValue" SG_ 1627 Obj_VrelLat 256;
BA_ "GenSigStartValue" SG_ 1627 Obj_DistLong 2500;
BA_ "GenSigStartValue" SG_ 1627 Obj_VrelLong 512;
BA_ "GenSigStartValue" SG_ 1627 Obj_DistLat 1023;
BA_ "GenSigStartValue" SG_ 1873 Cluster_VrelLat 256;
BA_ "GenSigStartValue" SG_ 1873 Cluster_DistLong 2500;
BA_ "GenSigStartValue" SG_ 1873 Cluster_VrelLong 512;
BA_ "GenSigStartValue" SG_ 1873 Cluster_DistLat 511.5;
BA_ "GenSigStartValue" SG_ 1645 Obj_ArelLat 250;
BA_ "GenSigStartValue" SG_ 1645 Obj_OrientationAngle 450;
BA_ "GenSigStartValue" SG_ 1645 Obj_ArelLong 1000;
BA_ "GenSigStartValue" SG_ 1122 CollDetRegState_Point2Y 1023;
BA_ "GenSigStartValue" SG_ 1122 CollDetRegState_Point2X 2500;
BA_ "GenSigStartValue" SG_ 1122 CollDetRegState_Point1Y 1023;
BA_ "GenSigStartValue" SG_ 1122 CollDetRegState_Point1X 2500;
BA_ "GenSigStartValue" SG_ 612 FilterState_Min_Y 2047.5;
BA_ "GenSigStartValue" SG_ 612 FilterState_Min_X 2047.5;
BA_ "GenSigStartValue" SG_ 612 FilterState_Max_Y 2047.5;
BA_ "GenSigStartValue" SG_ 612 FilterState_Max_X 2047.5;
BA_ "GenSigStartValue" SG_ 612 FilterState_Min_RCS 2000;
BA_ "GenSigStartValue" SG_ 612 FilterState_Min_Azimuth 2000;
BA_ "GenSigStartValue" SG_ 612 FilterState_Max_RCS 2000;
BA_ "GenSigStartValue" SG_ 612 FilterState_Max_Azimuth 2000;
BA_ "GenSigStartValue" SG_ 610 FilterCfg_Min_Y 2047.5;
BA_ "GenSigStartValue" SG_ 610 FilterCfg_Min_X 2500;
BA_ "GenSigStartValue" SG_ 610 FilterCfg_Max_Y 2047.5;
BA_ "GenSigStartValue" SG_ 610 FilterCfg_Max_X 2500;
BA_ "GenSigStartValue" SG_ 610 FilterCfg_Max_RCS 2000;
BA_ "GenSigStartValue" SG_ 610 FilterCfg_Max_Azimuth 2000;
BA_ "GenSigStartValue" SG_ 610 FilterCfg_Min_RCS 2000;
BA_ "GenSigStartValue" SG_ 610 FilterCfg_Min_Azimuth 2000;
BA_ "GenSigCycleTime" SG_ 609 RadarState_MotionRxState 50;
BA_ "GenSigSendType" SG_ 609 RadarState_MotionRxState 0;
BA_ "GenSigStartValue" SG_ 1121 CollDetRegCfg_Point1X 2500;
BA_ "GenSigStartValue" SG_ 1121 CollDetRegCfg_Point1Y 1023;
BA_ "GenSigStartValue" SG_ 1121 CollDetRegCfg_Point2X 2500;
BA_ "GenSigStartValue" SG_ 1121 CollDetRegCfg_Point2Y 1023;
BA_ "GenSigStartValue" SG_ 1643 Obj_VrelLat 256;
BA_ "GenSigStartValue" SG_ 1643 Obj_DistLong 2500;
BA_ "GenSigStartValue" SG_ 1643 Obj_VrelLong 512;
BA_ "GenSigStartValue" SG_ 1643 Obj_DistLat 1023;
BA_ "GenSigStartValue" SG_ 1889 Cluster_VrelLat 256;
BA_ "GenSigStartValue" SG_ 1889 Cluster_DistLong 2500;
BA_ "GenSigStartValue" SG_ 1889 Cluster_VrelLong 512;
BA_ "GenSigStartValue" SG_ 1889 Cluster_DistLat 511.5;
BA_ "GenSigStartValue" SG_ 1661 Obj_ArelLat 250;
BA_ "GenSigStartValue" SG_ 1661 Obj_OrientationAngle 450;
BA_ "GenSigStartValue" SG_ 1661 Obj_ArelLong 1000;
BA_ "GenSigStartValue" SG_ 1138 CollDetRegState_Point2Y 1023;
BA_ "GenSigStartValue" SG_ 1138 CollDetRegState_Point2X 2500;
BA_ "GenSigStartValue" SG_ 1138 CollDetRegState_Point1Y 1023;
BA_ "GenSigStartValue" SG_ 1138 CollDetRegState_Point1X 2500;
BA_ "GenSigStartValue" SG_ 628 FilterState_Min_Y 2047.5;
BA_ "GenSigStartValue" SG_ 628 FilterState_Min_X 2047.5;
BA_ "GenSigStartValue" SG_ 628 FilterState_Max_Y 2047.5;
BA_ "GenSigStartValue" SG_ 628 FilterState_Max_X 2047.5;
BA_ "GenSigStartValue" SG_ 628 FilterState_Min_RCS 2000;
BA_ "GenSigStartValue" SG_ 628 FilterState_Min_Azimuth 2000;
BA_ "GenSigStartValue" SG_ 628 FilterState_Max_RCS 2000;
BA_ "GenSigStartValue" SG_ 628 FilterState_Max_Azimuth 2000;
BA_ "GenSigStartValue" SG_ 626 FilterCfg_Min_Y 2047.5;
BA_ "GenSigStartValue" SG_ 626 FilterCfg_Min_X 2500;
BA_ "GenSigStartValue" SG_ 626 FilterCfg_Max_Y 2047.5;
BA_ "GenSigStartValue" SG_ 626 FilterCfg_Max_X 2500;
BA_ "GenSigStartValue" SG_ 626 FilterCfg_Max_RCS 2000;
BA_ "GenSigStartValue" SG_ 626 FilterCfg_Max_Azimuth 2000;
BA_ "GenSigStartValue" SG_ 626 FilterCfg_Min_RCS 2000;
BA_ "GenSigStartValue" SG_ 626 FilterCfg_Min_Azimuth 2000;
BA_ "GenSigCycleTime" SG_ 625 RadarState_MotionRxState 50;
BA_ "GenSigSendType" SG_ 625 RadarState_MotionRxState 0;
BA_ "GenSigStartValue" SG_ 1137 CollDetRegCfg_Point1X 2500;
BA_ "GenSigStartValue" SG_ 1137 CollDetRegCfg_Point1Y 1023;
BA_ "GenSigStartValue" SG_ 1137 CollDetRegCfg_Point2X 2500;
BA_ "GenSigStartValue" SG_ 1137 CollDetRegCfg_Point2Y 1023;
BA_ "GenSigStartValue" SG_ 1659 Obj_VrelLat 256;
BA_ "GenSigStartValue" SG_ 1659 Obj_DistLong 2500;
BA_ "GenSigStartValue" SG_ 1659 Obj_VrelLong 512;
BA_ "GenSigStartValue" SG_ 1659 Obj_DistLat 1023;
BA_ "GenSigStartValue" SG_ 1905 Cluster_VrelLat 256;
BA_ "GenSigStartValue" SG_ 1905 Cluster_DistLong 2500;
BA_ "GenSigStartValue" SG_ 1905 Cluster_VrelLong 512;
BA_ "GenSigStartValue" SG_ 1905 Cluster_DistLat 511.5;
VAL_ 1612 Obj_ProbOfExist 7 "<=100%" 6 "<99.9%" 5 "<99%" 4 "<90%" 3 "<75%" 2 "<50%" 1 "<25%" 0 "invalid" ;
VAL_ 1612 Obj_MeasState 5 "New from merge" 4 "Deleted for merge" 3 "Predicted" 2 "Measured" 1 "New" 0 "Deleted" ;
VAL_ 1612 Obj_ArelLong_rms 31 "Invalid" 30 "<10.000 m/s²" 29 "<7.762 m/s²" 28 "<6.025 m/s²" 27 "<4.676 m/s²" 26 "<3.630 m/s²" 25 "<2.817 m/s²" 24 "<2.187 m/s²" 23 "<1.697 m/s²" 22 "<1.317 m/s²" 21 "<1.023 m/s²" 20 "<0.794 m/s²" 19 "<0.616 m/s²" 18 "<0.478 m/s²" 17 "<0.371 m/s²" 16 "<0.288 m/s²" 15 "<0.224 m/s²" 14 "<0.174 m/s²" 13 "<0.135 m/s²" 12 "<0.105 m/s²" 11 "<0.081 m/s²" 10 "<0.063 m/s²" 9 "<0.049 m/s²" 8 "<0.038 m/s²" 7 "<0.029 m/s²" 6 "<0.023 m/s²" 5 "<0.018 m/s²" 4 "<0.014 m/s²" 3 "<0.011 m/s²" 2 "<0.008 m/s²" 1 "<0.006 m/s²" 0 "<0.005 m/s²" ;
VAL_ 1612 Obj_ArelLat_rms 31 "Invalid" 30 "<10.000 m/s²" 29 "<7.762 m/s²" 28 "<6.025 m/s²" 27 "<4.676 m/s²" 26 "<3.630 m/s²" 25 "<2.817 m/s²" 24 "<2.187 m/s²" 23 "<1.697 m/s²" 22 "<1.317 m/s²" 21 "<1.023 m/s²" 20 "<0.794 m/s²" 19 "<0.616 m/s²" 18 "<0.478 m/s²" 17 "<0.371 m/s²" 16 "<0.288 m/s²" 15 "<0.224 m/s²" 14 "<0.174 m/s²" 13 "<0.135 m/s²" 12 "<0.105 m/s²" 11 "<0.081 m/s²" 10 "<0.063 m/s²" 9 "<0.049 m/s²" 8 "<0.038 m/s²" 7 "<0.029 m/s²" 6 "<0.023 m/s²" 5 "<0.018 m/s²" 4 "<0.014 m/s²" 3 "<0.011 m/s²" 2 "<0.008 m/s²" 1 "<0.006 m/s²" 0 "<0.005 m/s²" ;
VAL_ 1612 Obj_VrelLong_rms 31 "Invalid" 30 "<10.000 m/s" 29 "<7.762 m/s" 28 "<6.025 m/s" 27 "<4.676 m/s" 26 "<3.630 m/s" 25 "<2.817 m/s" 24 "<2.187 m/s" 23 "<1.697 m/s" 22 "<1.317 m/s" 21 "<1.023 m/s" 20 "<0.794 m/s" 19 "<0.616 m/s" 18 "<0.478 m/s" 17 "<0.371 m/s" 16 "<0.288 m/s" 15 "<0.224 m/s" 14 "<0.174 m/s" 13 "<0.135 m/s" 12 "<0.105 m/s" 11 "<0.081 m/s" 10 "<0.063 m/s" 9 "<0.049 m/s" 8 "<0.038 m/s" 7 "<0.029 m/s" 6 "<0.023 m/s" 5 "<0.018 m/s" 4 "<0.014 m/s" 3 "<0.011 m/s" 2 "<0.008 m/s" 1 "<0.006 m/s" 0 "<0.005 m/s" ;
VAL_ 1612 Obj_VrelLat_rms 31 "Invalid" 30 "<10.000 m/s" 29 "<7.762 m/s" 28 "<6.025 m/s" 27 "<4.676 m/s" 26 "<3.630 m/s" 25 "<2.817 m/s" 24 "<2.187 m/s" 23 "<1.697 m/s" 22 "<1.317 m/s" 21 "<1.023 m/s" 20 "<0.794 m/s" 19 "<0.616 m/s" 18 "<0.478 m/s" 17 "<0.371 m/s" 16 "<0.288 m/s" 15 "<0.224 m/s" 14 "<0.174 m/s" 13 "<0.135 m/s" 12 "<0.105 m/s" 11 "<0.081 m/s" 10 "<0.063 m/s" 9 "<0.049 m/s" 8 "<0.038 m/s" 7 "<0.029 m/s" 6 "<0.023 m/s" 5 "<0.018 m/s" 4 "<0.014 m/s" 3 "<0.011 m/s" 2 "<0.008 m/s" 1 "<0.006 m/s" 0 "<0.005 m/s" ;
VAL_ 1612 Obj_Orientation_rms 31 "Invalid" 30 "<180.000 deg" 29 "<126.881 deg" 28 "<89.437 deg" 27 "<63.044 deg" 26 "<44.439 deg" 25 "<31.325 deg" 24 "<22.081 deg" 23 "<15.565 deg" 22 "<10.971 deg" 21 "<7.734 deg" 20 "<5.451 deg" 19 "<3.843 deg" 18 "<2.709 deg" 17 "<1.909 deg" 16 "<1.346 deg" 15 "<0.949 deg" 14 "<0.669 deg" 13 "<0.471 deg" 12 "<0.332 deg" 11 "<0.234 deg" 10 "<0.165 deg" 9 "<0.116 deg" 8 "<0.082 deg" 7 "<0.058 deg" 6 "<0.041 deg" 5 "<0.029 deg" 4 "<0.020 deg" 3 "<0.014 deg" 2 "<0.010 deg" 1 "<0.007 deg" 0 "<0.005 deg" ;
VAL_ 1612 Obj_DistLong_rms 31 "Invalid" 30 "<10.000 m" 29 "<7.762 m" 28 "<6.025 m" 27 "<4.676 m" 26 "<3.630 m" 25 "<2.817 m" 24 "<2.187 m" 23 "<1.697 m" 22 "<1.317 m" 21 "<1.023 m" 20 "<0.794 m" 19 "<0.616 m" 18 "<0.478 m" 17 "<0.371 m" 16 "<0.288 m" 15 "<0.224 m" 14 "<0.174 m" 13 "<0.135 m" 12 "<0.105 m" 11 "<0.081 m" 10 "<0.063 m" 9 "<0.049 m" 8 "<0.038 m" 7 "<0.029 m" 6 "<0.023 m" 5 "<0.018 m" 4 "<0.014 m" 3 "<0.011 m" 2 "<0.008 m" 1 "<0.006 m" 0 "<0.005 m" ;
VAL_ 1612 Obj_DistLat_rms 31 "Invalid" 30 "<10.000 m" 29 "<7.762 m" 28 "<6.025 m" 27 "<4.676 m" 26 "<3.630 m" 25 "<2.817 m" 24 "<2.187 m" 23 "<1.697 m" 22 "<1.317 m" 21 "<1.023 m" 20 "<0.794 m" 19 "<0.616 m" 18 "<0.478 m" 17 "<0.371 m" 16 "<0.288 m" 15 "<0.224 m" 14 "<0.174 m" 13 "<0.135 m" 12 "<0.105 m" 11 "<0.081 m" 10 "<0.063 m" 9 "<0.049 m" 8 "<0.038 m" 7 "<0.029 m" 6 "<0.023 m" 5 "<0.018 m" 4 "<0.014 m" 3 "<0.011 m" 2 "<0.008 m" 1 "<0.006 m" 0 "<0.005 m" ;
VAL_ 1613 Obj_Class 7 "Description for the value '0x7'" 6 "Wide" 5 "Bicycle" 4 "Motorcycle" 3 "Pedestrian" 2 "Truck" 1 "Car" 0 "Point" ;
VAL_ 1090 CollDetRegState_WarningLevel 3 "Warning deactivated" 2 "Preliminary warning" 1 "Object warning" 0 "No warning" ;
VAL_ 580 FilterState_Type 1 "Object filter" 0 "Cluster filter" ;
VAL_ 580 FilterState_Min_ProbExists 7 "100%" 6 ">=99.9%" 5 ">=99%" 4 ">=90%" 3 ">=75%" 2 ">=50%" 1 ">=25%" 0 "invalid" ;
VAL_ 580 FilterState_Max_ProbExists 7 "<=100%" 6 "<99.9%" 5 "<99%" 4 "<90%" 3 "<75%" 2 "<50%" 1 "<25%" 0 "invalid" ;
VAL_ 580 FilterState_Index 15 "Class" 14 "Longitud. velocity for departing" 13 "Lateral velocity for right-left" 12 "Longitud. velocity for oncoming" 11 "Lateral velocity for left-right" 10 "Longitudinal distance" 9 "Lateral distance" 8 "Probability of existence" 7 "Size" 6 "Lifetime" 5 "RCS" 4 "Radial velocity for departing" 3 "Radial velocity for oncoming" 2 "Azimuth" 1 "Radial distance" 0 "Number of objects" ;
VAL_ 580 FilterState_Active 1 "active" 0 "inactive" ;
VAL_ 578 FilterCfg_Valid 1 "valid" 0 "invalid" ;
VAL_ 578 FilterCfg_Active 1 "active" 0 "inactive" ;
VAL_ 578 FilterCfg_Max_ProbExists 7 "<=100%" 6 "<99.9%" 5 "<99%" 4 "<90%" 3 "<75%" 2 "<50%" 1 "<25%" 0 "invalid" ;
VAL_ 578 FilterCfg_Min_ProbExists 7 "100%" 6 ">=99.9%" 5 ">=99%" 4 ">=90%" 3 ">=75%" 2 ">=50%" 1 ">=25%" 0 "invalid" ;
VAL_ 578 FilterCfg_Index 15 "Class" 14 "Longitud. velocity for departing" 13 "Lateral velocity for right-left" 12 "Longitud. velocity for oncoming" 11 "Lateral velocity for left-right" 10 "Longitudinal distance" 9 "Lateral distance" 8 "Probability of existence" 7 "Size" 6 "Lifetime" 5 "RCS" 4 "Radial velocity for departing" 3 "Radial velocity for oncoming" 2 "Azimuth" 1 "Radial distance" 0 "Number of objects" ;
VAL_ 578 FilterCfg_Type 1 "Object filter" 0 "Cluster filter" ;
VAL_ 576 RadarCfg_RCS_Threshold_Valid 1 "Valid" 0 "Invalid" ;
VAL_ 576 RadarCfg_RCS_Threshold 7 "Reserved" 6 "Reserved" 5 "Reserved" 4 "Reserved" 3 "Reserved" 2 "Reserved" 1 "High Sensitivity" 0 "Standard" ;
VAL_ 576 RadarCfg_StoreInNVM_valid 1 "Valid" 0 "Invalid" ;
VAL_ 576 RadarCfg_SortIndex_valid 1 "Valid" 0 "Invalid" ;
VAL_ 576 RadarCfg_SortIndex 2 "Sorted by RCS" 1 "Sorted by range" 0 "No sorting" ;
VAL_ 576 RadarCfg_StoreInNVM 1 "Active" 0 "Inactive" ;
VAL_ 576 RadarCfg_SendExtInfo_valid 1 "Valid" 0 "Invalid" ;
VAL_ 576 RadarCfg_SendExtInfo 1 "Active" 0 "Inactive" ;
VAL_ 576 RadarCfg_CtrlRelay_valid 1 "Valid" 0 "Invalid" ;
VAL_ 576 RadarCfg_CtrlRelay 1 "Active" 0 "Inactive" ;
VAL_ 576 RadarCfg_SendQuality_valid 1 "Valid" 0 "Invalid" ;
VAL_ 576 RadarCfg_SendQuality 1 "Active" 0 "Inactive" ;
VAL_ 576 RadarCfg_MaxDistance_valid 1 "Valid" 0 "Invalid" ;
VAL_ 576 RadarCfg_RadarPower_valid 1 "Valid" 0 "Invalid" ;
VAL_ 576 RadarCfg_OutputType_valid 1 "Valid" 0 "Invalid" ;
VAL_ 576 RadarCfg_SensorID_valid 1 "Valid" 0 "Invalid" ;
VAL_ 576 RadarCfg_RadarPower 7 "Reserved" 6 "Reserved" 5 "Reserved" 4 "Reserved" 3 "-9 dB Tx gain" 2 "-6 dB Tx gain" 1 "-3 dB Tx gain" 0 "Standard" ;
VAL_ 576 RadarCfg_OutputType 3 "reserved 2" 2 "SendClusters" 1 "SendObjects" 0 "None" ;
VAL_ 577 RadarState_RCS_Threshold 7 "Reserved" 6 "Reserved" 5 "Reserved" 4 "Reserved" 3 "Reserved" 2 "Reserved" 1 "High Sensitivity" 0 "Standard" ;
VAL_ 577 RadarState_CtrlRelayCfg 1 "Active" 0 "Inactive" ;
VAL_ 577 RadarState_SendQualityCfg 1 "Active" 0 "Inactive" ;
VAL_ 577 RadarState_SendExtInfoCfg 1 "Active" 0 "Inactive" ;
VAL_ 577 RadarState_MotionRxState 3 "Speed and yaw rate missing" 2 "Yaw rate missing" 1 "Speed missing" 0 "Input ok" ;
VAL_ 577 RadarState_OutputTypeCfg 3 "reserved 2" 2 "SendClusters" 1 "SendObjects" 0 "None" ;
VAL_ 577 RadarState_RadarPowerCfg 7 "Reserved" 6 "Reserved" 5 "Reserved" 4 "Reserved" 3 "-9 dB Tx gain" 2 "-6 dB Tx gain" 1 "-3 dB Tx gain" 0 "Standard" ;
VAL_ 577 RadarState_NVMReadStatus 1 "successful" 0 "pending" ;
VAL_ 577 RadarState_NVMwriteStatus 1 "successful" 0 "failed" ;
VAL_ 832 RadarDevice_SpeedDirection 3 "reserved" 2 "reverse" 1 "forward" 0 "standstill" ;
VAL_ 1088 CollDetCfg_ClearRegions 1 "Clear all defined regions" 0 "Idle" ;
VAL_ 1088 CollDetCfg_WarningReset 1 "Warn reset" 0 "Idle" ;
VAL_ 1088 CollDetCfg_Activate 1 "Active" 0 "Inactive" ;
VAL_ 1088 CollDetCfg_MinTime_valid 1 "Valid" 0 "Invalid" ;
VAL_ 1089 CollDetRegCfg_Activate 1 "Active" 0 "Inactive" ;
VAL_ 1089 CollDetRegCfg_Coordinates_valid 1 "Valid" 0 "Invalid" ;
VAL_ 1096 CollDetState_Active 1 "Active" 0 "Inactive" ;
VAL_ 1611 Obj_DynProp 7 "Stopped" 6 "Crossing moving" 5 "Crossing stationary" 4 "Unknown" 3 "Stationary candidate" 2 "Oncoming" 1 "Stationary" 0 "Moving" ;
VAL_ 1857 Cluster_DynProp 7 "Stopped" 6 "Crossing moving" 5 "Crossing stationary" 4 "Unknown" 3 "Stationary candidate" 2 "Oncoming" 1 "Stationary" 0 "Moving" ;
VAL_ 1858 Cluster_VrelLat_rms 31 "Invalid" 30 "<10.000 m/s" 29 "<7.762 m/s" 28 "<6.025 m/s" 27 "<4.676 m/s" 26 "<3.630 m/s" 25 "<2.817 m/s" 24 "<2.187 m/s" 23 "<1.697 m/s" 22 "<1.317 m/s" 21 "<1.023 m/s" 20 "<0.794 m/s" 19 "<0.616 m/s" 18 "<0.478 m/s" 17 "<0.371 m/s" 16 "<0.288 m/s" 15 "<0.224 m/s" 14 "<0.174 m/s" 13 "<0.135 m/s" 12 "<0.105 m/s" 11 "<0.081 m/s" 10 "<0.063 m/s" 9 "<0.049 m/s" 8 "<0.038 m/s" 7 "<0.029 m/s" 6 "<0.023 m/s" 5 "<0.018 m/s" 4 "<0.014 m/s" 3 "<0.011 m/s" 2 "<0.008 m/s" 1 "<0.006 m/s" 0 "<0.005 m/s" ;
VAL_ 1858 Cluster_InvalidState 17 "Valid suspicious angle" 16 "Valid multi-target" 15 "Valid near above 95 m" 14 "Invalid harmonics " 13 "reserved" 12 "Valid artefact " 11 "Valid but no local maximum" 10 "Valid 50 deg artefact" 9 "Valid child" 8 "Valid with elevation" 7 "Invalid outside field of view" 6 "Invalid mirror" 5 "reserved" 4 "Valid with low RCS" 3 "Invalid far not confirmed" 2 "Invalid nearfield" 1 "Invalid with too low RCS" 0 "Valid" ;
VAL_ 1858 Cluster_DistLat_rms 31 "Invalid" 30 "<10.000 m" 29 "<7.762 m" 28 "<6.025 m" 27 "<4.676 m" 26 "<3.630 m" 25 "<2.817 m" 24 "<2.187 m" 23 "<1.697 m" 22 "<1.317 m" 21 "<1.023 m" 20 "<0.794 m" 19 "<0.616 m" 18 "<0.478 m" 17 "<0.371 m" 16 "<0.288 m" 15 "<0.224 m" 14 "<0.174 m" 13 "<0.135 m" 12 "<0.105 m" 11 "<0.081 m" 10 "<0.063 m" 9 "<0.049 m" 8 "<0.038 m" 7 "<0.029 m" 6 "<0.023 m" 5 "<0.018 m" 4 "<0.014 m" 3 "<0.011 m" 2 "<0.008 m" 1 "<0.006 m" 0 "<0.005 m" ;
VAL_ 1858 Cluster_DistLong_rms 31 "Invalid" 30 "<10.000 m" 29 "<7.762 m" 28 "<6.025 m" 27 "<4.676 m" 26 "<3.630 m" 25 "<2.817 m" 24 "<2.187 m" 23 "<1.697 m" 22 "<1.317 m" 21 "<1.023 m" 20 "<0.794 m" 19 "<0.616 m" 18 "<0.478 m" 17 "<0.371 m" 16 "<0.288 m" 15 "<0.224 m" 14 "<0.174 m" 13 "<0.135 m" 12 "<0.105 m" 11 "<0.081 m" 10 "<0.063 m" 9 "<0.049 m" 8 "<0.038 m" 7 "<0.029 m" 6 "<0.023 m" 5 "<0.018 m" 4 "<0.014 m" 3 "<0.011 m" 2 "<0.008 m" 1 "<0.006 m" 0 "<0.005 m" ;
VAL_ 1858 Cluster_VrelLong_rms 31 "Invalid" 30 "<10.000 m/s" 29 "<7.762 m/s" 28 "<6.025 m/s" 27 "<4.676 m/s" 26 "<3.630 m/s" 25 "<2.817 m/s" 24 "<2.187 m/s" 23 "<1.697 m/s" 22 "<1.317 m/s" 21 "<1.023 m/s" 20 "<0.794 m/s" 19 "<0.616 m/s" 18 "<0.478 m/s" 17 "<0.371 m/s" 16 "<0.288 m/s" 15 "<0.224 m/s" 14 "<0.174 m/s" 13 "<0.135 m/s" 12 "<0.105 m/s" 11 "<0.081 m/s" 10 "<0.063 m/s" 9 "<0.049 m/s" 8 "<0.038 m/s" 7 "<0.029 m/s" 6 "<0.023 m/s" 5 "<0.018 m/s" 4 "<0.014 m/s" 3 "<0.011 m/s" 2 "<0.008 m/s" 1 "<0.006 m/s" 0 "<0.005 m/s" ;
VAL_ 1858 Cluster_PdH0 7 "<=100%" 6 "<99.9%" 5 "<99%" 4 "<90%" 3 "<75%" 2 "<50%" 1 "<25%" 0 "invalid" ;
VAL_ 1858 Cluster_AmbigState 4 "Stationary candidate" 3 "Unambiguous" 2 "Staggered ramp" 1 "Ambiguous" 0 "Invalid" ;
VAL_ 1628 Obj_ProbOfExist 7 "<=100%" 6 "<99.9%" 5 "<99%" 4 "<90%" 3 "<75%" 2 "<50%" 1 "<25%" 0 "invalid" ;
VAL_ 1628 Obj_MeasState 5 "New from merge" 4 "Deleted for merge" 3 "Predicted" 2 "Measured" 1 "New" 0 "Deleted" ;
VAL_ 1628 Obj_ArelLong_rms 31 "Invalid" 30 "<10.000 m/s²" 29 "<7.762 m/s²" 28 "<6.025 m/s²" 27 "<4.676 m/s²" 26 "<3.630 m/s²" 25 "<2.817 m/s²" 24 "<2.187 m/s²" 23 "<1.697 m/s²" 22 "<1.317 m/s²" 21 "<1.023 m/s²" 20 "<0.794 m/s²" 19 "<0.616 m/s²" 18 "<0.478 m/s²" 17 "<0.371 m/s²" 16 "<0.288 m/s²" 15 "<0.224 m/s²" 14 "<0.174 m/s²" 13 "<0.135 m/s²" 12 "<0.105 m/s²" 11 "<0.081 m/s²" 10 "<0.063 m/s²" 9 "<0.049 m/s²" 8 "<0.038 m/s²" 7 "<0.029 m/s²" 6 "<0.023 m/s²" 5 "<0.018 m/s²" 4 "<0.014 m/s²" 3 "<0.011 m/s²" 2 "<0.008 m/s²" 1 "<0.006 m/s²" 0 "<0.005 m/s²" ;
VAL_ 1628 Obj_ArelLat_rms 31 "Invalid" 30 "<10.000 m/s²" 29 "<7.762 m/s²" 28 "<6.025 m/s²" 27 "<4.676 m/s²" 26 "<3.630 m/s²" 25 "<2.817 m/s²" 24 "<2.187 m/s²" 23 "<1.697 m/s²" 22 "<1.317 m/s²" 21 "<1.023 m/s²" 20 "<0.794 m/s²" 19 "<0.616 m/s²" 18 "<0.478 m/s²" 17 "<0.371 m/s²" 16 "<0.288 m/s²" 15 "<0.224 m/s²" 14 "<0.174 m/s²" 13 "<0.135 m/s²" 12 "<0.105 m/s²" 11 "<0.081 m/s²" 10 "<0.063 m/s²" 9 "<0.049 m/s²" 8 "<0.038 m/s²" 7 "<0.029 m/s²" 6 "<0.023 m/s²" 5 "<0.018 m/s²" 4 "<0.014 m/s²" 3 "<0.011 m/s²" 2 "<0.008 m/s²" 1 "<0.006 m/s²" 0 "<0.005 m/s²" ;
VAL_ 1628 Obj_VrelLong_rms 31 "Invalid" 30 "<10.000 m/s" 29 "<7.762 m/s" 28 "<6.025 m/s" 27 "<4.676 m/s" 26 "<3.630 m/s" 25 "<2.817 m/s" 24 "<2.187 m/s" 23 "<1.697 m/s" 22 "<1.317 m/s" 21 "<1.023 m/s" 20 "<0.794 m/s" 19 "<0.616 m/s" 18 "<0.478 m/s" 17 "<0.371 m/s" 16 "<0.288 m/s" 15 "<0.224 m/s" 14 "<0.174 m/s" 13 "<0.135 m/s" 12 "<0.105 m/s" 11 "<0.081 m/s" 10 "<0.063 m/s" 9 "<0.049 m/s" 8 "<0.038 m/s" 7 "<0.029 m/s" 6 "<0.023 m/s" 5 "<0.018 m/s" 4 "<0.014 m/s" 3 "<0.011 m/s" 2 "<0.008 m/s" 1 "<0.006 m/s" 0 "<0.005 m/s" ;
VAL_ 1628 Obj_VrelLat_rms 31 "Invalid" 30 "<10.000 m/s" 29 "<7.762 m/s" 28 "<6.025 m/s" 27 "<4.676 m/s" 26 "<3.630 m/s" 25 "<2.817 m/s" 24 "<2.187 m/s" 23 "<1.697 m/s" 22 "<1.317 m/s" 21 "<1.023 m/s" 20 "<0.794 m/s" 19 "<0.616 m/s" 18 "<0.478 m/s" 17 "<0.371 m/s" 16 "<0.288 m/s" 15 "<0.224 m/s" 14 "<0.174 m/s" 13 "<0.135 m/s" 12 "<0.105 m/s" 11 "<0.081 m/s" 10 "<0.063 m/s" 9 "<0.049 m/s" 8 "<0.038 m/s" 7 "<0.029 m/s" 6 "<0.023 m/s" 5 "<0.018 m/s" 4 "<0.014 m/s" 3 "<0.011 m/s" 2 "<0.008 m/s" 1 "<0.006 m/s" 0 "<0.005 m/s" ;
VAL_ 1628 Obj_Orientation_rms 31 "Invalid" 30 "<180.000 deg" 29 "<126.881 deg" 28 "<89.437 deg" 27 "<63.044 deg" 26 "<44.439 deg" 25 "<31.325 deg" 24 "<22.081 deg" 23 "<15.565 deg" 22 "<10.971 deg" 21 "<7.734 deg" 20 "<5.451 deg" 19 "<3.843 deg" 18 "<2.709 deg" 17 "<1.909 deg" 16 "<1.346 deg" 15 "<0.949 deg" 14 "<0.669 deg" 13 "<0.471 deg" 12 "<0.332 deg" 11 "<0.234 deg" 10 "<0.165 deg" 9 "<0.116 deg" 8 "<0.082 deg" 7 "<0.058 deg" 6 "<0.041 deg" 5 "<0.029 deg" 4 "<0.020 deg" 3 "<0.014 deg" 2 "<0.010 deg" 1 "<0.007 deg" 0 "<0.005 deg" ;
VAL_ 1628 Obj_DistLong_rms 31 "Invalid" 30 "<10.000 m" 29 "<7.762 m" 28 "<6.025 m" 27 "<4.676 m" 26 "<3.630 m" 25 "<2.817 m" 24 "<2.187 m" 23 "<1.697 m" 22 "<1.317 m" 21 "<1.023 m" 20 "<0.794 m" 19 "<0.616 m" 18 "<0.478 m" 17 "<0.371 m" 16 "<0.288 m" 15 "<0.224 m" 14 "<0.174 m" 13 "<0.135 m" 12 "<0.105 m" 11 "<0.081 m" 10 "<0.063 m" 9 "<0.049 m" 8 "<0.038 m" 7 "<0.029 m" 6 "<0.023 m" 5 "<0.018 m" 4 "<0.014 m" 3 "<0.011 m" 2 "<0.008 m" 1 "<0.006 m" 0 "<0.005 m" ;
VAL_ 1628 Obj_DistLat_rms 31 "Invalid" 30 "<10.000 m" 29 "<7.762 m" 28 "<6.025 m" 27 "<4.676 m" 26 "<3.630 m" 25 "<2.817 m" 24 "<2.187 m" 23 "<1.697 m" 22 "<1.317 m" 21 "<1.023 m" 20 "<0.794 m" 19 "<0.616 m" 18 "<0.478 m" 17 "<0.371 m" 16 "<0.288 m" 15 "<0.224 m" 14 "<0.174 m" 13 "<0.135 m" 12 "<0.105 m" 11 "<0.081 m" 10 "<0.063 m" 9 "<0.049 m" 8 "<0.038 m" 7 "<0.029 m" 6 "<0.023 m" 5 "<0.018 m" 4 "<0.014 m" 3 "<0.011 m" 2 "<0.008 m" 1 "<0.006 m" 0 "<0.005 m" ;
VAL_ 1629 Obj_Class 7 "Description for the value '0x7'" 6 "Wide" 5 "Bicycle" 4 "Motorcycle" 3 "Pedestrian" 2 "Truck" 1 "Car" 0 "Point" ;
VAL_ 1106 CollDetRegState_WarningLevel 3 "Warning deactivated" 2 "Preliminary warning" 1 "Object warning" 0 "No warning" ;
VAL_ 596 FilterState_Type 1 "Object filter" 0 "Cluster filter" ;
VAL_ 596 FilterState_Min_ProbExists 7 "100%" 6 ">=99.9%" 5 ">=99%" 4 ">=90%" 3 ">=75%" 2 ">=50%" 1 ">=25%" 0 "invalid" ;
VAL_ 596 FilterState_Max_ProbExists 7 "<=100%" 6 "<99.9%" 5 "<99%" 4 "<90%" 3 "<75%" 2 "<50%" 1 "<25%" 0 "invalid" ;
VAL_ 596 FilterState_Index 15 "Class" 14 "Longitud. velocity for departing" 13 "Lateral velocity for right-left" 12 "Longitud. velocity for oncoming" 11 "Lateral velocity for left-right" 10 "Longitudinal distance" 9 "Lateral distance" 8 "Probability of existence" 7 "Size" 6 "Lifetime" 5 "RCS" 4 "Radial velocity for departing" 3 "Radial velocity for oncoming" 2 "Azimuth" 1 "Radial distance" 0 "Number of objects" ;
VAL_ 596 FilterState_Active 1 "active" 0 "inactive" ;
VAL_ 594 FilterCfg_Valid 1 "valid" 0 "invalid" ;
VAL_ 594 FilterCfg_Active 1 "active" 0 "inactive" ;
VAL_ 594 FilterCfg_Max_ProbExists 7 "<=100%" 6 "<99.9%" 5 "<99%" 4 "<90%" 3 "<75%" 2 "<50%" 1 "<25%" 0 "invalid" ;
VAL_ 594 FilterCfg_Min_ProbExists 7 "100%" 6 ">=99.9%" 5 ">=99%" 4 ">=90%" 3 ">=75%" 2 ">=50%" 1 ">=25%" 0 "invalid" ;
VAL_ 594 FilterCfg_Index 15 "Class" 14 "Longitud. velocity for departing" 13 "Lateral velocity for right-left" 12 "Longitud. velocity for oncoming" 11 "Lateral velocity for left-right" 10 "Longitudinal distance" 9 "Lateral distance" 8 "Probability of existence" 7 "Size" 6 "Lifetime" 5 "RCS" 4 "Radial velocity for departing" 3 "Radial velocity for oncoming" 2 "Azimuth" 1 "Radial distance" 0 "Number of objects" ;
VAL_ 594 FilterCfg_Type 1 "Object filter" 0 "Cluster filter" ;
VAL_ 592 RadarCfg_RCS_Threshold_Valid 1 "Valid" 0 "Invalid" ;
VAL_ 592 RadarCfg_RCS_Threshold 7 "Reserved" 6 "Reserved" 5 "Reserved" 4 "Reserved" 3 "Reserved" 2 "Reserved" 1 "High Sensitivity" 0 "Standard" ;
VAL_ 592 RadarCfg_StoreInNVM_valid 1 "Valid" 0 "Invalid" ;
VAL_ 592 RadarCfg_SortIndex_valid 1 "Valid" 0 "Invalid" ;
VAL_ 592 RadarCfg_SortIndex 2 "Sorted by RCS" 1 "Sorted by range" 0 "No sorting" ;
VAL_ 592 RadarCfg_StoreInNVM 1 "Active" 0 "Inactive" ;
VAL_ 592 RadarCfg_SendExtInfo_valid 1 "Valid" 0 "Invalid" ;
VAL_ 592 RadarCfg_SendExtInfo 1 "Active" 0 "Inactive" ;
VAL_ 592 RadarCfg_CtrlRelay_valid 1 "Valid" 0 "Invalid" ;
VAL_ 592 RadarCfg_CtrlRelay 1 "Active" 0 "Inactive" ;
VAL_ 592 RadarCfg_SendQuality_valid 1 "Valid" 0 "Invalid" ;
VAL_ 592 RadarCfg_SendQuality 1 "Active" 0 "Inactive" ;
VAL_ 592 RadarCfg_MaxDistance_valid 1 "Valid" 0 "Invalid" ;
VAL_ 592 RadarCfg_RadarPower_valid 1 "Valid" 0 "Invalid" ;
VAL_ 592 RadarCfg_OutputType_valid 1 "Valid" 0 "Invalid" ;
VAL_ 592 RadarCfg_SensorID_valid 1 "Valid" 0 "Invalid" ;
VAL_ 592 RadarCfg_RadarPower 7 "Reserved" 6 "Reserved" 5 "Reserved" 4 "Reserved" 3 "-9 dB Tx gain" 2 "-6 dB Tx gain" 1 "-3 dB Tx gain" 0 "Standard" ;
VAL_ 592 RadarCfg_OutputType 3 "reserved 2" 2 "SendClusters" 1 "SendObjects" 0 "None" ;
VAL_ 593 RadarState_RCS_Threshold 7 "Reserved" 6 "Reserved" 5 "Reserved" 4 "Reserved" 3 "Reserved" 2 "Reserved" 1 "High Sensitivity" 0 "Standard" ;
VAL_ 593 RadarState_CtrlRelayCfg 1 "Active" 0 "Inactive" ;
VAL_ 593 RadarState_SendQualityCfg 1 "Active" 0 "Inactive" ;
VAL_ 593 RadarState_SendExtInfoCfg 1 "Active" 0 "Inactive" ;
VAL_ 593 RadarState_MotionRxState 3 "Speed and yaw rate missing" 2 "Yaw rate missing" 1 "Speed missing" 0 "Input ok" ;
VAL_ 593 RadarState_OutputTypeCfg 3 "reserved 2" 2 "SendClusters" 1 "SendObjects" 0 "None" ;
VAL_ 593 RadarState_RadarPowerCfg 7 "Reserved" 6 "Reserved" 5 "Reserved" 4 "Reserved" 3 "-9 dB Tx gain" 2 "-6 dB Tx gain" 1 "-3 dB Tx gain" 0 "Standard" ;
VAL_ 593 RadarState_NVMReadStatus 1 "successful" 0 "pending" ;
VAL_ 593 RadarState_NVMwriteStatus 1 "successful" 0 "failed" ;
VAL_ 848 RadarDevice_SpeedDirection 3 "reserved" 2 "reverse" 1 "forward" 0 "standstill" ;
VAL_ 1104 CollDetCfg_ClearRegions 1 "Clear all defined regions" 0 "Idle" ;
VAL_ 1104 CollDetCfg_WarningReset 1 "Warn reset" 0 "Idle" ;
VAL_ 1104 CollDetCfg_Activate 1 "Active" 0 "Inactive" ;
VAL_ 1104 CollDetCfg_MinTime_valid 1 "Valid" 0 "Invalid" ;
VAL_ 1105 CollDetRegCfg_Activate 1 "Active" 0 "Inactive" ;
VAL_ 1105 CollDetRegCfg_Coordinates_valid 1 "Valid" 0 "Invalid" ;
VAL_ 1112 CollDetState_Active 1 "Active" 0 "Inactive" ;
VAL_ 1627 Obj_DynProp 7 "Stopped" 6 "Crossing moving" 5 "Crossing stationary" 4 "Unknown" 3 "Stationary candidate" 2 "Oncoming" 1 "Stationary" 0 "Moving" ;
VAL_ 1873 Cluster_DynProp 7 "Stopped" 6 "Crossing moving" 5 "Crossing stationary" 4 "Unknown" 3 "Stationary candidate" 2 "Oncoming" 1 "Stationary" 0 "Moving" ;
VAL_ 1874 Cluster_VrelLat_rms 31 "Invalid" 30 "<10.000 m/s" 29 "<7.762 m/s" 28 "<6.025 m/s" 27 "<4.676 m/s" 26 "<3.630 m/s" 25 "<2.817 m/s" 24 "<2.187 m/s" 23 "<1.697 m/s" 22 "<1.317 m/s" 21 "<1.023 m/s" 20 "<0.794 m/s" 19 "<0.616 m/s" 18 "<0.478 m/s" 17 "<0.371 m/s" 16 "<0.288 m/s" 15 "<0.224 m/s" 14 "<0.174 m/s" 13 "<0.135 m/s" 12 "<0.105 m/s" 11 "<0.081 m/s" 10 "<0.063 m/s" 9 "<0.049 m/s" 8 "<0.038 m/s" 7 "<0.029 m/s" 6 "<0.023 m/s" 5 "<0.018 m/s" 4 "<0.014 m/s" 3 "<0.011 m/s" 2 "<0.008 m/s" 1 "<0.006 m/s" 0 "<0.005 m/s" ;
VAL_ 1874 Cluster_InvalidState 17 "Valid suspicious angle" 16 "Valid multi-target" 15 "Valid near above 95 m" 14 "Invalid harmonics " 13 "reserved" 12 "Valid artefact " 11 "Valid but no local maximum" 10 "Valid 50 deg artefact" 9 "Valid child" 8 "Valid with elevation" 7 "Invalid outside field of view" 6 "Invalid mirror" 5 "reserved" 4 "Valid with low RCS" 3 "Invalid far not confirmed" 2 "Invalid nearfield" 1 "Invalid with too low RCS" 0 "Valid" ;
VAL_ 1874 Cluster_DistLat_rms 31 "Invalid" 30 "<10.000 m" 29 "<7.762 m" 28 "<6.025 m" 27 "<4.676 m" 26 "<3.630 m" 25 "<2.817 m" 24 "<2.187 m" 23 "<1.697 m" 22 "<1.317 m" 21 "<1.023 m" 20 "<0.794 m" 19 "<0.616 m" 18 "<0.478 m" 17 "<0.371 m" 16 "<0.288 m" 15 "<0.224 m" 14 "<0.174 m" 13 "<0.135 m" 12 "<0.105 m" 11 "<0.081 m" 10 "<0.063 m" 9 "<0.049 m" 8 "<0.038 m" 7 "<0.029 m" 6 "<0.023 m" 5 "<0.018 m" 4 "<0.014 m" 3 "<0.011 m" 2 "<0.008 m" 1 "<0.006 m" 0 "<0.005 m" ;
VAL_ 1874 Cluster_DistLong_rms 31 "Invalid" 30 "<10.000 m" 29 "<7.762 m" 28 "<6.025 m" 27 "<4.676 m" 26 "<3.630 m" 25 "<2.817 m" 24 "<2.187 m" 23 "<1.697 m" 22 "<1.317 m" 21 "<1.023 m" 20 "<0.794 m" 19 "<0.616 m" 18 "<0.478 m" 17 "<0.371 m" 16 "<0.288 m" 15 "<0.224 m" 14 "<0.174 m" 13 "<0.135 m" 12 "<0.105 m" 11 "<0.081 m" 10 "<0.063 m" 9 "<0.049 m" 8 "<0.038 m" 7 "<0.029 m" 6 "<0.023 m" 5 "<0.018 m" 4 "<0.014 m" 3 "<0.011 m" 2 "<0.008 m" 1 "<0.006 m" 0 "<0.005 m" ;
VAL_ 1874 Cluster_VrelLong_rms 31 "Invalid" 30 "<10.000 m/s" 29 "<7.762 m/s" 28 "<6.025 m/s" 27 "<4.676 m/s" 26 "<3.630 m/s" 25 "<2.817 m/s" 24 "<2.187 m/s" 23 "<1.697 m/s" 22 "<1.317 m/s" 21 "<1.023 m/s" 20 "<0.794 m/s" 19 "<0.616 m/s" 18 "<0.478 m/s" 17 "<0.371 m/s" 16 "<0.288 m/s" 15 "<0.224 m/s" 14 "<0.174 m/s" 13 "<0.135 m/s" 12 "<0.105 m/s" 11 "<0.081 m/s" 10 "<0.063 m/s" 9 "<0.049 m/s" 8 "<0.038 m/s" 7 "<0.029 m/s" 6 "<0.023 m/s" 5 "<0.018 m/s" 4 "<0.014 m/s" 3 "<0.011 m/s" 2 "<0.008 m/s" 1 "<0.006 m/s" 0 "<0.005 m/s" ;
VAL_ 1874 Cluster_PdH0 7 "<=100%" 6 "<99.9%" 5 "<99%" 4 "<90%" 3 "<75%" 2 "<50%" 1 "<25%" 0 "invalid" ;
VAL_ 1874 Cluster_AmbigState 4 "Stationary candidate" 3 "Unambiguous" 2 "Staggered ramp" 1 "Ambiguous" 0 "Invalid" ;
VAL_ 1644 Obj_ProbOfExist 7 "<=100%" 6 "<99.9%" 5 "<99%" 4 "<90%" 3 "<75%" 2 "<50%" 1 "<25%" 0 "invalid" ;
VAL_ 1644 Obj_MeasState 5 "New from merge" 4 "Deleted for merge" 3 "Predicted" 2 "Measured" 1 "New" 0 "Deleted" ;
VAL_ 1644 Obj_ArelLong_rms 31 "Invalid" 30 "<10.000 m/s²" 29 "<7.762 m/s²" 28 "<6.025 m/s²" 27 "<4.676 m/s²" 26 "<3.630 m/s²" 25 "<2.817 m/s²" 24 "<2.187 m/s²" 23 "<1.697 m/s²" 22 "<1.317 m/s²" 21 "<1.023 m/s²" 20 "<0.794 m/s²" 19 "<0.616 m/s²" 18 "<0.478 m/s²" 17 "<0.371 m/s²" 16 "<0.288 m/s²" 15 "<0.224 m/s²" 14 "<0.174 m/s²" 13 "<0.135 m/s²" 12 "<0.105 m/s²" 11 "<0.081 m/s²" 10 "<0.063 m/s²" 9 "<0.049 m/s²" 8 "<0.038 m/s²" 7 "<0.029 m/s²" 6 "<0.023 m/s²" 5 "<0.018 m/s²" 4 "<0.014 m/s²" 3 "<0.011 m/s²" 2 "<0.008 m/s²" 1 "<0.006 m/s²" 0 "<0.005 m/s²" ;
VAL_ 1644 Obj_ArelLat_rms 31 "Invalid" 30 "<10.000 m/s²" 29 "<7.762 m/s²" 28 "<6.025 m/s²" 27 "<4.676 m/s²" 26 "<3.630 m/s²" 25 "<2.817 m/s²" 24 "<2.187 m/s²" 23 "<1.697 m/s²" 22 "<1.317 m/s²" 21 "<1.023 m/s²" 20 "<0.794 m/s²" 19 "<0.616 m/s²" 18 "<0.478 m/s²" 17 "<0.371 m/s²" 16 "<0.288 m/s²" 15 "<0.224 m/s²" 14 "<0.174 m/s²" 13 "<0.135 m/s²" 12 "<0.105 m/s²" 11 "<0.081 m/s²" 10 "<0.063 m/s²" 9 "<0.049 m/s²" 8 "<0.038 m/s²" 7 "<0.029 m/s²" 6 "<0.023 m/s²" 5 "<0.018 m/s²" 4 "<0.014 m/s²" 3 "<0.011 m/s²" 2 "<0.008 m/s²" 1 "<0.006 m/s²" 0 "<0.005 m/s²" ;
VAL_ 1644 Obj_VrelLong_rms 31 "Invalid" 30 "<10.000 m/s" 29 "<7.762 m/s" 28 "<6.025 m/s" 27 "<4.676 m/s" 26 "<3.630 m/s" 25 "<2.817 m/s" 24 "<2.187 m/s" 23 "<1.697 m/s" 22 "<1.317 m/s" 21 "<1.023 m/s" 20 "<0.794 m/s" 19 "<0.616 m/s" 18 "<0.478 m/s" 17 "<0.371 m/s" 16 "<0.288 m/s" 15 "<0.224 m/s" 14 "<0.174 m/s" 13 "<0.135 m/s" 12 "<0.105 m/s" 11 "<0.081 m/s" 10 "<0.063 m/s" 9 "<0.049 m/s" 8 "<0.038 m/s" 7 "<0.029 m/s" 6 "<0.023 m/s" 5 "<0.018 m/s" 4 "<0.014 m/s" 3 "<0.011 m/s" 2 "<0.008 m/s" 1 "<0.006 m/s" 0 "<0.005 m/s" ;
VAL_ 1644 Obj_VrelLat_rms 31 "Invalid" 30 "<10.000 m/s" 29 "<7.762 m/s" 28 "<6.025 m/s" 27 "<4.676 m/s" 26 "<3.630 m/s" 25 "<2.817 m/s" 24 "<2.187 m/s" 23 "<1.697 m/s" 22 "<1.317 m/s" 21 "<1.023 m/s" 20 "<0.794 m/s" 19 "<0.616 m/s" 18 "<0.478 m/s" 17 "<0.371 m/s" 16 "<0.288 m/s" 15 "<0.224 m/s" 14 "<0.174 m/s" 13 "<0.135 m/s" 12 "<0.105 m/s" 11 "<0.081 m/s" 10 "<0.063 m/s" 9 "<0.049 m/s" 8 "<0.038 m/s" 7 "<0.029 m/s" 6 "<0.023 m/s" 5 "<0.018 m/s" 4 "<0.014 m/s" 3 "<0.011 m/s" 2 "<0.008 m/s" 1 "<0.006 m/s" 0 "<0.005 m/s" ;
VAL_ 1644 Obj_Orientation_rms 31 "Invalid" 30 "<180.000 deg" 29 "<126.881 deg" 28 "<89.437 deg" 27 "<63.044 deg" 26 "<44.439 deg" 25 "<31.325 deg" 24 "<22.081 deg" 23 "<15.565 deg" 22 "<10.971 deg" 21 "<7.734 deg" 20 "<5.451 deg" 19 "<3.843 deg" 18 "<2.709 deg" 17 "<1.909 deg" 16 "<1.346 deg" 15 "<0.949 deg" 14 "<0.669 deg" 13 "<0.471 deg" 12 "<0.332 deg" 11 "<0.234 deg" 10 "<0.165 deg" 9 "<0.116 deg" 8 "<0.082 deg" 7 "<0.058 deg" 6 "<0.041 deg" 5 "<0.029 deg" 4 "<0.020 deg" 3 "<0.014 deg" 2 "<0.010 deg" 1 "<0.007 deg" 0 "<0.005 deg" ;
VAL_ 1644 Obj_DistLong_rms 31 "Invalid" 30 "<10.000 m" 29 "<7.762 m" 28 "<6.025 m" 27 "<4.676 m" 26 "<3.630 m" 25 "<2.817 m" 24 "<2.187 m" 23 "<1.697 m" 22 "<1.317 m" 21 "<1.023 m" 20 "<0.794 m" 19 "<0.616 m" 18 "<0.478 m" 17 "<0.371 m" 16 "<0.288 m" 15 "<0.224 m" 14 "<0.174 m" 13 "<0.135 m" 12 "<0.105 m" 11 "<0.081 m" 10 "<0.063 m" 9 "<0.049 m" 8 "<0.038 m" 7 "<0.029 m" 6 "<0.023 m" 5 "<0.018 m" 4 "<0.014 m" 3 "<0.011 m" 2 "<0.008 m" 1 "<0.006 m" 0 "<0.005 m" ;
VAL_ 1644 Obj_DistLat_rms 31 "Invalid" 30 "<10.000 m" 29 "<7.762 m" 28 "<6.025 m" 27 "<4.676 m" 26 "<3.630 m" 25 "<2.817 m" 24 "<2.187 m" 23 "<1.697 m" 22 "<1.317 m" 21 "<1.023 m" 20 "<0.794 m" 19 "<0.616 m" 18 "<0.478 m" 17 "<0.371 m" 16 "<0.288 m" 15 "<0.224 m" 14 "<0.174 m" 13 "<0.135 m" 12 "<0.105 m" 11 "<0.081 m" 10 "<0.063 m" 9 "<0.049 m" 8 "<0.038 m" 7 "<0.029 m" 6 "<0.023 m" 5 "<0.018 m" 4 "<0.014 m" 3 "<0.011 m" 2 "<0.008 m" 1 "<0.006 m" 0 "<0.005 m" ;
VAL_ 1645 Obj_Class 7 "Description for the value '0x7'" 6 "Wide" 5 "Bicycle" 4 "Motorcycle" 3 "Pedestrian" 2 "Truck" 1 "Car" 0 "Point" ;
VAL_ 1122 CollDetRegState_WarningLevel 3 "Warning deactivated" 2 "Preliminary warning" 1 "Object warning" 0 "No warning" ;
VAL_ 612 FilterState_Type 1 "Object filter" 0 "Cluster filter" ;
VAL_ 612 FilterState_Min_ProbExists 7 "100%" 6 ">=99.9%" 5 ">=99%" 4 ">=90%" 3 ">=75%" 2 ">=50%" 1 ">=25%" 0 "invalid" ;
VAL_ 612 FilterState_Max_ProbExists 7 "<=100%" 6 "<99.9%" 5 "<99%" 4 "<90%" 3 "<75%" 2 "<50%" 1 "<25%" 0 "invalid" ;
VAL_ 612 FilterState_Index 15 "Class" 14 "Longitud. velocity for departing" 13 "Lateral velocity for right-left" 12 "Longitud. velocity for oncoming" 11 "Lateral velocity for left-right" 10 "Longitudinal distance" 9 "Lateral distance" 8 "Probability of existence" 7 "Size" 6 "Lifetime" 5 "RCS" 4 "Radial velocity for departing" 3 "Radial velocity for oncoming" 2 "Azimuth" 1 "Radial distance" 0 "Number of objects" ;
VAL_ 612 FilterState_Active 1 "active" 0 "inactive" ;
VAL_ 610 FilterCfg_Valid 1 "valid" 0 "invalid" ;
VAL_ 610 FilterCfg_Active 1 "active" 0 "inactive" ;
VAL_ 610 FilterCfg_Max_ProbExists 7 "<=100%" 6 "<99.9%" 5 "<99%" 4 "<90%" 3 "<75%" 2 "<50%" 1 "<25%" 0 "invalid" ;
VAL_ 610 FilterCfg_Min_ProbExists 7 "100%" 6 ">=99.9%" 5 ">=99%" 4 ">=90%" 3 ">=75%" 2 ">=50%" 1 ">=25%" 0 "invalid" ;
VAL_ 610 FilterCfg_Index 15 "Class" 14 "Longitud. velocity for departing" 13 "Lateral velocity for right-left" 12 "Longitud. velocity for oncoming" 11 "Lateral velocity for left-right" 10 "Longitudinal distance" 9 "Lateral distance" 8 "Probability of existence" 7 "Size" 6 "Lifetime" 5 "RCS" 4 "Radial velocity for departing" 3 "Radial velocity for oncoming" 2 "Azimuth" 1 "Radial distance" 0 "Number of objects" ;
VAL_ 610 FilterCfg_Type 1 "Object filter" 0 "Cluster filter" ;
VAL_ 608 RadarCfg_RCS_Threshold_Valid 1 "Valid" 0 "Invalid" ;
VAL_ 608 RadarCfg_RCS_Threshold 7 "Reserved" 6 "Reserved" 5 "Reserved" 4 "Reserved" 3 "Reserved" 2 "Reserved" 1 "High Sensitivity" 0 "Standard" ;
VAL_ 608 RadarCfg_StoreInNVM_valid 1 "Valid" 0 "Invalid" ;
VAL_ 608 RadarCfg_SortIndex_valid 1 "Valid" 0 "Invalid" ;
VAL_ 608 RadarCfg_SortIndex 2 "Sorted by RCS" 1 "Sorted by range" 0 "No sorting" ;
VAL_ 608 RadarCfg_StoreInNVM 1 "Active" 0 "Inactive" ;
VAL_ 608 RadarCfg_SendExtInfo_valid 1 "Valid" 0 "Invalid" ;
VAL_ 608 RadarCfg_SendExtInfo 1 "Active" 0 "Inactive" ;
VAL_ 608 RadarCfg_CtrlRelay_valid 1 "Valid" 0 "Invalid" ;
VAL_ 608 RadarCfg_CtrlRelay 1 "Active" 0 "Inactive" ;
VAL_ 608 RadarCfg_SendQuality_valid 1 "Valid" 0 "Invalid" ;
VAL_ 608 RadarCfg_SendQuality 1 "Active" 0 "Inactive" ;
VAL_ 608 RadarCfg_MaxDistance_valid 1 "Valid" 0 "Invalid" ;
VAL_ 608 RadarCfg_RadarPower_valid 1 "Valid" 0 "Invalid" ;
VAL_ 608 RadarCfg_OutputType_valid 1 "Valid" 0 "Invalid" ;
VAL_ 608 RadarCfg_SensorID_valid 1 "Valid" 0 "Invalid" ;
VAL_ 608 RadarCfg_RadarPower 7 "Reserved" 6 "Reserved" 5 "Reserved" 4 "Reserved" 3 "-9 dB Tx gain" 2 "-6 dB Tx gain" 1 "-3 dB Tx gain" 0 "Standard" ;
VAL_ 608 RadarCfg_OutputType 3 "reserved 2" 2 "SendClusters" 1 "SendObjects" 0 "None" ;
VAL_ 609 RadarState_RCS_Threshold 7 "Reserved" 6 "Reserved" 5 "Reserved" 4 "Reserved" 3 "Reserved" 2 "Reserved" 1 "High Sensitivity" 0 "Standard" ;
VAL_ 609 RadarState_CtrlRelayCfg 1 "Active" 0 "Inactive" ;
VAL_ 609 RadarState_SendQualityCfg 1 "Active" 0 "Inactive" ;
VAL_ 609 RadarState_SendExtInfoCfg 1 "Active" 0 "Inactive" ;
VAL_ 609 RadarState_MotionRxState 3 "Speed and yaw rate missing" 2 "Yaw rate missing" 1 "Speed missing" 0 "Input ok" ;
VAL_ 609 RadarState_OutputTypeCfg 3 "reserved 2" 2 "SendClusters" 1 "SendObjects" 0 "None" ;
VAL_ 609 RadarState_RadarPowerCfg 7 "Reserved" 6 "Reserved" 5 "Reserved" 4 "Reserved" 3 "-9 dB Tx gain" 2 "-6 dB Tx gain" 1 "-3 dB Tx gain" 0 "Standard" ;
VAL_ 609 RadarState_NVMReadStatus 1 "successful" 0 "pending" ;
VAL_ 609 RadarState_NVMwriteStatus 1 "successful" 0 "failed" ;
VAL_ 864 RadarDevice_SpeedDirection 3 "reserved" 2 "reverse" 1 "forward" 0 "standstill" ;
VAL_ 1120 CollDetCfg_ClearRegions 1 "Clear all defined regions" 0 "Idle" ;
VAL_ 1120 CollDetCfg_WarningReset 1 "Warn reset" 0 "Idle" ;
VAL_ 1120 CollDetCfg_Activate 1 "Active" 0 "Inactive" ;
VAL_ 1120 CollDetCfg_MinTime_valid 1 "Valid" 0 "Invalid" ;
VAL_ 1121 CollDetRegCfg_Activate 1 "Active" 0 "Inactive" ;
VAL_ 1121 CollDetRegCfg_Coordinates_valid 1 "Valid" 0 "Invalid" ;
VAL_ 1128 CollDetState_Active 1 "Active" 0 "Inactive" ;
VAL_ 1643 Obj_DynProp 7 "Stopped" 6 "Crossing moving" 5 "Crossing stationary" 4 "Unknown" 3 "Stationary candidate" 2 "Oncoming" 1 "Stationary" 0 "Moving" ;
VAL_ 1889 Cluster_DynProp 7 "Stopped" 6 "Crossing moving" 5 "Crossing stationary" 4 "Unknown" 3 "Stationary candidate" 2 "Oncoming" 1 "Stationary" 0 "Moving" ;
VAL_ 1890 Cluster_VrelLat_rms 31 "Invalid" 30 "<10.000 m/s" 29 "<7.762 m/s" 28 "<6.025 m/s" 27 "<4.676 m/s" 26 "<3.630 m/s" 25 "<2.817 m/s" 24 "<2.187 m/s" 23 "<1.697 m/s" 22 "<1.317 m/s" 21 "<1.023 m/s" 20 "<0.794 m/s" 19 "<0.616 m/s" 18 "<0.478 m/s" 17 "<0.371 m/s" 16 "<0.288 m/s" 15 "<0.224 m/s" 14 "<0.174 m/s" 13 "<0.135 m/s" 12 "<0.105 m/s" 11 "<0.081 m/s" 10 "<0.063 m/s" 9 "<0.049 m/s" 8 "<0.038 m/s" 7 "<0.029 m/s" 6 "<0.023 m/s" 5 "<0.018 m/s" 4 "<0.014 m/s" 3 "<0.011 m/s" 2 "<0.008 m/s" 1 "<0.006 m/s" 0 "<0.005 m/s" ;
VAL_ 1890 Cluster_InvalidState 17 "Valid suspicious angle" 16 "Valid multi-target" 15 "Valid near above 95 m" 14 "Invalid harmonics " 13 "reserved" 12 "Valid artefact " 11 "Valid but no local maximum" 10 "Valid 50 deg artefact" 9 "Valid child" 8 "Valid with elevation" 7 "Invalid outside field of view" 6 "Invalid mirror" 5 "reserved" 4 "Valid with low RCS" 3 "Invalid far not confirmed" 2 "Invalid nearfield" 1 "Invalid with too low RCS" 0 "Valid" ;
VAL_ 1890 Cluster_DistLat_rms 31 "Invalid" 30 "<10.000 m" 29 "<7.762 m" 28 "<6.025 m" 27 "<4.676 m" 26 "<3.630 m" 25 "<2.817 m" 24 "<2.187 m" 23 "<1.697 m" 22 "<1.317 m" 21 "<1.023 m" 20 "<0.794 m" 19 "<0.616 m" 18 "<0.478 m" 17 "<0.371 m" 16 "<0.288 m" 15 "<0.224 m" 14 "<0.174 m" 13 "<0.135 m" 12 "<0.105 m" 11 "<0.081 m" 10 "<0.063 m" 9 "<0.049 m" 8 "<0.038 m" 7 "<0.029 m" 6 "<0.023 m" 5 "<0.018 m" 4 "<0.014 m" 3 "<0.011 m" 2 "<0.008 m" 1 "<0.006 m" 0 "<0.005 m" ;
VAL_ 1890 Cluster_DistLong_rms 31 "Invalid" 30 "<10.000 m" 29 "<7.762 m" 28 "<6.025 m" 27 "<4.676 m" 26 "<3.630 m" 25 "<2.817 m" 24 "<2.187 m" 23 "<1.697 m" 22 "<1.317 m" 21 "<1.023 m" 20 "<0.794 m" 19 "<0.616 m" 18 "<0.478 m" 17 "<0.371 m" 16 "<0.288 m" 15 "<0.224 m" 14 "<0.174 m" 13 "<0.135 m" 12 "<0.105 m" 11 "<0.081 m" 10 "<0.063 m" 9 "<0.049 m" 8 "<0.038 m" 7 "<0.029 m" 6 "<0.023 m" 5 "<0.018 m" 4 "<0.014 m" 3 "<0.011 m" 2 "<0.008 m" 1 "<0.006 m" 0 "<0.005 m" ;
VAL_ 1890 Cluster_VrelLong_rms 31 "Invalid" 30 "<10.000 m/s" 29 "<7.762 m/s" 28 "<6.025 m/s" 27 "<4.676 m/s" 26 "<3.630 m/s" 25 "<2.817 m/s" 24 "<2.187 m/s" 23 "<1.697 m/s" 22 "<1.317 m/s" 21 "<1.023 m/s" 20 "<0.794 m/s" 19 "<0.616 m/s" 18 "<0.478 m/s" 17 "<0.371 m/s" 16 "<0.288 m/s" 15 "<0.224 m/s" 14 "<0.174 m/s" 13 "<0.135 m/s" 12 "<0.105 m/s" 11 "<0.081 m/s" 10 "<0.063 m/s" 9 "<0.049 m/s" 8 "<0.038 m/s" 7 "<0.029 m/s" 6 "<0.023 m/s" 5 "<0.018 m/s" 4 "<0.014 m/s" 3 "<0.011 m/s" 2 "<0.008 m/s" 1 "<0.006 m/s" 0 "<0.005 m/s" ;
VAL_ 1890 Cluster_PdH0 7 "<=100%" 6 "<99.9%" 5 "<99%" 4 "<90%" 3 "<75%" 2 "<50%" 1 "<25%" 0 "invalid" ;
VAL_ 1890 Cluster_AmbigState 4 "Stationary candidate" 3 "Unambiguous" 2 "Staggered ramp" 1 "Ambiguous" 0 "Invalid" ;
VAL_ 1660 Obj_ProbOfExist 7 "<=100%" 6 "<99.9%" 5 "<99%" 4 "<90%" 3 "<75%" 2 "<50%" 1 "<25%" 0 "invalid" ;
VAL_ 1660 Obj_MeasState 5 "New from merge" 4 "Deleted for merge" 3 "Predicted" 2 "Measured" 1 "New" 0 "Deleted" ;
VAL_ 1660 Obj_ArelLong_rms 31 "Invalid" 30 "<10.000 m/s²" 29 "<7.762 m/s²" 28 "<6.025 m/s²" 27 "<4.676 m/s²" 26 "<3.630 m/s²" 25 "<2.817 m/s²" 24 "<2.187 m/s²" 23 "<1.697 m/s²" 22 "<1.317 m/s²" 21 "<1.023 m/s²" 20 "<0.794 m/s²" 19 "<0.616 m/s²" 18 "<0.478 m/s²" 17 "<0.371 m/s²" 16 "<0.288 m/s²" 15 "<0.224 m/s²" 14 "<0.174 m/s²" 13 "<0.135 m/s²" 12 "<0.105 m/s²" 11 "<0.081 m/s²" 10 "<0.063 m/s²" 9 "<0.049 m/s²" 8 "<0.038 m/s²" 7 "<0.029 m/s²" 6 "<0.023 m/s²" 5 "<0.018 m/s²" 4 "<0.014 m/s²" 3 "<0.011 m/s²" 2 "<0.008 m/s²" 1 "<0.006 m/s²" 0 "<0.005 m/s²" ;
VAL_ 1660 Obj_ArelLat_rms 31 "Invalid" 30 "<10.000 m/s²" 29 "<7.762 m/s²" 28 "<6.025 m/s²" 27 "<4.676 m/s²" 26 "<3.630 m/s²" 25 "<2.817 m/s²" 24 "<2.187 m/s²" 23 "<1.697 m/s²" 22 "<1.317 m/s²" 21 "<1.023 m/s²" 20 "<0.794 m/s²" 19 "<0.616 m/s²" 18 "<0.478 m/s²" 17 "<0.371 m/s²" 16 "<0.288 m/s²" 15 "<0.224 m/s²" 14 "<0.174 m/s²" 13 "<0.135 m/s²" 12 "<0.105 m/s²" 11 "<0.081 m/s²" 10 "<0.063 m/s²" 9 "<0.049 m/s²" 8 "<0.038 m/s²" 7 "<0.029 m/s²" 6 "<0.023 m/s²" 5 "<0.018 m/s²" 4 "<0.014 m/s²" 3 "<0.011 m/s²" 2 "<0.008 m/s²" 1 "<0.006 m/s²" 0 "<0.005 m/s²" ;
VAL_ 1660 Obj_VrelLong_rms 31 "Invalid" 30 "<10.000 m/s" 29 "<7.762 m/s" 28 "<6.025 m/s" 27 "<4.676 m/s" 26 "<3.630 m/s" 25 "<2.817 m/s" 24 "<2.187 m/s" 23 "<1.697 m/s" 22 "<1.317 m/s" 21 "<1.023 m/s" 20 "<0.794 m/s" 19 "<0.616 m/s" 18 "<0.478 m/s" 17 "<0.371 m/s" 16 "<0.288 m/s" 15 "<0.224 m/s" 14 "<0.174 m/s" 13 "<0.135 m/s" 12 "<0.105 m/s" 11 "<0.081 m/s" 10 "<0.063 m/s" 9 "<0.049 m/s" 8 "<0.038 m/s" 7 "<0.029 m/s" 6 "<0.023 m/s" 5 "<0.018 m/s" 4 "<0.014 m/s" 3 "<0.011 m/s" 2 "<0.008 m/s" 1 "<0.006 m/s" 0 "<0.005 m/s" ;
VAL_ 1660 Obj_VrelLat_rms 31 "Invalid" 30 "<10.000 m/s" 29 "<7.762 m/s" 28 "<6.025 m/s" 27 "<4.676 m/s" 26 "<3.630 m/s" 25 "<2.817 m/s" 24 "<2.187 m/s" 23 "<1.697 m/s" 22 "<1.317 m/s" 21 "<1.023 m/s" 20 "<0.794 m/s" 19 "<0.616 m/s" 18 "<0.478 m/s" 17 "<0.371 m/s" 16 "<0.288 m/s" 15 "<0.224 m/s" 14 "<0.174 m/s" 13 "<0.135 m/s" 12 "<0.105 m/s" 11 "<0.081 m/s" 10 "<0.063 m/s" 9 "<0.049 m/s" 8 "<0.038 m/s" 7 "<0.029 m/s" 6 "<0.023 m/s" 5 "<0.018 m/s" 4 "<0.014 m/s" 3 "<0.011 m/s" 2 "<0.008 m/s" 1 "<0.006 m/s" 0 "<0.005 m/s" ;
VAL_ 1660 Obj_Orientation_rms 31 "Invalid" 30 "<180.000 deg" 29 "<126.881 deg" 28 "<89.437 deg" 27 "<63.044 deg" 26 "<44.439 deg" 25 "<31.325 deg" 24 "<22.081 deg" 23 "<15.565 deg" 22 "<10.971 deg" 21 "<7.734 deg" 20 "<5.451 deg" 19 "<3.843 deg" 18 "<2.709 deg" 17 "<1.909 deg" 16 "<1.346 deg" 15 "<0.949 deg" 14 "<0.669 deg" 13 "<0.471 deg" 12 "<0.332 deg" 11 "<0.234 deg" 10 "<0.165 deg" 9 "<0.116 deg" 8 "<0.082 deg" 7 "<0.058 deg" 6 "<0.041 deg" 5 "<0.029 deg" 4 "<0.020 deg" 3 "<0.014 deg" 2 "<0.010 deg" 1 "<0.007 deg" 0 "<0.005 deg" ;
VAL_ 1660 Obj_DistLong_rms 31 "Invalid" 30 "<10.000 m" 29 "<7.762 m" 28 "<6.025 m" 27 "<4.676 m" 26 "<3.630 m" 25 "<2.817 m" 24 "<2.187 m" 23 "<1.697 m" 22 "<1.317 m" 21 "<1.023 m" 20 "<0.794 m" 19 "<0.616 m" 18 "<0.478 m" 17 "<0.371 m" 16 "<0.288 m" 15 "<0.224 m" 14 "<0.174 m" 13 "<0.135 m" 12 "<0.105 m" 11 "<0.081 m" 10 "<0.063 m" 9 "<0.049 m" 8 "<0.038 m" 7 "<0.029 m" 6 "<0.023 m" 5 "<0.018 m" 4 "<0.014 m" 3 "<0.011 m" 2 "<0.008 m" 1 "<0.006 m" 0 "<0.005 m" ;
VAL_ 1660 Obj_DistLat_rms 31 "Invalid" 30 "<10.000 m" 29 "<7.762 m" 28 "<6.025 m" 27 "<4.676 m" 26 "<3.630 m" 25 "<2.817 m" 24 "<2.187 m" 23 "<1.697 m" 22 "<1.317 m" 21 "<1.023 m" 20 "<0.794 m" 19 "<0.616 m" 18 "<0.478 m" 17 "<0.371 m" 16 "<0.288 m" 15 "<0.224 m" 14 "<0.174 m" 13 "<0.135 m" 12 "<0.105 m" 11 "<0.081 m" 10 "<0.063 m" 9 "<0.049 m" 8 "<0.038 m" 7 "<0.029 m" 6 "<0.023 m" 5 "<0.018 m" 4 "<0.014 m" 3 "<0.011 m" 2 "<0.008 m" 1 "<0.006 m" 0 "<0.005 m" ;
VAL_ 1661 Obj_Class 7 "Description for the value '0x7'" 6 "Wide" 5 "Bicycle" 4 "Motorcycle" 3 "Pedestrian" 2 "Truck" 1 "Car" 0 "Point" ;
VAL_ 1138 CollDetRegState_WarningLevel 3 "Warning deactivated" 2 "Preliminary warning" 1 "Object warning" 0 "No warning" ;
VAL_ 628 FilterState_Type 1 "Object filter" 0 "Cluster filter" ;
VAL_ 628 FilterState_Min_ProbExists 7 "100%" 6 ">=99.9%" 5 ">=99%" 4 ">=90%" 3 ">=75%" 2 ">=50%" 1 ">=25%" 0 "invalid" ;
VAL_ 628 FilterState_Max_ProbExists 7 "<=100%" 6 "<99.9%" 5 "<99%" 4 "<90%" 3 "<75%" 2 "<50%" 1 "<25%" 0 "invalid" ;
VAL_ 628 FilterState_Index 15 "Class" 14 "Longitud. velocity for departing" 13 "Lateral velocity for right-left" 12 "Longitud. velocity for oncoming" 11 "Lateral velocity for left-right" 10 "Longitudinal distance" 9 "Lateral distance" 8 "Probability of existence" 7 "Size" 6 "Lifetime" 5 "RCS" 4 "Radial velocity for departing" 3 "Radial velocity for oncoming" 2 "Azimuth" 1 "Radial distance" 0 "Number of objects" ;
VAL_ 628 FilterState_Active 1 "active" 0 "inactive" ;
VAL_ 626 FilterCfg_Valid 1 "valid" 0 "invalid" ;
VAL_ 626 FilterCfg_Active 1 "active" 0 "inactive" ;
VAL_ 626 FilterCfg_Max_ProbExists 7 "<=100%" 6 "<99.9%" 5 "<99%" 4 "<90%" 3 "<75%" 2 "<50%" 1 "<25%" 0 "invalid" ;
VAL_ 626 FilterCfg_Min_ProbExists 7 "100%" 6 ">=99.9%" 5 ">=99%" 4 ">=90%" 3 ">=75%" 2 ">=50%" 1 ">=25%" 0 "invalid" ;
VAL_ 626 FilterCfg_Index 15 "Class" 14 "Longitud. velocity for departing" 13 "Lateral velocity for right-left" 12 "Longitud. velocity for oncoming" 11 "Lateral velocity for left-right" 10 "Longitudinal distance" 9 "Lateral distance" 8 "Probability of existence" 7 "Size" 6 "Lifetime" 5 "RCS" 4 "Radial velocity for departing" 3 "Radial velocity for oncoming" 2 "Azimuth" 1 "Radial distance" 0 "Number of objects" ;
VAL_ 626 FilterCfg_Type 1 "Object filter" 0 "Cluster filter" ;
VAL_ 624 RadarCfg_RCS_Threshold_Valid 1 "Valid" 0 "Invalid" ;
VAL_ 624 RadarCfg_RCS_Threshold 7 "Reserved" 6 "Reserved" 5 "Reserved" 4 "Reserved" 3 "Reserved" 2 "Reserved" 1 "High Sensitivity" 0 "Standard" ;
VAL_ 624 RadarCfg_StoreInNVM_valid 1 "Valid" 0 "Invalid" ;
VAL_ 624 RadarCfg_SortIndex_valid 1 "Valid" 0 "Invalid" ;
VAL_ 624 RadarCfg_SortIndex 2 "Sorted by RCS" 1 "Sorted by range" 0 "No sorting" ;
VAL_ 624 RadarCfg_StoreInNVM 1 "Active" 0 "Inactive" ;
VAL_ 624 RadarCfg_SendExtInfo_valid 1 "Valid" 0 "Invalid" ;
VAL_ 624 RadarCfg_SendExtInfo 1 "Active" 0 "Inactive" ;
VAL_ 624 RadarCfg_CtrlRelay_valid 1 "Valid" 0 "Invalid" ;
VAL_ 624 RadarCfg_CtrlRelay 1 "Active" 0 "Inactive" ;
VAL_ 624 RadarCfg_SendQuality_valid 1 "Valid" 0 "Invalid" ;
VAL_ 624 RadarCfg_SendQuality 1 "Active" 0 "Inactive" ;
VAL_ 624 RadarCfg_MaxDistance_valid 1 "Valid" 0 "Invalid" ;
VAL_ 624 RadarCfg_RadarPower_valid 1 "Valid" 0 "Invalid" ;
VAL_ 624 RadarCfg_OutputType_valid 1 "Valid" 0 "Invalid" ;
VAL_ 624 RadarCfg_SensorID_valid 1 "Valid" 0 "Invalid" ;
VAL_ 624 RadarCfg_RadarPower 7 "Reserved" 6 "Reserved" 5 "Reserved" 4 "Reserved" 3 "-9 dB Tx gain" 2 "-6 dB Tx gain" 1 "-3 dB Tx gain" 0 "Standard" ;
VAL_ 624 RadarCfg_OutputType 3 "reserved 2" 2 "SendClusters" 1 "SendObjects" 0 "None" ;
VAL_ 625 RadarState_RCS_Threshold 7 "Reserved" 6 "Reserved" 5 "Reserved" 4 "Reserved" 3 "Reserved" 2 "Reserved" 1 "High Sensitivity" 0 "Standard" ;
VAL_ 625 RadarState_CtrlRelayCfg 1 "Active" 0 "Inactive" ;
VAL_ 625 RadarState_SendQualityCfg 1 "Active" 0 "Inactive" ;
VAL_ 625 RadarState_SendExtInfoCfg 1 "Active" 0 "Inactive" ;
VAL_ 625 RadarState_MotionRxState 3 "Speed and yaw rate missing" 2 "Yaw rate missing" 1 "Speed missing" 0 "Input ok" ;
VAL_ 625 RadarState_OutputTypeCfg 3 "reserved 2" 2 "SendClusters" 1 "SendObjects" 0 "None" ;
VAL_ 625 RadarState_RadarPowerCfg 7 "Reserved" 6 "Reserved" 5 "Reserved" 4 "Reserved" 3 "-9 dB Tx gain" 2 "-6 dB Tx gain" 1 "-3 dB Tx gain" 0 "Standard" ;
VAL_ 625 RadarState_NVMReadStatus 1 "successful" 0 "pending" ;
VAL_ 625 RadarState_NVMwriteStatus 1 "successful" 0 "failed" ;
VAL_ 880 RadarDevice_SpeedDirection 3 "reserved" 2 "reverse" 1 "forward" 0 "standstill" ;
VAL_ 1136 CollDetCfg_ClearRegions 1 "Clear all defined regions" 0 "Idle" ;
VAL_ 1136 CollDetCfg_WarningReset 1 "Warn reset" 0 "Idle" ;
VAL_ 1136 CollDetCfg_Activate 1 "Active" 0 "Inactive" ;
VAL_ 1136 CollDetCfg_MinTime_valid 1 "Valid" 0 "Invalid" ;
VAL_ 1137 CollDetRegCfg_Activate 1 "Active" 0 "Inactive" ;
VAL_ 1137 CollDetRegCfg_Coordinates_valid 1 "Valid" 0 "Invalid" ;
VAL_ 1144 CollDetState_Active 1 "Active" 0 "Inactive" ;
VAL_ 1659 Obj_DynProp 7 "Stopped" 6 "Crossing moving" 5 "Crossing stationary" 4 "Unknown" 3 "Stationary candidate" 2 "Oncoming" 1 "Stationary" 0 "Moving" ;
VAL_ 1905 Cluster_DynProp 7 "Stopped" 6 "Crossing moving" 5 "Crossing stationary" 4 "Unknown" 3 "Stationary candidate" 2 "Oncoming" 1 "Stationary" 0 "Moving" ;
VAL_ 1906 Cluster_VrelLat_rms 31 "Invalid" 30 "<10.000 m/s" 29 "<7.762 m/s" 28 "<6.025 m/s" 27 "<4.676 m/s" 26 "<3.630 m/s" 25 "<2.817 m/s" 24 "<2.187 m/s" 23 "<1.697 m/s" 22 "<1.317 m/s" 21 "<1.023 m/s" 20 "<0.794 m/s" 19 "<0.616 m/s" 18 "<0.478 m/s" 17 "<0.371 m/s" 16 "<0.288 m/s" 15 "<0.224 m/s" 14 "<0.174 m/s" 13 "<0.135 m/s" 12 "<0.105 m/s" 11 "<0.081 m/s" 10 "<0.063 m/s" 9 "<0.049 m/s" 8 "<0.038 m/s" 7 "<0.029 m/s" 6 "<0.023 m/s" 5 "<0.018 m/s" 4 "<0.014 m/s" 3 "<0.011 m/s" 2 "<0.008 m/s" 1 "<0.006 m/s" 0 "<0.005 m/s" ;
VAL_ 1906 Cluster_InvalidState 17 "Valid suspicious angle" 16 "Valid multi-target" 15 "Valid near above 95 m" 14 "Invalid harmonics " 13 "reserved" 12 "Valid artefact " 11 "Valid but no local maximum" 10 "Valid 50 deg artefact" 9 "Valid child" 8 "Valid with elevation" 7 "Invalid outside field of view" 6 "Invalid mirror" 5 "reserved" 4 "Valid with low RCS" 3 "Invalid far not confirmed" 2 "Invalid nearfield" 1 "Invalid with too low RCS" 0 "Valid" ;
VAL_ 1906 Cluster_DistLat_rms 31 "Invalid" 30 "<10.000 m" 29 "<7.762 m" 28 "<6.025 m" 27 "<4.676 m" 26 "<3.630 m" 25 "<2.817 m" 24 "<2.187 m" 23 "<1.697 m" 22 "<1.317 m" 21 "<1.023 m" 20 "<0.794 m" 19 "<0.616 m" 18 "<0.478 m" 17 "<0.371 m" 16 "<0.288 m" 15 "<0.224 m" 14 "<0.174 m" 13 "<0.135 m" 12 "<0.105 m" 11 "<0.081 m" 10 "<0.063 m" 9 "<0.049 m" 8 "<0.038 m" 7 "<0.029 m" 6 "<0.023 m" 5 "<0.018 m" 4 "<0.014 m" 3 "<0.011 m" 2 "<0.008 m" 1 "<0.006 m" 0 "<0.005 m" ;
VAL_ 1906 Cluster_DistLong_rms 31 "Invalid" 30 "<10.000 m" 29 "<7.762 m" 28 "<6.025 m" 27 "<4.676 m" 26 "<3.630 m" 25 "<2.817 m" 24 "<2.187 m" 23 "<1.697 m" 22 "<1.317 m" 21 "<1.023 m" 20 "<0.794 m" 19 "<0.616 m" 18 "<0.478 m" 17 "<0.371 m" 16 "<0.288 m" 15 "<0.224 m" 14 "<0.174 m" 13 "<0.135 m" 12 "<0.105 m" 11 "<0.081 m" 10 "<0.063 m" 9 "<0.049 m" 8 "<0.038 m" 7 "<0.029 m" 6 "<0.023 m" 5 "<0.018 m" 4 "<0.014 m" 3 "<0.011 m" 2 "<0.008 m" 1 "<0.006 m" 0 "<0.005 m" ;
VAL_ 1906 Cluster_VrelLong_rms 31 "Invalid" 30 "<10.000 m/s" 29 "<7.762 m/s" 28 "<6.025 m/s" 27 "<4.676 m/s" 26 "<3.630 m/s" 25 "<2.817 m/s" 24 "<2.187 m/s" 23 "<1.697 m/s" 22 "<1.317 m/s" 21 "<1.023 m/s" 20 "<0.794 m/s" 19 "<0.616 m/s" 18 "<0.478 m/s" 17 "<0.371 m/s" 16 "<0.288 m/s" 15 "<0.224 m/s" 14 "<0.174 m/s" 13 "<0.135 m/s" 12 "<0.105 m/s" 11 "<0.081 m/s" 10 "<0.063 m/s" 9 "<0.049 m/s" 8 "<0.038 m/s" 7 "<0.029 m/s" 6 "<0.023 m/s" 5 "<0.018 m/s" 4 "<0.014 m/s" 3 "<0.011 m/s" 2 "<0.008 m/s" 1 "<0.006 m/s" 0 "<0.005 m/s" ;
VAL_ 1906 Cluster_PdH0 7 "<=100%" 6 "<99.9%" 5 "<99%" 4 "<90%" 3 "<75%" 2 "<50%" 1 "<25%" 0 "invalid" ;
VAL_ 1906 Cluster_AmbigState 4 "Stationary candidate" 3 "Unambiguous" 2 "Staggered ramp" 1 "Ambiguous" 0 "Invalid" ;
